VERSION "HNNBNNNYNNNNNNNNNNNNNNNNNNNNNNNNNNNNNNNNNN/4/%%%/4/'%**4NNN///"

NS_ :

BS_:

BU_: AEM BAP_Tester E_Sound FBK FLA Gateway Gateway_PAG ISE MRR_HL MRR_HR NightVision RDK SAK SAK2 SCR STH_MLBevo TopView

BO_ 1529 RDK_02: 8 RDK
 SG_ RDK_FMVSS138_Lampe : 12|1@1+ (1.0,0.0) [0.0|1] ""  Gateway,Gateway_PAG
 SG_ RDK_FMVSS138_MIL : 13|1@1+ (1.0,0.0) [0.0|1] ""  Gateway,Gateway_PAG
 SG_ RDK_Kalibrierung : 14|1@1+ (1.0,0.0) [0.0|1] ""  Gateway,Gateway_PAG
 SG_ RDK_Reifendruck_Lampe : 15|1@1+ (1.0,0.0) [0.0|1] ""  Gateway,Gateway_PAG
 SG_ RDK_Warnungen_02 : 16|5@1+ (1.0,0.0) [0.0|31] ""  Gateway,Gateway_PAG
 SG_ RDK_angelernt : 22|1@1+ (1.0,0.0) [0.0|1] ""  Gateway,Gateway_PAG
 SG_ RDK_Reifentemperatur_Lampe : 23|1@1+ (1.0,0.0) [0.0|1] ""  Gateway,Gateway_PAG
 SG_ RDK_RS_aktiv : 24|1@1+ (1.0,0.0) [0.0|1] ""  Gateway,Gateway_PAG
 SG_ RDK_Text_7 : 25|1@1+ (1.0,0.0) [0.0|1] ""  Gateway,Gateway_PAG
 SG_ RDK_W_1_Reifen_HL : 56|1@1+ (1.0,0.0) [0.0|1] ""  Gateway,Gateway_PAG
 SG_ RDK_W_1_Reifen_HR : 57|1@1+ (1.0,0.0) [0.0|1] ""  Gateway,Gateway_PAG
 SG_ RDK_W_1_Reifen_VL : 58|1@1+ (1.0,0.0) [0.0|1] ""  Gateway,Gateway_PAG
 SG_ RDK_W_1_Reifen_VR : 59|1@1+ (1.0,0.0) [0.0|1] ""  Gateway,Gateway_PAG
 SG_ RDK_W_2_Reifen_HL : 60|1@1+ (1.0,0.0) [0.0|1] ""  Gateway,Gateway_PAG
 SG_ RDK_W_2_Reifen_HR : 61|1@1+ (1.0,0.0) [0.0|1] ""  Gateway,Gateway_PAG
 SG_ RDK_W_2_Reifen_VL : 62|1@1+ (1.0,0.0) [0.0|1] ""  Gateway,Gateway_PAG
 SG_ RDK_W_2_Reifen_VR : 63|1@1+ (1.0,0.0) [0.0|1] ""  Gateway,Gateway_PAG

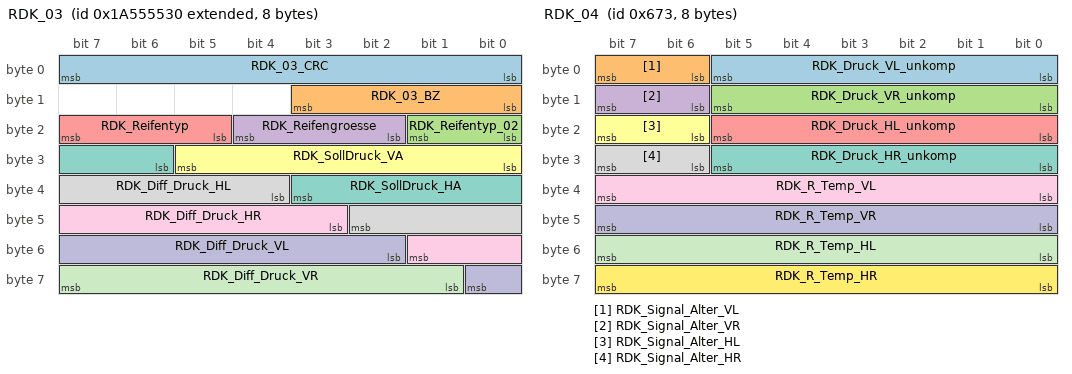
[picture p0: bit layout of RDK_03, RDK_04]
BO_ 2589283632 RDK_03: 8 RDK
 SG_ RDK_03_CRC : 0|8@1+ (1,0) [0|255] ""  Gateway,Gateway_PAG
 SG_ RDK_03_BZ : 8|4@1+ (1,0) [0|15] ""  Gateway,Gateway_PAG
 SG_ RDK_Reifentyp_02 : 16|2@1+ (1.0,0.0) [0.0|3] ""  Gateway,Gateway_PAG
 SG_ RDK_Reifengroesse : 18|3@1+ (1.0,0.0) [0.0|7] ""  Gateway,Gateway_PAG
 SG_ RDK_Reifentyp : 21|3@1+ (1.0,0.0) [0.0|7] ""  Gateway,Gateway_PAG
 SG_ RDK_SollDruck_VA : 24|6@1+ (0.1,0) [0.0|6.2] "Unit_Bar"  Gateway,Gateway_PAG
 SG_ RDK_SollDruck_HA : 30|6@1+ (0.1,0) [0.0|6.2] "Unit_Bar"  Gateway,Gateway_PAG
 SG_ RDK_Diff_Druck_HL : 36|7@1+ (0.1,-6.3) [-6.3|6.3] "Unit_Bar"  Gateway,Gateway_PAG
 SG_ RDK_Diff_Druck_HR : 43|7@1+ (0.1,-6.3) [-6.3|6.3] "Unit_Bar"  Gateway,Gateway_PAG
 SG_ RDK_Diff_Druck_VL : 50|7@1+ (0.1,-6.3) [-6.3|6.3] "Unit_Bar"  Gateway,Gateway_PAG
 SG_ RDK_Diff_Druck_VR : 57|7@1+ (0.1,-6.3) [-6.3|6.3] "Unit_Bar"  Gateway,Gateway_PAG

BO_ 1651 RDK_04: 8 RDK
 SG_ RDK_Druck_VL_unkomp : 0|6@1+ (0.1,0) [0.0|6.2] "Unit_Bar"  Gateway,Gateway_PAG
 SG_ RDK_Signal_Alter_VL : 6|2@1+ (1.0,0.0) [0.0|3] ""  Gateway,Gateway_PAG
 SG_ RDK_Druck_VR_unkomp : 8|6@1+ (0.1,0) [0.0|6.2] "Unit_Bar"  Gateway,Gateway_PAG
 SG_ RDK_Signal_Alter_VR : 14|2@1+ (1.0,0.0) [0.0|3] ""  Gateway,Gateway_PAG
 SG_ RDK_Druck_HL_unkomp : 16|6@1+ (0.1,0) [0.0|6.2] "Unit_Bar"  Gateway,Gateway_PAG
 SG_ RDK_Signal_Alter_HL : 22|2@1+ (1.0,0.0) [0.0|3] ""  Gateway,Gateway_PAG
 SG_ RDK_Druck_HR_unkomp : 24|6@1+ (0.1,0) [0.0|6.2] "Unit_Bar"  Gateway,Gateway_PAG
 SG_ RDK_Signal_Alter_HR : 30|2@1+ (1.0,0.0) [0.0|3] ""  Gateway,Gateway_PAG
 SG_ RDK_R_Temp_VL : 32|8@1+ (1,-60) [-60|193] "Unit_DegreCelsi"  Gateway,Gateway_PAG
 SG_ RDK_R_Temp_VR : 40|8@1+ (1,-60) [-60|193] "Unit_DegreCelsi"  Gateway,Gateway_PAG
 SG_ RDK_R_Temp_HL : 48|8@1+ (1,-60) [-60|193] "Unit_DegreCelsi"  Gateway,Gateway_PAG
 SG_ RDK_R_Temp_HR : 56|8@1+ (1,-60) [-60|193] "Unit_DegreCelsi"  Gateway,Gateway_PAG

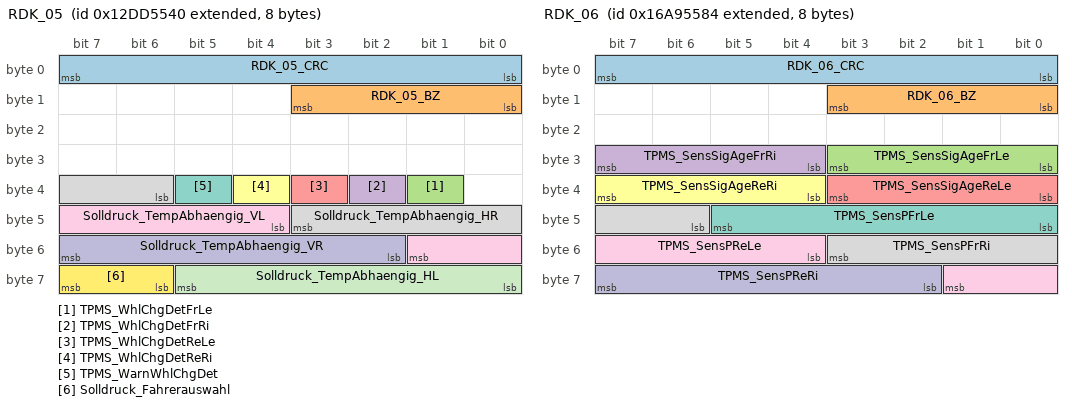
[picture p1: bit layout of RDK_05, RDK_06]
BO_ 2463978816 RDK_05: 8 RDK
 SG_ RDK_05_CRC : 0|8@1+ (1,0) [0|255] ""  Gateway,Gateway_PAG
 SG_ RDK_05_BZ : 8|4@1+ (1,0) [0|15] ""  Gateway,Gateway_PAG
 SG_ TPMS_WhlChgDetFrLe : 33|1@1+ (1.0,0.0) [0.0|1] ""  Gateway,Gateway_PAG
 SG_ TPMS_WhlChgDetFrRi : 34|1@1+ (1.0,0.0) [0.0|1] ""  Gateway,Gateway_PAG
 SG_ TPMS_WhlChgDetReLe : 35|1@1+ (1.0,0.0) [0.0|1] ""  Gateway,Gateway_PAG
 SG_ TPMS_WhlChgDetReRi : 36|1@1+ (1.0,0.0) [0.0|1] ""  Gateway,Gateway_PAG
 SG_ TPMS_WarnWhlChgDet : 37|1@1+ (1.0,0.0) [0.0|1] ""  Gateway,Gateway_PAG
 SG_ Solldruck_TempAbhaengig_HR : 38|6@1+ (0.1,0) [0.0|6.2] "Unit_Bar"  Gateway,Gateway_PAG
 SG_ Solldruck_TempAbhaengig_VL : 44|6@1+ (0.1,0) [0.0|6.2] "Unit_Bar"  Gateway,Gateway_PAG
 SG_ Solldruck_TempAbhaengig_VR : 50|6@1+ (0.1,0) [0.0|6.2] "Unit_Bar"  Gateway,Gateway_PAG
 SG_ Solldruck_TempAbhaengig_HL : 56|6@1+ (0.1,0) [0.0|6.2] "Unit_Bar"  Gateway,Gateway_PAG
 SG_ Solldruck_Fahrerauswahl : 62|2@1+ (1.0,0.0) [0.0|3] ""  Gateway,Gateway_PAG

BO_ 2527679876 RDK_06: 8 RDK
 SG_ RDK_06_CRC : 0|8@1+ (1,0) [0|255] ""  Gateway,Gateway_PAG
 SG_ RDK_06_BZ : 8|4@1+ (1,0) [0|15] ""  Gateway,Gateway_PAG
 SG_ TPMS_SensSigAgeFrLe : 24|4@1+ (1,0) [0|10] "Unit_Minut"  Gateway,Gateway_PAG
 SG_ TPMS_SensSigAgeFrRi : 28|4@1+ (1,0) [0|10] "Unit_Minut"  Gateway,Gateway_PAG
 SG_ TPMS_SensSigAgeReLe : 32|4@1+ (1,0) [0|10] "Unit_Minut"  Gateway,Gateway_PAG
 SG_ TPMS_SensSigAgeReRi : 36|4@1+ (1,0) [0|10] "Unit_Minut"  Gateway,Gateway_PAG
 SG_ TPMS_SensPFrLe : 40|6@1+ (0.1,0) [0.0|6.2] "Unit_Bar"  Gateway,Gateway_PAG
 SG_ TPMS_SensPFrRi : 46|6@1+ (0.1,0) [0.0|6.2] "Unit_Bar"  Gateway,Gateway_PAG
 SG_ TPMS_SensPReLe : 52|6@1+ (0.1,0) [0.0|6.2] "Unit_Bar"  Gateway,Gateway_PAG
 SG_ TPMS_SensPReRi : 58|6@1+ (0.1,0) [0.0|6.2] "Unit_Bar"  Gateway,Gateway_PAG

BO_ 1711 Rear_View_01: 8 TopView
 SG_ RV_Video_on : 0|1@1+ (1.0,0.0) [0.0|1] ""  Gateway,Gateway_PAG
 SG_ RV_Dark_Screen : 1|1@1+ (1.0,0.0) [0.0|1] ""  Gateway,Gateway_PAG
 SG_ RV_HMI_Mode : 2|2@1+ (1.0,0.0) [0.0|3] ""  Gateway,Gateway_PAG
 SG_ RV_GL_side : 4|2@1+ (1.0,0.0) [0.0|3] ""  Gateway,Gateway_PAG
 SG_ RV_System_aktiv : 6|1@1+ (1.0,0.0) [0.0|1] ""  Gateway,Gateway_PAG
 SG_ RV_Reinigung_Anf : 7|1@1+ (1.0,0.0) [0.0|1] ""  Gateway,Gateway_PAG
 SG_ RV_Settings_enabled : 8|1@1+ (1.0,0.0) [0.0|1] ""  Gateway,Gateway_PAG
 SG_ RV_Menu_Item : 9|2@1+ (1.0,0.0) [0.0|3] ""  Gateway,Gateway_PAG
 SG_ SV_Video_on : 11|1@1+ (1.0,0.0) [0.0|1] ""  Gateway,Gateway_PAG
 SG_ RV_Calib_Fehler : 12|1@1+ (1.0,0.0) [0.0|1] ""  Gateway,Gateway_PAG
 SG_ RV_GL_Trailer_connect : 13|1@1+ (1.0,0.0) [0.0|1] ""  Gateway,Gateway_PAG
 SG_ RV_GL_Trunk_open : 14|1@1+ (1.0,0.0) [0.0|1] ""  Gateway,Gateway_PAG
 SG_ RV_GL_LWS_Fehler : 15|1@1+ (1.0,0.0) [0.0|1] ""  Gateway,Gateway_PAG
 SG_ RV_Helligkeit : 16|7@1+ (1,0) [0|100] "Unit_PerCent"  Gateway,Gateway_PAG
 SG_ ZFAS_Umfeldbeleuchtung_Anf : 23|1@1+ (1.0,0.0) [0.0|1] ""  Gateway,Gateway_PAG
 SG_ RV_Kontrast : 24|7@1+ (1,0) [0|100] "Unit_PerCent"  Gateway,Gateway_PAG
 SG_ RV_Farbe : 32|7@1+ (1,0) [0|100] "Unit_PerCent"  Gateway,Gateway_PAG

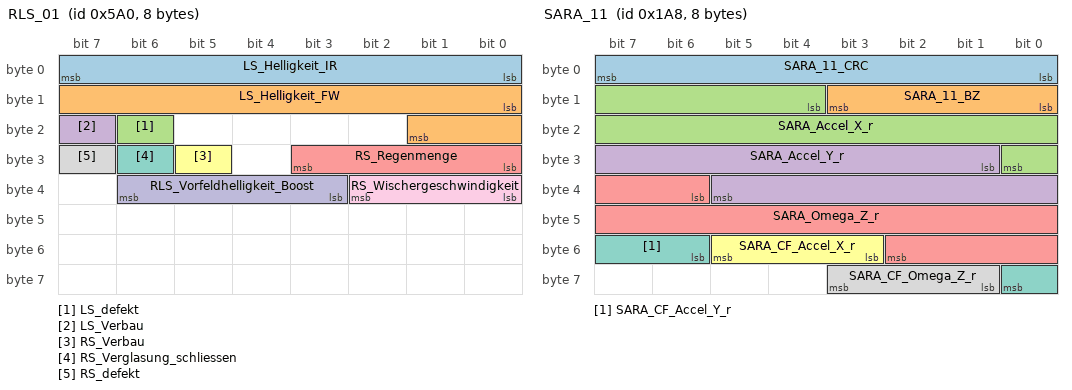
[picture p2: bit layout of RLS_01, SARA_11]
BO_ 1440 RLS_01: 8 Gateway
 SG_ LS_Helligkeit_IR : 0|8@1+ (400,0) [0|101200] "Unit_Lux"  MRR_HL,MRR_HR,NightVision
 SG_ LS_Helligkeit_FW : 8|10@1+ (6,0) [0|6126] "Unit_Lux"  MRR_HL,MRR_HR,NightVision
 SG_ LS_defekt : 22|1@1+ (1.0,0.0) [0.0|1] ""  MRR_HL,MRR_HR,NightVision
 SG_ LS_Verbau : 23|1@1+ (1.0,0.0) [0.0|1] ""  MRR_HL,MRR_HR,NightVision
 SG_ RS_Regenmenge : 24|4@1+ (1.0,0.0) [0.0|15] ""  Vector__XXX
 SG_ RS_Verbau : 29|1@1+ (1.0,0.0) [0.0|1] ""  NightVision
 SG_ RS_Verglasung_schliessen : 30|1@1+ (1.0,0.0) [0.0|1] ""  Vector__XXX
 SG_ RS_defekt : 31|1@1+ (1.0,0.0) [0.0|1] ""  NightVision
 SG_ RS_Wischergeschwindigkeit : 32|3@1+ (1.0,0.0) [0.0|7] ""  NightVision
 SG_ RLS_Vorfeldhelligkeit_Boost : 35|4@1+ (1.0,0.0) [0.0|15] ""  Vector__XXX

BO_ 1528 SAK_01: 8 ISE
 SG_ SAK_Charisma_FahrPr : 16|4@1+ (1.0,0.0) [0.0|15] ""  Gateway,Gateway_PAG
 SG_ SAK_Charisma_Status : 20|2@1+ (1.0,0.0) [0.0|3] ""  Gateway,Gateway_PAG

BO_ 424 SARA_11: 8 Gateway
 SG_ SARA_11_CRC : 0|8@1+ (1,0) [0|255] ""  Vector__XXX
 SG_ SARA_11_BZ : 8|4@1+ (1,0) [0|15] ""  Vector__XXX
 SG_ SARA_Accel_X_r : 12|13@1+ (0.16,-655.36) [-655.20|655.04] "Unit_MeterPerSeconSquar"  E_Sound,ISE,TopView
 SG_ SARA_Accel_Y_r : 25|13@1+ (0.16,-655.36) [-655.20|655.04] "Unit_MeterPerSeconSquar"  TopView
 SG_ SARA_Omega_Z_r : 38|13@1+ (0.08,-327.68) [-327.60|327.52] "Unit_DegreOfArcPerSecon"  FLA,NightVision,TopView
 SG_ SARA_CF_Accel_X_r : 51|3@1+ (1.0,0.0) [0.0|7] ""  TopView
 SG_ SARA_CF_Accel_Y_r : 54|3@1+ (1.0,0.0) [0.0|7] ""  TopView
 SG_ SARA_CF_Omega_Z_r : 57|3@1+ (1.0,0.0) [0.0|7] ""  FLA,NightVision,TopView

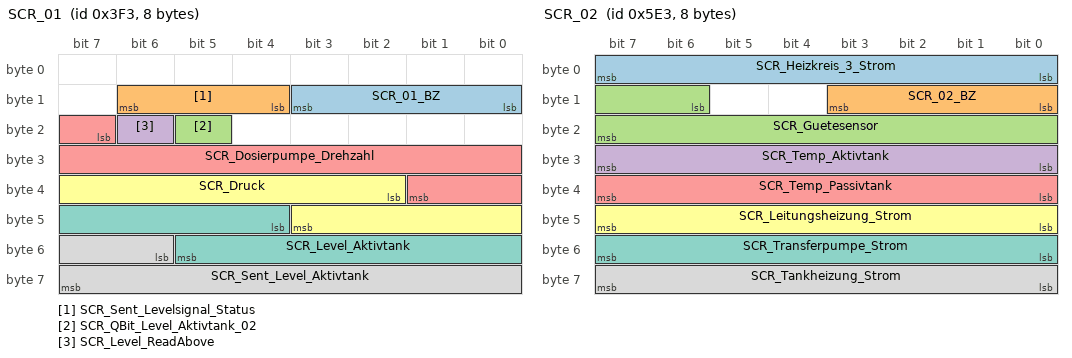
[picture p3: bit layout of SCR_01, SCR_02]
BO_ 1011 SCR_01: 8 SCR
 SG_ SCR_01_BZ : 8|4@1+ (1,0) [0|15] ""  Gateway,Gateway_PAG
 SG_ SCR_Sent_Levelsignal_Status : 12|3@1+ (1.0,0.0) [0.0|7] ""  Gateway,Gateway_PAG
 SG_ SCR_QBit_Level_Aktivtank_02 : 21|1@1+ (1.0,0.0) [0.0|1] ""  Gateway,Gateway_PAG
 SG_ SCR_Level_ReadAbove : 22|1@1+ (1.0,0.0) [0.0|1] ""  Gateway,Gateway_PAG
 SG_ SCR_Dosierpumpe_Drehzahl : 23|11@1+ (4,-4080) [-4080|4100] "Unit_MinutInver"  Gateway,Gateway_PAG
 SG_ SCR_Druck : 34|10@1+ (5,0) [0|5000] "Unit_MilliVolt"  Gateway,Gateway_PAG
 SG_ SCR_Level_Aktivtank : 44|10@1+ (5,0) [0|5000] "Unit_MilliVolt"  Gateway,Gateway_PAG
 SG_ SCR_Sent_Level_Aktivtank : 54|10@1+ (1,-20) [-20|1000] "Unit_MilliMeter"  Gateway,Gateway_PAG

BO_ 1507 SCR_02: 8 SCR
 SG_ SCR_Heizkreis_3_Strom : 0|8@1+ (0.1,0) [0.0|14.0] "Unit_Amper"  Gateway,Gateway_PAG
 SG_ SCR_02_BZ : 8|4@1+ (1,0) [0|15] ""  Gateway,Gateway_PAG
 SG_ SCR_Guetesensor : 14|10@1+ (5,0) [0|5000] "Unit_MilliVolt"  Gateway,Gateway_PAG
 SG_ SCR_Temp_Aktivtank : 24|8@1+ (20,0) [0|5000] "Unit_MilliVolt"  Gateway,Gateway_PAG
 SG_ SCR_Temp_Passivtank : 32|8@1+ (20,0) [0|5000] "Unit_MilliVolt"  Gateway,Gateway_PAG
 SG_ SCR_Leitungsheizung_Strom : 40|8@1+ (0.1,0) [0.0|14.0] "Unit_Amper"  Gateway,Gateway_PAG
 SG_ SCR_Transferpumpe_Strom : 48|8@1+ (0.1,0) [0.0|14.0] "Unit_Amper"  Gateway,Gateway_PAG
 SG_ SCR_Tankheizung_Strom : 56|8@1+ (0.1,0) [0.0|14.0] "Unit_Amper"  Gateway,Gateway_PAG

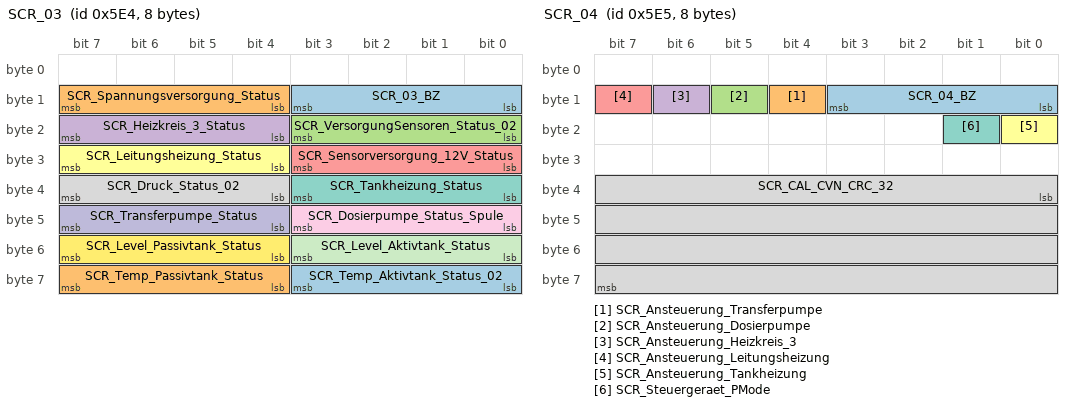
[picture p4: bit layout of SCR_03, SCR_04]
BO_ 1508 SCR_03: 8 SCR
 SG_ SCR_03_BZ : 8|4@1+ (1,0) [0|15] ""  Gateway,Gateway_PAG
 SG_ SCR_Spannungsversorgung_Status : 12|4@1+ (1.0,0.0) [0.0|15] ""  Gateway,Gateway_PAG
 SG_ SCR_VersorgungSensoren_Status_02 : 16|4@1+ (1.0,0.0) [0.0|15] ""  Gateway,Gateway_PAG
 SG_ SCR_Heizkreis_3_Status : 20|4@1+ (1.0,0.0) [0.0|15] ""  Gateway,Gateway_PAG
 SG_ SCR_Sensorversorgung_12V_Status : 24|4@1+ (1.0,0.0) [0.0|15] ""  Gateway,Gateway_PAG
 SG_ SCR_Leitungsheizung_Status : 28|4@1+ (1.0,0.0) [0.0|15] ""  Gateway,Gateway_PAG
 SG_ SCR_Tankheizung_Status : 32|4@1+ (1.0,0.0) [0.0|15] ""  Gateway,Gateway_PAG
 SG_ SCR_Druck_Status_02 : 36|4@1+ (1.0,0.0) [0.0|15] ""  Gateway,Gateway_PAG
 SG_ SCR_Dosierpumpe_Status_Spule : 40|4@1+ (1.0,0.0) [0.0|15] ""  Gateway,Gateway_PAG
 SG_ SCR_Transferpumpe_Status : 44|4@1+ (1.0,0.0) [0.0|15] ""  Gateway,Gateway_PAG
 SG_ SCR_Level_Aktivtank_Status : 48|4@1+ (1.0,0.0) [0.0|15] ""  Gateway,Gateway_PAG
 SG_ SCR_Level_Passivtank_Status : 52|4@1+ (1.0,0.0) [0.0|15] ""  Gateway,Gateway_PAG
 SG_ SCR_Temp_Aktivtank_Status_02 : 56|4@1+ (1.0,0.0) [0.0|15] ""  Gateway,Gateway_PAG
 SG_ SCR_Temp_Passivtank_Status : 60|4@1+ (1.0,0.0) [0.0|15] ""  Gateway,Gateway_PAG

BO_ 1509 SCR_04: 8 SCR
 SG_ SCR_04_BZ : 8|4@1+ (1,0) [0|15] ""  Gateway,Gateway_PAG
 SG_ SCR_Ansteuerung_Transferpumpe : 12|1@1+ (1.0,0.0) [0.0|1] ""  Gateway,Gateway_PAG
 SG_ SCR_Ansteuerung_Dosierpumpe : 13|1@1+ (1.0,0.0) [0.0|1] ""  Gateway,Gateway_PAG
 SG_ SCR_Ansteuerung_Heizkreis_3 : 14|1@1+ (1.0,0.0) [0.0|1] ""  Gateway,Gateway_PAG
 SG_ SCR_Ansteuerung_Leitungsheizung : 15|1@1+ (1.0,0.0) [0.0|1] ""  Gateway,Gateway_PAG
 SG_ SCR_Ansteuerung_Tankheizung : 16|1@1+ (1.0,0.0) [0.0|1] ""  Gateway,Gateway_PAG
 SG_ SCR_Steuergeraet_PMode : 17|1@1+ (1.0,0.0) [0.0|1] ""  Gateway,Gateway_PAG
 SG_ SCR_CAL_CVN_CRC_32 : 32|32@1+ (1.0,0.0) [0.0|4294967295] ""  Gateway,Gateway_PAG

BO_ 1526 SCR_05: 8 SCR
 SG_ SCR_05_BZ : 8|4@1+ (1,0) [0|15] ""  Gateway,Gateway_PAG
 SG_ SCR_Level_Aktivtank_OOR4Quality : 12|1@1+ (1.0,0.0) [0.0|1] ""  Gateway,Gateway_PAG
 SG_ SCR_Level_Aktivtank_OOR_minus : 13|1@1+ (1.0,0.0) [0.0|1] ""  Gateway,Gateway_PAG
 SG_ SCR_Sent_1_Signalstatus : 14|2@1+ (1.0,0.0) [0.0|3] ""  Gateway,Gateway_PAG
 SG_ SCR_Sent_1_elektrischer_Status : 16|4@1+ (1.0,0.0) [0.0|15] ""  Gateway,Gateway_PAG
 SG_ SCR_Sent_Levelsensor : 20|3@1+ (1.0,0.0) [0.0|7] ""  Gateway,Gateway_PAG
 SG_ SCR_Sent_Qualitaetssensor : 23|3@1+ (1.0,0.0) [0.0|7] ""  Gateway,Gateway_PAG
 SG_ SCR_Sent_Temperatursensor : 26|3@1+ (1.0,0.0) [0.0|7] ""  Gateway,Gateway_PAG
 SG_ SCR_DEF_Qualitaet_Medium : 29|1@1+ (1.0,0.0) [0.0|1] ""  Gateway,Gateway_PAG
 SG_ SCR_QBit_Qualitaet : 30|1@1+ (1.0,0.0) [0.0|1] ""  Gateway,Gateway_PAG
 SG_ SCR_Sent_2_Signalstatus : 31|2@1+ (1.0,0.0) [0.0|3] ""  Gateway,Gateway_PAG
 SG_ SCR_Temp_DEF2_Sensor_Status : 33|3@1+ (1.0,0.0) [0.0|7] ""  Gateway,Gateway_PAG
 SG_ SCR_Sent_2_elektrischer_Status : 36|4@1+ (1.0,0.0) [0.0|15] ""  Gateway,Gateway_PAG
 SG_ SCR_HAL_Sensorik_Status : 40|4@1+ (1.0,0.0) [0.0|15] ""  Gateway,Gateway_PAG
 SG_ SCR_Steuergeraet_Heizung_Status : 48|2@1+ (1.0,0.0) [0.0|3] ""  Gateway,Gateway_PAG
 SG_ SCR_Steuergeraet_Pumpe_Status : 50|2@1+ (1.0,0.0) [0.0|3] ""  Gateway,Gateway_PAG
 SG_ SCR_Steuergeraet_Relais_Status : 52|2@1+ (1.0,0.0) [0.0|3] ""  Gateway,Gateway_PAG
 SG_ SCR_Steuergeraet_Bus_Status : 56|2@1+ (1.0,0.0) [0.0|3] ""  Gateway,Gateway_PAG
 SG_ SCR_ECU_Datensatz_Status : 60|2@1+ (1.0,0.0) [0.0|3] ""  Gateway,Gateway_PAG
 SG_ SCR_Steuergeraet_Defekt_Status : 62|2@1+ (1.0,0.0) [0.0|3] ""  Gateway,Gateway_PAG

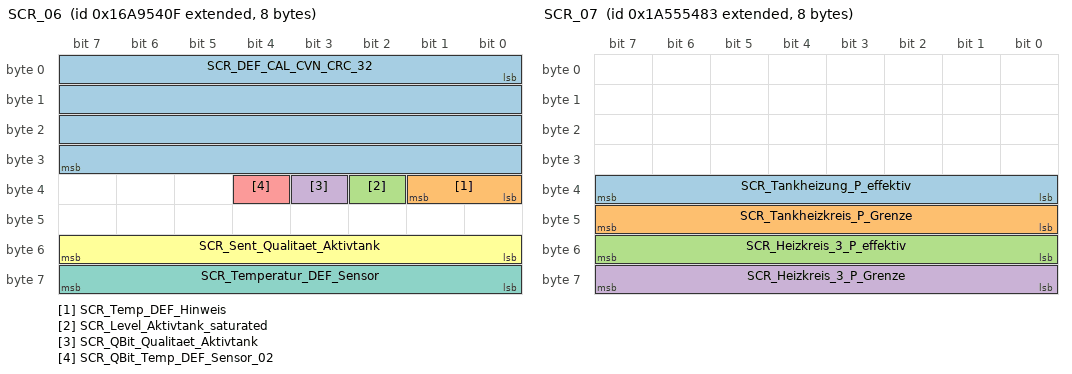
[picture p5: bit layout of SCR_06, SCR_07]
BO_ 2527679503 SCR_06: 8 SCR
 SG_ SCR_DEF_CAL_CVN_CRC_32 : 0|32@1+ (1.0,0.0) [0.0|4294967295] ""  Gateway,Gateway_PAG
 SG_ SCR_Temp_DEF_Hinweis : 32|2@1+ (1.0,0.0) [0.0|3] ""  Gateway,Gateway_PAG
 SG_ SCR_Level_Aktivtank_saturated : 34|1@1+ (1.0,0.0) [0.0|1] ""  Gateway,Gateway_PAG
 SG_ SCR_QBit_Qualitaet_Aktivtank : 35|1@1+ (1.0,0.0) [0.0|1] ""  Gateway,Gateway_PAG
 SG_ SCR_QBit_Temp_DEF_Sensor_02 : 36|1@1+ (1.0,0.0) [0.0|1] ""  Gateway,Gateway_PAG
 SG_ SCR_Sent_Qualitaet_Aktivtank : 48|8@1+ (0.5,-20) [-20.0|100.0] "Unit_PerCent"  Gateway,Gateway_PAG
 SG_ SCR_Temperatur_DEF_Sensor : 56|8@1+ (0.5,-45) [-45.0|80.0] "Unit_DegreCelsi"  Gateway,Gateway_PAG

BO_ 2589283459 SCR_07: 8 SCR
 SG_ SCR_Tankheizung_P_effektiv : 32|8@1+ (1,0) [0|250] "Unit_Watt"  Gateway,Gateway_PAG
 SG_ SCR_Tankheizkreis_P_Grenze : 40|8@1+ (1,0) [0|250] "Unit_Watt"  Gateway,Gateway_PAG
 SG_ SCR_Heizkreis_3_P_effektiv : 48|8@1+ (1,0) [0|250] "Unit_Watt"  Gateway,Gateway_PAG
 SG_ SCR_Heizkreis_3_P_Grenze : 56|8@1+ (1,0) [0|250] "Unit_Watt"  Gateway,Gateway_PAG

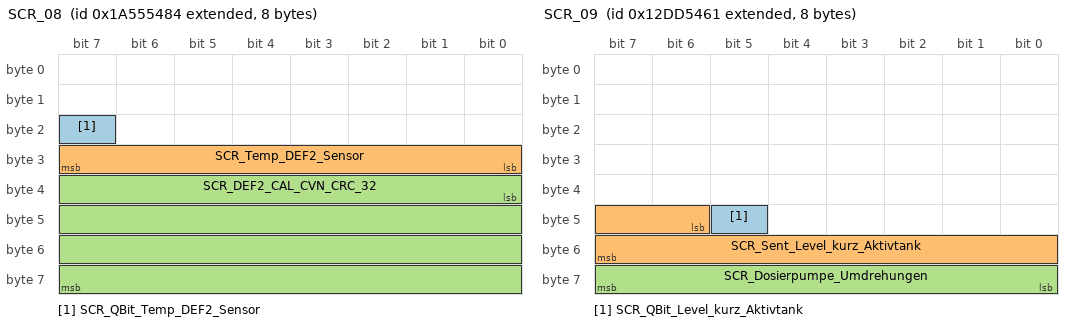
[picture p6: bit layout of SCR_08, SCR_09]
BO_ 2589283460 SCR_08: 8 SCR
 SG_ SCR_QBit_Temp_DEF2_Sensor : 23|1@1+ (1.0,0.0) [0.0|1] ""  Gateway,Gateway_PAG
 SG_ SCR_Temp_DEF2_Sensor : 24|8@1+ (0.5,-45) [-45.0|80.0] "Unit_DegreCelsi"  Gateway,Gateway_PAG
 SG_ SCR_DEF2_CAL_CVN_CRC_32 : 32|32@1+ (1.0,0.0) [0.0|4294967295] ""  Gateway,Gateway_PAG

BO_ 2463978593 SCR_09: 8 SCR
 SG_ SCR_QBit_Level_kurz_Aktivtank : 45|1@1+ (1.0,0.0) [0.0|1] ""  Gateway,Gateway_PAG
 SG_ SCR_Sent_Level_kurz_Aktivtank : 46|10@1+ (1,-20) [-20|1000] "Unit_MilliMeter"  Gateway,Gateway_PAG
 SG_ SCR_Dosierpumpe_Umdrehungen : 56|8@1+ (1,0) [0|253] "Unit_Rev"  Gateway,Gateway_PAG

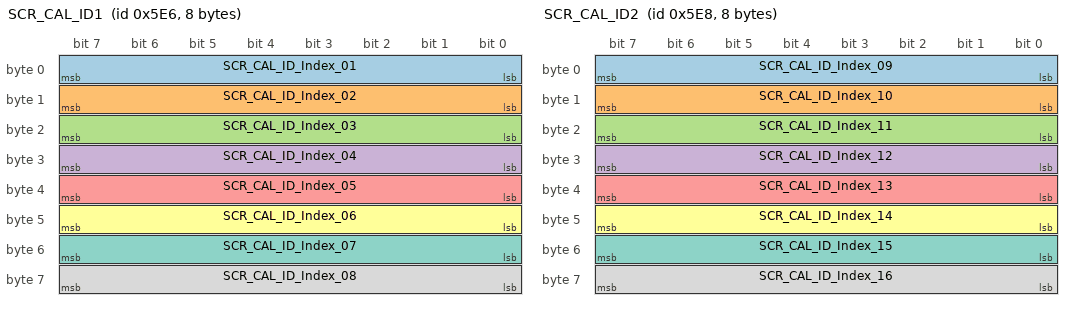
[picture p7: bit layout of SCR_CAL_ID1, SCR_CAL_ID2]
BO_ 1510 SCR_CAL_ID1: 8 SCR
 SG_ SCR_CAL_ID_Index_01 : 0|8@1+ (1.0,0.0) [0.0|255] ""  Gateway,Gateway_PAG
 SG_ SCR_CAL_ID_Index_02 : 8|8@1+ (1.0,0.0) [0.0|255] ""  Gateway,Gateway_PAG
 SG_ SCR_CAL_ID_Index_03 : 16|8@1+ (1.0,0.0) [0.0|255] ""  Gateway,Gateway_PAG
 SG_ SCR_CAL_ID_Index_04 : 24|8@1+ (1.0,0.0) [0.0|255] ""  Gateway,Gateway_PAG
 SG_ SCR_CAL_ID_Index_05 : 32|8@1+ (1.0,0.0) [0.0|255] ""  Gateway,Gateway_PAG
 SG_ SCR_CAL_ID_Index_06 : 40|8@1+ (1.0,0.0) [0.0|255] ""  Gateway,Gateway_PAG
 SG_ SCR_CAL_ID_Index_07 : 48|8@1+ (1.0,0.0) [0.0|255] ""  Gateway,Gateway_PAG
 SG_ SCR_CAL_ID_Index_08 : 56|8@1+ (1.0,0.0) [0.0|255] ""  Gateway,Gateway_PAG

BO_ 1512 SCR_CAL_ID2: 8 SCR
 SG_ SCR_CAL_ID_Index_09 : 0|8@1+ (1.0,0.0) [0.0|255] ""  Gateway,Gateway_PAG
 SG_ SCR_CAL_ID_Index_10 : 8|8@1+ (1.0,0.0) [0.0|255] ""  Gateway,Gateway_PAG
 SG_ SCR_CAL_ID_Index_11 : 16|8@1+ (1.0,0.0) [0.0|255] ""  Gateway,Gateway_PAG
 SG_ SCR_CAL_ID_Index_12 : 24|8@1+ (1.0,0.0) [0.0|255] ""  Gateway,Gateway_PAG
 SG_ SCR_CAL_ID_Index_13 : 32|8@1+ (1.0,0.0) [0.0|255] ""  Gateway,Gateway_PAG
 SG_ SCR_CAL_ID_Index_14 : 40|8@1+ (1.0,0.0) [0.0|255] ""  Gateway,Gateway_PAG
 SG_ SCR_CAL_ID_Index_15 : 48|8@1+ (1.0,0.0) [0.0|255] ""  Gateway,Gateway_PAG
 SG_ SCR_CAL_ID_Index_16 : 56|8@1+ (1.0,0.0) [0.0|255] ""  Gateway,Gateway_PAG

BO_ 2589283497 SCR_DEF2_CAL_ID1: 8 SCR
 SG_ SCR_DEF2_CAL_ID_Index01 : 0|32@1+ (1.0,0.0) [0.0|4294967295] ""  Gateway,Gateway_PAG
 SG_ SCR_DEF2_CAL_ID_Index02 : 32|32@1+ (1.0,0.0) [0.0|4294967295] ""  Gateway,Gateway_PAG

BO_ 2589283498 SCR_DEF2_CAL_ID2: 8 SCR
 SG_ SCR_DEF2_CAL_ID_Index03 : 0|32@1+ (1.0,0.0) [0.0|4294967295] ""  Gateway,Gateway_PAG
 SG_ SCR_DEF2_CAL_ID_Index04 : 32|32@1+ (1.0,0.0) [0.0|4294967295] ""  Gateway,Gateway_PAG

BO_ 2589283413 SCR_DEF_CAL_ID1: 8 SCR
 SG_ SCR_DEF_CAL_ID_Index01 : 0|32@1+ (1.0,0.0) [0.0|4294967295] ""  Gateway,Gateway_PAG
 SG_ SCR_DEF_CAL_ID_Index02 : 32|32@1+ (1.0,0.0) [0.0|4294967295] ""  Gateway,Gateway_PAG

BO_ 2589283414 SCR_DEF_CAL_ID2: 8 SCR
 SG_ SCR_DEF_CAL_ID_Index03 : 0|32@1+ (1.0,0.0) [0.0|4294967295] ""  Gateway,Gateway_PAG
 SG_ SCR_DEF_CAL_ID_Index04 : 32|32@1+ (1.0,0.0) [0.0|4294967295] ""  Gateway,Gateway_PAG

BO_ 980 SMLS_01: 8 Gateway
 SG_ SMLS_01_CRC : 0|8@1+ (1,0) [0|255] ""  Vector__XXX
 SG_ SMLS_01_BZ : 8|4@1+ (1,0) [0|15] ""  Vector__XXX
 SG_ BH_Blinker_li : 12|1@1+ (1.0,0.0) [0.0|1] ""  TopView
 SG_ BH_Blinker_re : 13|1@1+ (1.0,0.0) [0.0|1] ""  TopView
 SG_ BH_Lichthupe : 14|1@1+ (1.0,0.0) [0.0|1] ""  Vector__XXX
 SG_ BH_Fernlicht : 15|1@1+ (1.0,0.0) [0.0|1] ""  FLA
 SG_ WH_Tipwischen : 16|1@1+ (1.0,0.0) [0.0|1] ""  Vector__XXX
 SG_ WH_Intervall : 17|1@1+ (1.0,0.0) [0.0|1] ""  Vector__XXX
 SG_ WH_WischerStufe1 : 18|1@1+ (1.0,0.0) [0.0|1] ""  Vector__XXX
 SG_ WH_WischerStufe2 : 19|1@1+ (1.0,0.0) [0.0|1] ""  Vector__XXX
 SG_ WH_Frontwaschen : 20|1@1+ (1.0,0.0) [0.0|1] ""  Vector__XXX
 SG_ WH_Heckintervall : 21|1@1+ (1.0,0.0) [0.0|1] ""  Vector__XXX
 SG_ WH_Heckwaschen : 22|1@1+ (1.0,0.0) [0.0|1] ""  Vector__XXX
 SG_ WH_Intervallstufen : 23|4@1+ (1.0,0.0) [0.0|15] ""  Vector__XXX
 SG_ FAS_Taster : 27|1@1+ (1.0,0.0) [0.0|1] ""  Vector__XXX
 SG_ FAS_Taster_Fehler : 28|1@1+ (1.0,0.0) [0.0|1] ""  Vector__XXX
 SG_ SMLS_Hupe : 29|1@1+ (1.0,0.0) [0.0|1] ""  Vector__XXX
 SG_ LRH_On_Off : 30|2@1+ (1.0,0.0) [0.0|3] ""  Vector__XXX
 SG_ LRH_aktiv : 40|1@1+ (1.0,0.0) [0.0|1] ""  Vector__XXX
 SG_ SMLS_P_verriegelt_plausibel : 43|1@1+ (1.0,0.0) [0.0|1] ""  Vector__XXX
 SG_ WH_SRA : 44|1@1+ (1.0,0.0) [0.0|1] ""  Vector__XXX
 SG_ WH_Wischer_Fehler : 45|1@1+ (1.0,0.0) [0.0|1] ""  Vector__XXX
 SG_ BH_Blinker_Fehler : 46|1@1+ (1.0,0.0) [0.0|1] ""  Vector__XXX
 SG_ SMLS_PTT : 47|1@1+ (1.0,0.0) [0.0|1] ""  Vector__XXX
 SG_ WH_Tipwischen_lang : 48|1@1+ (1.0,0.0) [0.0|1] ""  Vector__XXX

BO_ 1710 Spiegel_01: 8 Gateway
 SG_ SP_FT_oben : 0|1@1+ (1.0,0.0) [0.0|1] ""  Vector__XXX
 SG_ SP_FT_unten : 1|1@1+ (1.0,0.0) [0.0|1] ""  Vector__XXX
 SG_ SP_FT_links : 2|1@1+ (1.0,0.0) [0.0|1] ""  Vector__XXX
 SG_ SP_FT_rechts : 3|1@1+ (1.0,0.0) [0.0|1] ""  Vector__XXX
 SG_ SP_BT_oben : 4|1@1+ (1.0,0.0) [0.0|1] ""  Vector__XXX
 SG_ SP_BT_unten : 5|1@1+ (1.0,0.0) [0.0|1] ""  Vector__XXX
 SG_ SP_BT_links : 6|1@1+ (1.0,0.0) [0.0|1] ""  Vector__XXX
 SG_ SP_BT_rechts : 7|1@1+ (1.0,0.0) [0.0|1] ""  Vector__XXX
 SG_ SP_abklappen : 8|1@1+ (1.0,0.0) [0.0|1] ""  Vector__XXX
 SG_ SP_anklappen : 9|1@1+ (1.0,0.0) [0.0|1] ""  Vector__XXX
 SG_ SP_normieren : 10|1@1+ (1.0,0.0) [0.0|1] ""  Vector__XXX
 SG_ SP_Hzg_Taster : 12|1@1+ (1.0,0.0) [0.0|1] ""  Vector__XXX
 SG_ SP_S_oben : 16|1@1+ (1.0,0.0) [0.0|1] ""  Vector__XXX
 SG_ SP_S_unten : 17|1@1+ (1.0,0.0) [0.0|1] ""  Vector__XXX
 SG_ SP_S_links : 18|1@1+ (1.0,0.0) [0.0|1] ""  Vector__XXX
 SG_ SP_S_rechts : 19|1@1+ (1.0,0.0) [0.0|1] ""  Vector__XXX
 SG_ SP_Auswahl_li : 20|1@1+ (1.0,0.0) [0.0|1] ""  Vector__XXX
 SG_ SP_Auswahl_re : 21|1@1+ (1.0,0.0) [0.0|1] ""  Vector__XXX
 SG_ SP_ARA_Status : 22|1@1+ (1.0,0.0) [0.0|1] ""  Vector__XXX
 SG_ SP_S_Klappen : 23|1@1+ (1.0,0.0) [0.0|1] ""  TopView
 SG_ SP_Verstellschalter_Fehler : 24|1@1+ (1.0,0.0) [0.0|1] ""  Vector__XXX

BO_ 1313 STH_01: 8 STH_MLBevo
 SG_ STH_Funk_ein : 0|1@1+ (1.0,0.0) [0.0|1] ""  Gateway,Gateway_PAG
 SG_ STH_Funk_aus : 1|1@1+ (1.0,0.0) [0.0|1] ""  Gateway,Gateway_PAG
 SG_ STH_Zusatzheizung : 2|1@1+ (1.0,0.0) [0.0|1] ""  Gateway,Gateway_PAG
 SG_ STH_LED : 3|1@1+ (1.0,0.0) [0.0|1] ""  Gateway,Gateway_PAG
 SG_ STH_Pumpe_ein : 4|1@1+ (1,0) [0|1] ""  Gateway,Gateway_PAG
 SG_ STH_Geblaese : 5|1@1+ (1.0,0.0) [0.0|1] ""  Gateway,Gateway_PAG
 SG_ STH_EKP_Anst : 6|1@1+ (1.0,0.0) [0.0|1] ""  Gateway,Gateway_PAG
 SG_ STH_Start_folgt : 7|1@1+ (1.0,0.0) [0.0|1] ""  Gateway,Gateway_PAG
 SG_ STH_Ventiloeffnungszeit : 8|6@1+ (1,0) [0|63] "Unit_Minut"  Gateway,Gateway_PAG
 SG_ STH_Ventil_Status : 14|1@1+ (1.0,0.0) [0.0|1] ""  Gateway,Gateway_PAG
 SG_ STH_Fehler_ElWaPu : 15|1@1+ (1.0,0.0) [0.0|1] ""  Gateway,Gateway_PAG
 SG_ STH_Waermeeintrag : 16|6@1+ (1,0) [0|63] "Unit_None"  Gateway,Gateway_PAG
 SG_ STH_Pumpen_Anf_extern : 22|1@1+ (1.0,0.0) [0.0|1] ""  Gateway,Gateway_PAG
 SG_ STH_KL_HUP : 23|1@1+ (1.0,0.0) [0.0|1] ""  Gateway,Gateway_PAG
 SG_ STH_KVS : 24|13@1+ (1,0) [0|8191] "Unit_MilliLiter"  Gateway,Gateway_PAG
 SG_ STH_Fehlerstatus : 37|3@1+ (1.0,0.0) [0.0|7] ""  Gateway,Gateway_PAG
 SG_ STH_Heizleistung : 40|8@1+ (1,0) [0|255] ""  Gateway,Gateway_PAG
 SG_ STH_Wassertemp : 48|8@1+ (0.75,-40) [-40.00|142.25] "Unit_DegreCelsi"  Gateway,Gateway_PAG
 SG_ STH_Texte : 56|3@1+ (1.0,0.0) [0.0|7] ""  Gateway,Gateway_PAG
 SG_ STH_Motorvorwaermung : 59|1@1+ (1.0,0.0) [0.0|1] ""  Gateway,Gateway_PAG
 SG_ STH_Servicemode : 60|1@1+ (1.0,0.0) [0.0|1] ""  Gateway,Gateway_PAG
 SG_ STH_war_aktiv : 61|1@1+ (1.0,0.0) [0.0|1] ""  Gateway,Gateway_PAG
 SG_ STH_KVS_Ueberlauf : 62|1@1+ (1.0,0.0) [0.0|1] ""  Gateway,Gateway_PAG
 SG_ STH_SH_ZH : 63|1@1+ (1.0,0.0) [0.0|1] ""  Gateway,Gateway_PAG

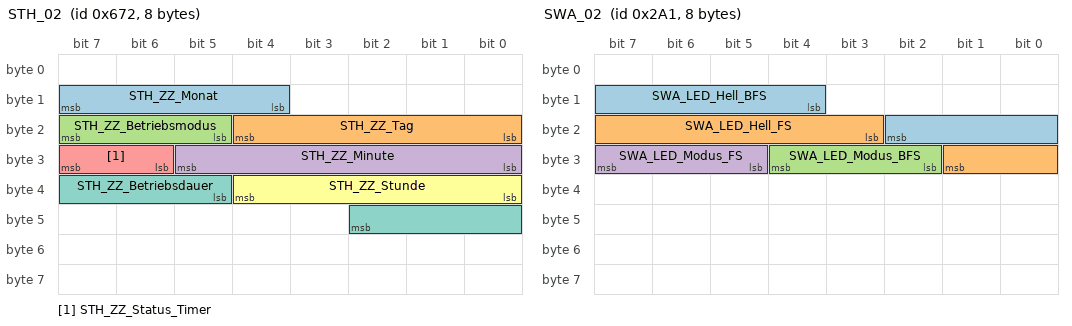
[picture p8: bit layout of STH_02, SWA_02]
BO_ 1650 STH_02: 8 STH_MLBevo
 SG_ STH_ZZ_Monat : 12|4@1+ (1,0) [1|12] ""  Gateway,Gateway_PAG
 SG_ STH_ZZ_Tag : 16|5@1+ (1,0) [1|31] "Unit_Day"  Gateway,Gateway_PAG
 SG_ STH_ZZ_Betriebsmodus : 21|3@1+ (1.0,0.0) [0.0|7] ""  Gateway,Gateway_PAG
 SG_ STH_ZZ_Minute : 24|6@1+ (1,0) [0|59] ""  Gateway,Gateway_PAG
 SG_ STH_ZZ_Status_Timer : 30|2@1+ (1.0,0.0) [0.0|3] ""  Gateway,Gateway_PAG
 SG_ STH_ZZ_Stunde : 32|5@1+ (1,0) [0|23] ""  Gateway,Gateway_PAG
 SG_ STH_ZZ_Betriebsdauer : 37|6@1+ (1,0) [0|63] "Unit_Minut"  Gateway,Gateway_PAG

BO_ 505 STP_03: 8 Gateway
 SG_ STP_03_CRC : 0|8@1+ (1,0) [0|255] ""  Vector__XXX
 SG_ STP_03_BZ : 8|4@1+ (1,0) [0|15] ""  Vector__XXX
 SG_ STP_Slave_Status : 12|4@1+ (1.0,0.0) [0.0|15] ""  Vector__XXX
 SG_ FZE_STP_Abschaltbedingung : 16|3@1+ (1.0,0.0) [0.0|7] ""  Vector__XXX
 SG_ ACA_HF_Grund_AV_AB : 19|3@1+ (1.0,0.0) [0.0|7] ""  Vector__XXX
 SG_ FZE_STP_Status : 22|2@1+ (1.0,0.0) [0.0|3] ""  Vector__XXX
 SG_ STP_Notlaufaktivierung : 25|1@1+ (1.0,0.0) [0.0|1] ""  Vector__XXX
 SG_ STP_Funktion_freigegeben : 26|1@1+ (1.0,0.0) [0.0|1] ""  NightVision
 SG_ ACA_QF_Status_Anzeige : 27|4@1+ (1.0,0.0) [0.0|15] ""  Vector__XXX
 SG_ ACF_SwuFahrerUnaufmerksam : 31|1@1+ (1.0,0.0) [0.0|1] ""  Vector__XXX
 SG_ ACA_QF_Fahreruebernahme : 32|2@1+ (1.0,0.0) [0.0|3] ""  Vector__XXX
 SG_ ACA_HF_Status : 34|4@1+ (1.0,0.0) [0.0|15] ""  Vector__XXX
 SG_ FZE_Spurwechsel_erkannt_li : 40|1@1+ (1.0,0.0) [0.0|1] ""  Vector__XXX
 SG_ FZE_Spurwechsel_erkannt_re : 41|1@1+ (1.0,0.0) [0.0|1] ""  Vector__XXX
 SG_ ACF_Spurwechsel_moeglich : 42|1@1+ (1.0,0.0) [0.0|1] ""  Vector__XXX
 SG_ ACF_Spurwechsel_wahrscheinlich : 43|1@1+ (1.0,0.0) [0.0|1] ""  Vector__XXX
 SG_ FZE_STP_Aktivierverhinderung : 44|2@1+ (1.0,0.0) [0.0|3] ""  Vector__XXX

BO_ 783 SWA_01: 8 MRR_HR
 SG_ SWA_01_CRC : 0|8@1+ (1,0) [0|255] ""  Gateway,Gateway_PAG
 SG_ SWA_01_BZ : 8|4@1+ (1,0) [0|15] ""  Gateway,Gateway_PAG
 SG_ SWA_Anzeigen : 12|4@1+ (1.0,0.0) [0.0|15] ""  Gateway,Gateway_PAG
 SG_ SWA_Blindheit_erkannt : 16|1@1+ (1.0,0.0) [0.0|1] ""  Gateway,Gateway_PAG
 SG_ SWA_rel_Nichtverf : 17|1@1+ (1.0,0.0) [0.0|1] ""  Gateway,Gateway_PAG
 SG_ SWA_rel_Fehler : 18|1@1+ (1.0,0.0) [0.0|1] ""  Gateway,Gateway_PAG
 SG_ SWA_Sta_aktiv : 19|1@1+ (1.0,0.0) [0.0|1] ""  Gateway,Gateway_PAG
 SG_ SWA_Sta_passiv : 20|1@1+ (1.0,0.0) [0.0|1] ""  Gateway,Gateway_PAG
 SG_ SWA_FT_RueckLED : 21|1@1+ (1.0,0.0) [0.0|1] ""  Gateway,Gateway_PAG
 SG_ ASW_Status : 22|2@1+ (1.0,0.0) [0.0|3] ""  Gateway,Gateway_PAG
 SG_ SWA_Standziele_li : 24|1@1+ (1.0,0.0) [0.0|1] ""  Gateway,Gateway_PAG
 SG_ SWA_Kolonne_li : 25|1@1+ (1.0,0.0) [0.0|1] ""  Gateway,Gateway_PAG
 SG_ SWA_Infostufe_SWA_li : 26|1@1+ (1.0,0.0) [0.0|1] ""  Gateway,Gateway_PAG
 SG_ SWA_Warnung_SWA_li : 27|1@1+ (1.0,0.0) [0.0|1] ""  Gateway,Gateway_PAG
 SG_ ASW_Warnung_FS : 28|1@1+ (1.0,0.0) [0.0|1] ""  Gateway,Gateway_PAG
 SG_ ASW_Warnung_BFS : 29|1@1+ (1.0,0.0) [0.0|1] ""  Gateway,Gateway_PAG
 SG_ ASW_Kombitexte : 30|3@1+ (1.0,0.0) [0.0|7] ""  Gateway,Gateway_PAG
 SG_ SWA_Kolonne_mi : 33|1@1+ (1.0,0.0) [0.0|1] ""  Gateway,Gateway_PAG
 SG_ ASW_Modus : 34|3@1+ (1.0,0.0) [0.0|7] ""  Gateway,Gateway_PAG
 SG_ SWA_Modus : 37|3@1+ (1.0,0.0) [0.0|7] ""  Gateway,Gateway_PAG
 SG_ SWA_Standziele_re : 40|1@1+ (1.0,0.0) [0.0|1] ""  Gateway,Gateway_PAG
 SG_ SWA_Kolonne_re : 41|1@1+ (1.0,0.0) [0.0|1] ""  Gateway,Gateway_PAG
 SG_ SWA_Infostufe_SWA_re : 42|1@1+ (1.0,0.0) [0.0|1] ""  Gateway,Gateway_PAG
 SG_ SWA_Warnung_SWA_re : 43|1@1+ (1.0,0.0) [0.0|1] ""  Gateway,Gateway_PAG
 SG_ HRE_Anzeigetexte : 44|4@1+ (1.0,0.0) [0.0|15] ""  Gateway,Gateway_PAG
 SG_ SWA_Status_02 : 48|2@1+ (1.0,0.0) [0.0|3] ""  Gateway,Gateway_PAG
 SG_ Heckradar_Kombitexte : 56|5@1+ (1.0,0.0) [0.0|31] ""  Gateway,Gateway_PAG
 SG_ RCTA_Kombitexte : 61|3@1+ (1.0,0.0) [0.0|7] ""  Gateway,Gateway_PAG

BO_ 673 SWA_02: 8 MRR_HR
 SG_ SWA_LED_Hell_BFS : 12|7@1+ (1,0) [0|100] "Unit_PerCent"  Gateway,Gateway_PAG
 SG_ SWA_LED_Hell_FS : 19|7@1+ (1,0) [0|100] "Unit_PerCent"  Gateway,Gateway_PAG
 SG_ SWA_LED_Modus_BFS : 26|3@1+ (1.0,0.0) [0.0|7] ""  Gateway,Gateway_PAG
 SG_ SWA_LED_Modus_FS : 29|3@1+ (1.0,0.0) [0.0|7] ""  Gateway,Gateway_PAG

BO_ 1413 Systeminfo_01: 8 Gateway
 SG_ SI_Sammel_SG_Fehler : 0|6@1+ (1,0) [0|60] ""  Vector__XXX
 SG_ SI_Diagnose_Aktiv : 7|1@1+ (1.0,0.0) [0.0|1] ""  Vector__XXX
 SG_ SI_QRS_Mode : 8|1@1+ (1.0,0.0) [0.0|1] ""  MRR_HL,MRR_HR,RDK,STH_MLBevo
 SG_ SI_T_Mode : 9|1@1+ (1.0,0.0) [0.0|1] ""  MRR_HL,MRR_HR,RDK,STH_MLBevo
 SG_ SI_NWDF : 10|1@1+ (1.0,0.0) [0.0|1] ""  AEM,E_Sound,FLA,ISE,MRR_HL,MRR_HR,NightVision,RDK,SAK,SAK2,STH_MLBevo,TopView
 SG_ SI_NWDF_gueltig : 11|1@1+ (1.0,0.0) [0.0|1] ""  AEM,E_Sound,FLA,ISE,MRR_HL,MRR_HR,NightVision,RDK,SAK,SAK2,STH_MLBevo,TopView
 SG_ SI_Sammelfehler : 12|1@1+ (1.0,0.0) [0.0|1] ""  Vector__XXX
 SG_ GW_KD_Fehler : 13|1@1+ (1.0,0.0) [0.0|1] ""  Vector__XXX
 SG_ SI_T_Schutz : 14|1@1+ (1.0,0.0) [0.0|1] ""  MRR_HL,MRR_HR
 SG_ SI_BUS_01 : 16|1@1+ (1.0,0.0) [0.0|1] ""  STH_MLBevo
 SG_ SI_BUS_02 : 17|1@1+ (1.0,0.0) [0.0|1] ""  Vector__XXX
 SG_ SI_BUS_03 : 18|1@1+ (1.0,0.0) [0.0|1] ""  MRR_HL,MRR_HR,STH_MLBevo
 SG_ SI_BUS_04 : 19|1@1+ (1.0,0.0) [0.0|1] ""  Vector__XXX
 SG_ SI_BUS_05 : 20|1@1+ (1.0,0.0) [0.0|1] ""  Vector__XXX
 SG_ SI_BUS_06 : 21|1@1+ (1.0,0.0) [0.0|1] ""  Vector__XXX
 SG_ SI_BUS_07 : 22|1@1+ (1.0,0.0) [0.0|1] ""  Vector__XXX
 SG_ SI_BUS_08 : 23|1@1+ (1.0,0.0) [0.0|1] ""  Vector__XXX
 SG_ SI_BUS_09 : 24|1@1+ (1.0,0.0) [0.0|1] ""  Vector__XXX
 SG_ SI_BUS_10 : 25|1@1+ (1.0,0.0) [0.0|1] ""  SCR
 SG_ SI_BUS_11 : 26|1@1+ (1.0,0.0) [0.0|1] ""  Vector__XXX
 SG_ SI_BUS_12 : 27|1@1+ (1.0,0.0) [0.0|1] ""  Vector__XXX
 SG_ SI_BUS_13 : 28|1@1+ (1.0,0.0) [0.0|1] ""  Vector__XXX
 SG_ SI_BUS_14 : 29|1@1+ (1.0,0.0) [0.0|1] ""  Vector__XXX
 SG_ SI_BUS_15 : 30|1@1+ (1.0,0.0) [0.0|1] ""  Vector__XXX
 SG_ SI_Bus_Identifikation : 32|8@1+ (1.0,0.0) [0.0|255] ""  Vector__XXX
 SG_ SI_CAB : 40|24@1+ (1.0,0.0) [0.0|16777215] ""  TopView

BO_ 1375 TME_10: 8 Gateway
 SG_ TME_VoKo_Strategie_Anzeige : 2|4@1+ (1.0,0.0) [0.0|15] ""  Vector__XXX
 SG_ TME_Zuheizer_Freigabe : 6|1@1+ (1.0,0.0) [0.0|1] ""  STH_MLBevo
 SG_ TME_AC_LED : 7|1@1+ (1.0,0.0) [0.0|1] ""  Vector__XXX
 SG_ TME_Heizstrategie : 8|4@1+ (1.0,0.0) [0.0|15] ""  Vector__XXX
 SG_ TME_Systemstatus : 12|2@1+ (1.0,0.0) [0.0|3] ""  Vector__XXX
 SG_ TME_Kbr_Innenraum : 14|1@1+ (1.0,0.0) [0.0|1] ""  Vector__XXX
 SG_ TME_Freigabe_Vorkond : 15|1@1+ (1.0,0.0) [0.0|1] ""  Vector__XXX
 SG_ TME_Verdampfer_Status : 16|1@1+ (1.0,0.0) [0.0|1] ""  Vector__XXX
 SG_ TME_Kuehlmittel_Sensor : 17|1@1+ (1.0,0.0) [0.0|1] ""  Vector__XXX
 SG_ TME_AC_Rueckmeldung : 18|2@1+ (1.0,0.0) [0.0|3] ""  Vector__XXX
 SG_ TME_Heizungspumpen_Anst : 20|4@1+ (10,0) [0|100] "Unit_PerCent"  STH_MLBevo
 SG_ TME_Frischluftklappe_Soll : 24|7@1+ (1,0) [0|100] "Unit_PerCent"  Vector__XXX
 SG_ TME_Freigabe_Luft_PTC : 31|1@1+ (1.0,0.0) [0.0|1] ""  Vector__XXX
 SG_ TME_Umluftklappe_Soll : 32|7@1+ (1,0) [0|100] "Unit_PerCent"  Vector__XXX
 SG_ TME_Waermepumpe_aktiv : 39|1@1+ (1.0,0.0) [0.0|1] ""  Vector__XXX
 SG_ TME_Nachlaufzeit_Heizp : 40|6@1+ (15,0) [0|945] "Unit_Secon"  STH_MLBevo
 SG_ TME_Absperrventil1_oeffnen : 46|2@1+ (1.0,0.0) [0.0|3] ""  STH_MLBevo
 SG_ TME_Klima_Defizit : 48|8@1+ (40,0) [0|10000] "Unit_Watt"  Vector__XXX
 SG_ TME_Temp_KM_vor_HWT : 56|8@1+ (0.75,-40) [-40.00|149.75] "Unit_DegreCelsi"  Vector__XXX

BO_ 2527679762 TPUI_03: 8 RDK
 SG_ TPUI_WarnLvlCmft : 12|4@1+ (1.0,0.0) [0.0|15] ""  Gateway,Gateway_PAG
 SG_ TPUI_WarnLvlMaxV : 16|4@1+ (1.0,0.0) [0.0|15] ""  Gateway,Gateway_PAG

BO_TX_BU_ 1440 :Gateway,Gateway_PAG;
BO_TX_BU_ 1528 :ISE,SAK;
BO_TX_BU_ 424 :Gateway,Gateway_PAG;
BO_TX_BU_ 980 :Gateway,Gateway_PAG;
BO_TX_BU_ 1710 :Gateway,Gateway_PAG;
BO_TX_BU_ 505 :Gateway,Gateway_PAG;
BO_TX_BU_ 1413 :Gateway,Gateway_PAG;
BO_TX_BU_ 1375 :Gateway,Gateway_PAG;
CM_ BO_ 1529 "MQB";
CM_ BO_ 1440 "8Byte ab MLBevo
LIN-CAN (1:1) Botschaften werden geroutet
-  wenn entsprechender Slave codiert ist
-  wenn fehlerfreie Kommunikation zum Slave besteht
-  bei fehlerhafter Kommunikation zum Slave wird die Botschaft für 4s mit den letzten gültigen Werte";
CM_ BO_ 1528 "ab MQB mit geändertem Charisma, ohne KD-Fehler";
CM_ BO_ 424 "CAN-Botschaft";
CM_ BO_ 1510 "Teilenummer & Checksumme für OBD-Lampe";
CM_ BO_ 980 "Ab MQB 7.2";
CM_ BO_ 1710 "MLBevo 8Byte";
CM_ BO_ 1650 "Zielzeittimeranzeige im Display des MMI";
CM_ BO_ 783 "ab MQB mit CRC-8";
CM_ BO_ 1413 "MQB, MLBevo";

CM_ SG_ 1529 RDK_angelernt "RDK signalisiert, dass die Radelektroniken angelernt sind und das Kombi den Rundstreckenmodus anbieten kann.";
CM_ SG_ 1529 RDK_FMVSS138_Lampe "Ansteuerung der RDK-Lampe im Kombi bei Druckwarnung";
CM_ SG_ 1529 RDK_FMVSS138_MIL "Ansteuerung der RDK-Lampe im Kombi bei Systemstörung.
RDK-Lampe muss für 65 Sekunden blinken und anschliessend dauerhaft leuchten bis RDK dieses Bit wieder auf '0' setzt (Wiedergutprüfung).
Hinweis:  Im AU48x blinken für 60 Sekunden";
CM_ SG_ 1529 RDK_Kalibrierung "Art der Vorgabe der Solldrücke
0x0 Vorgabe der Solldrücke erfolgt durch eine Reifenauswahl in der Headunit
0x1 Vorgabe der Solldrücke erfolgt durch Betätigung des SET-Tasters des Kombiinstruments";
CM_ SG_ 1529 RDK_Reifendruck_Lampe "Ansteuerung einer RDK-Lampe im Kombi bei einem problematischen Druck";
CM_ SG_ 1529 RDK_Reifentemperatur_Lampe "Ansteuerung einer RDK-Lampe im Kombi bei einer problematischen Reifentemperatur";
CM_ SG_ 1529 RDK_RS_aktiv "Rundstreckenmodus inaktiv/ aktiv";
CM_ SG_ 1529 RDK_Text_7 "Textausgabe 7: Mindestdruck für Rundstreckenmode unterschritten";
CM_ SG_ 1529 RDK_W_1_Reifen_HL "Harte Warnung fuer Reifen hinten links";
CM_ SG_ 1529 RDK_W_1_Reifen_HR "Harte Warnung fuer Reifen hinten rechts";
CM_ SG_ 1529 RDK_W_1_Reifen_VL "Harte Warnung fuer Reifen vorne links";
CM_ SG_ 1529 RDK_W_1_Reifen_VR "Harte Warnung fuer Reifen vorne rechts";
CM_ SG_ 1529 RDK_W_2_Reifen_HL "Weiche Warnung fuer Reifen hinten links";
CM_ SG_ 1529 RDK_W_2_Reifen_HR "Weiche Warnung fuer Reifen hinten rechts";
CM_ SG_ 1529 RDK_W_2_Reifen_VL "Weiche Warnung fuer Reifen vorne links";
CM_ SG_ 1529 RDK_W_2_Reifen_VR "Weiche Warnung fuer Reifen vorne rechts";
CM_ SG_ 1529 RDK_Warnungen_02 "Ausgabe von Texten/Akustik im Kombiinstrument";

CM_ SG_ 2589283632 RDK_Diff_Druck_HL "Differenzdruck zwischen Ist- und Solldruck HL, normiert auf 20°C";
CM_ SG_ 2589283632 RDK_Diff_Druck_HR "Differenzdruck zwischen Ist- und Solldruck HR, normiert auf 20°C";
CM_ SG_ 2589283632 RDK_Diff_Druck_VL "Differenzdruck zwischen Ist- und Solldruck VL, normiert auf 20°C";
CM_ SG_ 2589283632 RDK_Diff_Druck_VR "Differenzdruck zwischen Ist- und Solldruck VL, normiert auf 20°C";
CM_ SG_ 2589283632 RDK_Reifengroesse "Ausgabe der Reifengröße (Vorderachse)";
CM_ SG_ 2589283632 RDK_Reifentyp "Ausgabe von Reifentyp";
CM_ SG_ 2589283632 RDK_Reifentyp_02 "Ausgabe von weiteren Reifentypen";
CM_ SG_ 2589283632 RDK_SollDruck_HA "Solldruck hinten";
CM_ SG_ 2589283632 RDK_SollDruck_VA "Solldruck vorne";

CM_ SG_ 1651 RDK_Druck_HL_unkomp "Reifendruck hinten links unkompensiert für BC";
CM_ SG_ 1651 RDK_Druck_HR_unkomp "Reifendruck hinten rechts unkompensiert für BC";
CM_ SG_ 1651 RDK_Druck_VL_unkomp "Reifendruck vorne links unkompensiert für BC";
CM_ SG_ 1651 RDK_Druck_VR_unkomp "Reifendruck vorne rechts unkompensiert für BC";
CM_ SG_ 1651 RDK_R_Temp_HL "Reifentemperatur hinten links";
CM_ SG_ 1651 RDK_R_Temp_HR "Reifentemperatur hinten rechts";
CM_ SG_ 1651 RDK_R_Temp_VL "Reifentemperatur vorne links";
CM_ SG_ 1651 RDK_R_Temp_VR "Reifentemperatur vorne rechts";
CM_ SG_ 1651 RDK_Signal_Alter_HL "Gibt die Aktualitaet/ Alter des Sensorsignals an.";
CM_ SG_ 1651 RDK_Signal_Alter_HR "Gibt die Aktualitaet/ Alter des Sensorsignals an.";
CM_ SG_ 1651 RDK_Signal_Alter_VL "Gibt die Aktualitaet/ Alter des Sensorsignals an.";
CM_ SG_ 1651 RDK_Signal_Alter_VR "Gibt die Aktualitaet/ Alter des Sensorsignals an.";

CM_ SG_ 2463978816 Solldruck_Fahrerauswahl "Übertraegt die durch den Fahrer ausgewählte Konfiguration bezueglich vollbeladen/teilbeladen und Normal-/Komfortdruck";
CM_ SG_ 2463978816 Solldruck_TempAbhaengig_HL "temperaturabhaengiger Solldruck Rad hinten links";
CM_ SG_ 2463978816 Solldruck_TempAbhaengig_HR "temperaturabhaengiger Solldruck Rad hinten rechts";
CM_ SG_ 2463978816 Solldruck_TempAbhaengig_VL "temperaturabhaengiger Solldruck Rad vorne links";
CM_ SG_ 2463978816 Solldruck_TempAbhaengig_VR "temperaturabhaengiger Solldruck Rad vorne rechts";
CM_ SG_ 2463978816 TPMS_WarnWhlChgDet "Warning on wheel change detected";
CM_ SG_ 2463978816 TPMS_WhlChgDetFrLe "Wheel change front left detected";
CM_ SG_ 2463978816 TPMS_WhlChgDetFrRi "Wheel change front right detected";
CM_ SG_ 2463978816 TPMS_WhlChgDetReLe "Wheel change rear left detected";
CM_ SG_ 2463978816 TPMS_WhlChgDetReRi "Wheel change rear right detected";

CM_ SG_ 2527679876 TPMS_SensPFrLe "Sensor measured pressure (tire pressure uncompensated) front left";
CM_ SG_ 2527679876 TPMS_SensPFrRi "Sensor measured pressure (tire pressure uncompensated) front right";
CM_ SG_ 2527679876 TPMS_SensPReLe "Sensor measured pressure (tire pressure uncompensated) rear left";
CM_ SG_ 2527679876 TPMS_SensPReRi "Sensor measured pressure (tire pressure uncompensated) rear right";
CM_ SG_ 2527679876 TPMS_SensSigAgeFrLe "Indicates the age of the sensor signal front left";
CM_ SG_ 2527679876 TPMS_SensSigAgeFrRi "Indicates the age of the sensor signal front right";
CM_ SG_ 2527679876 TPMS_SensSigAgeReLe "Indicates the age of the sensor signal rear left";
CM_ SG_ 2527679876 TPMS_SensSigAgeReRi "Indicates the age of the sensor signal rear right";

CM_ SG_ 1711 RV_Dark_Screen "Verdunkelungsanforderung Kamerabild";
CM_ SG_ 1711 RV_Farbe "Istwert fuer Farbe (in Prozent)";
CM_ SG_ 1711 RV_Helligkeit "Istwert fuer Helligkeit (in Prozent)";
CM_ SG_ 1711 RV_HMI_Mode "Aktueller Wert für den HMI-Modus

";
CM_ SG_ 1711 RV_Kontrast "Istwert fuer Kontrast (in Prozent)";
CM_ SG_ 1711 RV_Menu_Item "Ausgewähltes Menü-Item
";
CM_ SG_ 1711 RV_Reinigung_Anf "Anforderung Reinigung der Rückfahrkamera";
CM_ SG_ 1711 RV_Settings_enabled "Menü 'Einstellungen'
";
CM_ SG_ 1711 RV_System_aktiv "Systemstatus (Initialisierungsphase)
";
CM_ SG_ 1711 RV_Video_on "Anzeige Kamerabild
";
CM_ SG_ 1711 SV_Video_on "Aufschaltaufforderung SideView";
CM_ SG_ 1711 ZFAS_Umfeldbeleuchtung_Anf "Anforderung für die Aktivierung einer Umfeldbeleuchtung zur Unterstützung des Umfeldkamerasystems bei Dunkelheit";

CM_ SG_ 1440 LS_defekt "Fehlererkennung Lichtsensor
";
CM_ SG_ 1440 LS_Helligkeit_FW "Vorfeldhelligkeit";
CM_ SG_ 1440 LS_Helligkeit_IR "Globalfeldhelligkeit";
CM_ SG_ 1440 LS_Verbau "Verbauinfo Lichtsensor";
CM_ SG_ 1440 RLS_Vorfeldhelligkeit_Boost "erweiterte Helligkeitssensierung für HUD";
CM_ SG_ 1440 RS_defekt "Fehlererkennung Regensensor";
CM_ SG_ 1440 RS_Regenmenge "Regenmenge";
CM_ SG_ 1440 RS_Verbau "Verbauinfo Regensensor";
CM_ SG_ 1440 RS_Verglasung_schliessen "Anforderung: Verglasung schliessen
";
CM_ SG_ 1440 RS_Wischergeschwindigkeit "Wischergeschwindigkeit (Hübe/min)";

CM_ SG_ 1528 SAK_Charisma_FahrPr "MLBevo: Aktuelles Fahrprogramm des Charisma-Teilnehmers (siehe Systemlastenheft Drive Select)
MQB: Istwert der Kennlinie (siehe Systemlastenheft MQB FPA)";
CM_ SG_ 1528 SAK_Charisma_Status "Rückmeldung an den Charisma-Master

Wert 0x3 ist nur für Fahrzeuge ab MQB relevant";

CM_ SG_ 424 SARA_11_CRC "Für MLB:
'Berechnung siehe Lastenheft 'Kommunikationsabsicherung für Flexray und CAN''

Ab MQB und MLBevo:
'Berechnung siehe Lastenheft 'End-to-End Kommunikationsabsicherung'

Endwerte siehe Begleitdokument 'S-PDU Kennungsfolge'";
CM_ SG_ 424 SARA_Accel_X_r "Beschleunigung Acceleration-X routable:
- 0x0000= Sensor nicht verbaut, Signal wird nicht berechnet
- genutzter Wertebereich ± 640 m/s²

Filterung: 60 Hz Sensorfilter + 15 Hz uC-Filter (Cheby-II 3.Ordnung)";
CM_ SG_ 424 SARA_Accel_Y_r "Beschleunigung Acceleration-Y routable:
- 0x0000= Sensor nicht verbaut, Signal wird nicht berechnet
- genutzter Wertebereich ± 640 m/s²

Filterung: 60 Hz Sensorfilter + 15 Hz uC-Filter (Cheby-II 3.Ordnung)";
CM_ SG_ 424 SARA_CF_Accel_X_r "Confidence Faktor Beschleunigung Acceleration-X routable:

0=gültiger Wert
1=nicht belegt
2=nicht belegt
3=Temporärer Fehler {solange möglich werden aktuelle Sensorwerte gesendet, ansonsten 0xFFFF}
4=Init {0x8000 wird gesendet}
5=Sensor nicht verba";
CM_ SG_ 424 SARA_CF_Accel_Y_r "Confidence Faktor Beschleunigung Acceleration-Y routable:

0=gültiger Wert
1=nicht belegt
2=nicht belegt
3=Temporärer Fehler {solange möglich werden aktuelle Sensorwerte gesendet, ansonsten 0xFFFF}
4=Init {0x8000 wird gesendet}
5=Sensor nicht verba";
CM_ SG_ 424 SARA_CF_Omega_Z_r "Confidence Faktor Winkelgeschwindigkeit Omega-Z routable:

0=gültiger Wert
1=nicht belegt
2=nicht belegt
3=Temporärer Fehler {solange möglich werden aktuelle Sensorwerte gesendet, ansonsten 0xFFFF}
4=Init {0x8000 wird gesendet}
5=Sensor nicht verba";
CM_ SG_ 424 SARA_Omega_Z_r "Winkelgeschwindigkeit Omega-Z routable:
- 0x0000 = Sensor nicht verbaut, Signal wird nicht berechnet
- genutzter Wertebereich ± 320 Deg/s

Filterung: 60 Hz Sensorfilter + 15 Hz uC-Filter (Cheby-II 3.Ordnung)";

CM_ SG_ 1011 SCR_01_BZ "Zähler der von der Applikation inkrementiert wird";
CM_ SG_ 1011 SCR_Dosierpumpe_Drehzahl "Drehzahl der Dosierpumpe

negative 1/min für Rückwärtsbetrieb
0 für Stop
positive 1/min für Vorwärtsbetrieb";
CM_ SG_ 1011 SCR_Druck "Druck der wässrigen Harnstofflösung";
CM_ SG_ 1011 SCR_Level_Aktivtank "Füllstand des Aktivtanks";
CM_ SG_ 1011 SCR_Level_ReadAbove "Zeigt an in welchem Messmodus der Levelsensor ist.
Dieses Signal ist für die Füllstandberechnung notwendig und für die OBD-Diagnose mit notwendig.
Ist der Sensor im Readabove Ein Modus, ist die Toleranz des gemessenen Signals größer.";
CM_ SG_ 1011 SCR_QBit_Level_Aktivtank_02 "gibt an ob das Signal gültig ist.";
CM_ SG_ 1011 SCR_Sent_Level_Aktivtank "Füllstand des Aktivtanks";
CM_ SG_ 1011 SCR_Sent_Levelsignal_Status "Gibt an, in welchem Aggregatzustand sich die Flüssigkeit im Aktivtank befindet";

CM_ SG_ 1507 SCR_02_BZ "Zähler der von der Applikation inkrementiert wird";
CM_ SG_ 1507 SCR_Guetesensor "Güte der Flüssigkeit";
CM_ SG_ 1507 SCR_Heizkreis_3_Strom "gemessener Strom vom Heizkreis 3 (ist optional verbaut)";
CM_ SG_ 1507 SCR_Leitungsheizung_Strom "gemessener Strom für die Leitungsheizung";
CM_ SG_ 1507 SCR_Tankheizung_Strom "gemessener Strom für die Tankheizung Aktivtank";
CM_ SG_ 1507 SCR_Temp_Aktivtank "Temperatur des Medium im Aktivtank";
CM_ SG_ 1507 SCR_Temp_Passivtank "Temperatur des Medium im Aktivtank";
CM_ SG_ 1507 SCR_Transferpumpe_Strom "gemessener Strom für dieTransferpumpe";

CM_ SG_ 1508 SCR_03_BZ "Zähler der von der Applikation inkrementiert wird";
CM_ SG_ 1508 SCR_Dosierpumpe_Status_Spule "Statusinformation für OBD-Auswertung";
CM_ SG_ 1508 SCR_Druck_Status_02 "Statusinformation für OBD-Auswertung
KS+ / OC entspricht KS+ nach 5V";
CM_ SG_ 1508 SCR_Heizkreis_3_Status "Statusinformation für OBD-Auswertung";
CM_ SG_ 1508 SCR_Leitungsheizung_Status "Statusinformation für OBD-Auswertung";
CM_ SG_ 1508 SCR_Level_Aktivtank_Status "Statusinformation für OBD-Auswertung
KS+ / OC entspricht KS+ nach 5V
RC+ (alle Schalter offen) UND RC- (Wert unplausibel)";
CM_ SG_ 1508 SCR_Level_Passivtank_Status "Statusinformation für OBD-Auswertung
KS+ / OC entspricht KS+ nach 5V
RC+ (alle Schalter offen) UND RC- (Wert unplausibel)";
CM_ SG_ 1508 SCR_Sensorversorgung_12V_Status "Statusinformation für OBD-Auswertung der 12V-Sensorversorgung";
CM_ SG_ 1508 SCR_Spannungsversorgung_Status "Statusinformation für OBD-Auswertung";
CM_ SG_ 1508 SCR_Tankheizung_Status "Statusinformation für OBD-Auswertung";
CM_ SG_ 1508 SCR_Temp_Aktivtank_Status_02 "Statusinformation für OBD-Auswertung
KS+ / OC entspricht KS+ nach 5V";
CM_ SG_ 1508 SCR_Temp_Passivtank_Status "Statusinformation für OBD-Auswertung
KS+ / OC entspricht KS+ nach 5V";
CM_ SG_ 1508 SCR_Transferpumpe_Status "Statusinformation für OBD-Auswertung";
CM_ SG_ 1508 SCR_VersorgungSensoren_Status_02 "Statusinformation für OBD-Auswertung";

CM_ SG_ 1509 SCR_04_BZ "Zähler der von der Applikation inkrementiert wird";
CM_ SG_ 1509 SCR_Ansteuerung_Dosierpumpe "Messwert im Motor-SG zur Treiber-Ansteuerung der Dosierpumpen Endstufe.";
CM_ SG_ 1509 SCR_Ansteuerung_Heizkreis_3 "Messwert im Motor-SG zur Treiber-Ansteuerung der Heizkreis 3 Endstufe. ";
CM_ SG_ 1509 SCR_Ansteuerung_Leitungsheizung "Messwert im Motor-SG zur Treiber-Ansteuerung der Leitungsheizungs Endstufe. ";
CM_ SG_ 1509 SCR_Ansteuerung_Tankheizung "Messwert im Motor-SG zur Treiber-Ansteuerung der Tankheizungs Endstufe. ";
CM_ SG_ 1509 SCR_Ansteuerung_Transferpumpe "Messwert im Motor-SG zur Treiber-Ansteuerung der Transferpumpe Endstufe. ";
CM_ SG_ 1509 SCR_CAL_CVN_CRC_32 "Gesetzliche Anforderung nach OBD-Gesetz CCR1968.2 (g) (4.7) für 'diagnostic or emission critical powertrain control module'";
CM_ SG_ 1509 SCR_Steuergeraet_PMode "Gibt an ob der Vehicle P-Mode im SCR-Steuergeraet aktiv ist.";

CM_ SG_ 1526 SCR_05_BZ "Zähler der von der Applikation inkrementiert wird";
CM_ SG_ 1526 SCR_DEF_Qualitaet_Medium "Gibt an, dass die Konzentration des Medium nicht ermittelt werden kann.";
CM_ SG_ 1526 SCR_ECU_Datensatz_Status "StatusInformation für OBD-Auswertung";
CM_ SG_ 1526 SCR_HAL_Sensorik_Status "Statusinformation für OBD-Auswertung der HAL-Sensorik";
CM_ SG_ 1526 SCR_Level_Aktivtank_OOR4Quality "Der Füllstand im SCR-Tank ist zu niedrig um eine Qualtiätsmessung durchzuführen.";
CM_ SG_ 1526 SCR_Level_Aktivtank_OOR_minus "Minimaler Level vom SCR-Tank erreicht.
Tankstand so niedrig, dass das Signal nicht mehr verlässlich erfasst werden kann.";
CM_ SG_ 1526 SCR_QBit_Qualitaet "gibt an ob das Signal gültig ist";
CM_ SG_ 1526 SCR_Sent_1_elektrischer_Status "Fehlerstatus der elektrischen Diagnosen";
CM_ SG_ 1526 SCR_Sent_1_Signalstatus "Signalfehler vom Sent_1 Signal";
CM_ SG_ 1526 SCR_Sent_2_elektrischer_Status "Fehlerstatus der elektrischen Diagnosen auf dem zweiten Sentkanal";
CM_ SG_ 1526 SCR_Sent_2_Signalstatus "Signalfehler vom Sent_2  Signal";
CM_ SG_ 1526 SCR_Sent_Levelsensor "Funktionaler Fehlerstatus des Levelsensors";
CM_ SG_ 1526 SCR_Sent_Qualitaetssensor "Funktionalen Fehler des Qualitätssensors";
CM_ SG_ 1526 SCR_Sent_Temperatursensor "Funktionaler Fehlerstatus vom internen Temperatursensor in dem Sentsensor";
CM_ SG_ 1526 SCR_Steuergeraet_Bus_Status "StatusInformation für OBD-Auswertung";
CM_ SG_ 1526 SCR_Steuergeraet_Defekt_Status "StatusInformation für OBD-Auswertung";
CM_ SG_ 1526 SCR_Steuergeraet_Heizung_Status "StatusInformation für OBD-Auswertung";
CM_ SG_ 1526 SCR_Steuergeraet_Pumpe_Status "StatusInformation der Dosierpumpe für OBD-Auswertung";
CM_ SG_ 1526 SCR_Steuergeraet_Relais_Status "StatusInformation für OBD-Auswertung";
CM_ SG_ 1526 SCR_Temp_DEF2_Sensor_Status "Funktionaler Fehlerstatus vom internen Temperatursensor des zweiten Sentsensors";

CM_ SG_ 2527679503 SCR_DEF_CAL_CVN_CRC_32 "Major Monitor Sensor hat eine CVN zu senden";
CM_ SG_ 2527679503 SCR_Level_Aktivtank_saturated "Max. Füllstanderfassung erreicht";
CM_ SG_ 2527679503 SCR_QBit_Qualitaet_Aktivtank "Gibt an ob, dass aktuell gesendetet Qualitysignal gültig ist.";
CM_ SG_ 2527679503 SCR_QBit_Temp_DEF_Sensor_02 "Gibt an ob das Signal SCR_SENT_Temperatur gültig ist.";
CM_ SG_ 2527679503 SCR_Sent_Qualitaet_Aktivtank "Qualitätssignal des Aktivtank";
CM_ SG_ 2527679503 SCR_Temp_DEF_Hinweis "Gibt an ob die Temperatur am Sensor zu hoch oder zu niedrig ist, um eine verlässliches Signal vom Qualitätssensor oder Levelsensor zu bilden.";
CM_ SG_ 2527679503 SCR_Temperatur_DEF_Sensor "internes Temperatursignal vom Qualitätssensor.
Dieses Signal wird für den Crosscheck benötigt um das Qualitätssignal zu qulifizieren. Anforderung OBD-II";

CM_ SG_ 2589283459 SCR_Heizkreis_3_P_effektiv "Rückmeldung der effektiven Leistung vom Heizkreis_3";
CM_ SG_ 2589283459 SCR_Heizkreis_3_P_Grenze "Gibt die aktuell verfügbare Leistung für den Heizkreis 3 an.";
CM_ SG_ 2589283459 SCR_Tankheizkreis_P_Grenze "Gibt die aktuell verfügbare Leistung für den Tankheizkreis an.";
CM_ SG_ 2589283459 SCR_Tankheizung_P_effektiv "Rückmeldung der effektiven Leistung vom Tankheizkreis";

CM_ SG_ 2589283460 SCR_DEF2_CAL_CVN_CRC_32 "CVN des zweiten Sensors. Wird für die Ausgabe an das SCAN-Tool benötigt.";
CM_ SG_ 2589283460 SCR_QBit_Temp_DEF2_Sensor "Gibt an ob das Signal SCR_Temp_DEF2_Sensor gültig ist.";
CM_ SG_ 2589283460 SCR_Temp_DEF2_Sensor "Temperatur des zweiten DEF-Sensors im SCR-Tank";

CM_ SG_ 2463978593 SCR_Dosierpumpe_Umdrehungen "Anzahl der Umdrehungen der Dosierpumpe seit letztem Startup.

Zähler fängt bei Übverlauf wieder bei Null an. Der Zähler wird sowohl bei Vorwärts als auch bei Rückwärtsbetrieb der Pumpe hochgezählt. Somit muss der Ansteuerungsmodus bei der Auswertung des";
CM_ SG_ 2463978593 SCR_QBit_Level_kurz_Aktivtank "gibt an ob das Signal 'SCR_Sent_Level_kurz_Aktivtank' gültig ist.";
CM_ SG_ 2463978593 SCR_Sent_Level_kurz_Aktivtank "Füllstand des Aktivtanks, gemessen mit dem kurzen Levelsensor für höhere Genauigkeit bei niedrigen Füllständen";

CM_ SG_ 1510 SCR_CAL_ID_Index_01 "ASCII-Zeichen erster Buchstabe des SG-Namens";
CM_ SG_ 1510 SCR_CAL_ID_Index_02 "ASCII-Zeichen zweiter Buchstabe des SG-Namens";
CM_ SG_ 1510 SCR_CAL_ID_Index_03 "ASCII-Zeichen dritter Buchstabe des SG-Namens";
CM_ SG_ 1510 SCR_CAL_ID_Index_04 "ASCII-Zeichen erster Buchstabe der letzten 3 Stellen der Software-Teilenummer";
CM_ SG_ 1510 SCR_CAL_ID_Index_05 "ASCII-Zeichen zweiter Buchstabe der letzten 3 Stellen der Software-Teilenummer";
CM_ SG_ 1510 SCR_CAL_ID_Index_06 "ASCII-Zeichen dritter Buchstabe der letzten 3 Stellen der Software-Teilenummer";
CM_ SG_ 1510 SCR_CAL_ID_Index_07 "ASCII-Zeichen Buchstabe für Hardware-Index";
CM_ SG_ 1510 SCR_CAL_ID_Index_08 "ASCII-Zeichen erster Buchstabe der vierstelligen Softwareversion";

CM_ SG_ 1512 SCR_CAL_ID_Index_09 "ASCII-Zeichen zweiter Buchstabe der vierstelligen Softwareversion";
CM_ SG_ 1512 SCR_CAL_ID_Index_10 "ASCII-Zeichen dritter Buchstabe der vierstelligen Softwareversion";
CM_ SG_ 1512 SCR_CAL_ID_Index_11 "ASCII-Zeichen vierter Buchstabe der vierstelligen Softwareversion";
CM_ SG_ 1512 SCR_CAL_ID_Index_12 "ASCII-Zeichen erster Buchstabe der zweistelligen Abgelegten Fahrzeugklasse aus dem Datensatz";
CM_ SG_ 1512 SCR_CAL_ID_Index_13 "ASCII-Zeichen zweiter Buchstabe der zweistelligen Abgelegten Fahrzeugklasse aus dem Datensatz";
CM_ SG_ 1512 SCR_CAL_ID_Index_14 "ASCII-Zeichen Reserve zur Erweiterung der OBD-relevanten Variante";
CM_ SG_ 1512 SCR_CAL_ID_Index_15 "ASCII-Zeichen erster Buchstabe der zweistelligen Datensatzversion";
CM_ SG_ 1512 SCR_CAL_ID_Index_16 "ASCII-Zeichen zweiter Buchstabe der zweistelligen Datensatzversion";

CM_ SG_ 2589283497 SCR_DEF2_CAL_ID_Index01 "Die Bytes 1 bis 4 von der 16 stelligen CALID des zweiten Sentsensors.";
CM_ SG_ 2589283497 SCR_DEF2_CAL_ID_Index02 "5 bis 8 Byte der CALID vom zweiten Sentsensor";

CM_ SG_ 2589283498 SCR_DEF2_CAL_ID_Index03 "9. bis 12. Byte der CALID vom zweiten Sentsensor";
CM_ SG_ 2589283498 SCR_DEF2_CAL_ID_Index04 "13. bis 16. Byte der CALID für den zweiten Sentsensor";

CM_ SG_ 2589283413 SCR_DEF_CAL_ID_Index01 "Major Monitor Sensoren haben eine CALID zu senden";
CM_ SG_ 2589283413 SCR_DEF_CAL_ID_Index02 "Major Monitor Sensoren haben ein CALID zu senden.";

CM_ SG_ 2589283414 SCR_DEF_CAL_ID_Index03 "Major Monitor Sensoren haben einen CALID zu senden";
CM_ SG_ 2589283414 SCR_DEF_CAL_ID_Index04 "Major Monitor Sensoren haben einen CALID zu senden";

CM_ SG_ 980 BH_Blinker_Fehler "Anzeige, ob am Lenkstockschalter ein Fehler anliegt.
Notwendig aufgrund ASIL-Einstufung";
CM_ SG_ 980 BH_Blinker_li "Blinkerhebel Richtung links";
CM_ SG_ 980 BH_Blinker_re "Blinkerhebel Richtung rechts";
CM_ SG_ 980 BH_Fernlicht "Betaetigung Fernlicht
";
CM_ SG_ 980 BH_Lichthupe "Betaetigung Lichthupe
";
CM_ SG_ 980 FAS_Taster "Betaetigung FAS Taster
";
CM_ SG_ 980 FAS_Taster_Fehler "Fehlerstatus FAS Taster
";
CM_ SG_ 980 LRH_aktiv "Signal gibt an, ob ein Heizstrom durch die Lenkradheizung fließt. Es dient der Auswertung durch das Energiemanagement.";
CM_ SG_ 980 LRH_On_Off "Status Lenkradheizung";
CM_ SG_ 980 SMLS_01_BZ "4bit Botschaftszaehler, wird mit jeder Sendebotschaft inkrementiert";
CM_ SG_ 980 SMLS_01_CRC "Für MLB:
'Berechnung siehe Lastenheft 'Kommunikationsabsicherung für FlexRay und CAN''

Ab MQB und MLBevo:
'Berechnung siehe Lastenheft 'End-to-End Kommunikationsabsicherung''

Endwerte siehe Begleitdokument 'S-PDU Kennungsfolgen'";
CM_ SG_ 980 SMLS_Hupe "Betaetigung Hupe
";
CM_ SG_ 980 SMLS_P_verriegelt_plausibel "Signal stellt den Plausibilisierungstatus des Signals p_verriegelt auf den Fahrzeugbus zur Verfügung. Eine Plausibilität muss explizit erkannt werden. Initial wird 'unplausibel' gesendet. Ein plausibles Signal wird erkannt, wenn p_verriegelt plausibel geg";
CM_ SG_ 980 SMLS_PTT "Betaetigung PTT";
CM_ SG_ 980 WH_Frontwaschen "Wischerhebel: Stellung Wisch Wasch vorne
";
CM_ SG_ 980 WH_Heckintervall "Wischerhebel: Stellung Heckintervall
";
CM_ SG_ 980 WH_Heckwaschen "Wischerhebel: Stellung Wisch Wasch hinten
";
CM_ SG_ 980 WH_Intervall "Wischerhebel: Stellung Intervall
";
CM_ SG_ 980 WH_Intervallstufen "Wischerhebel: Stellung Intervallstufen";
CM_ SG_ 980 WH_SRA "Scheinwerferreinigungsanlage

derzeit nur bei PAG umgesetzt";
CM_ SG_ 980 WH_Tipwischen "Wischerhebel: Tippwischen

MQB A0/ PQ26: Bei Verbau LSS (kein SMLS): gespiegelter Wert zu Signal WH_WischerStufe1";
CM_ SG_ 980 WH_Tipwischen_lang "Wischerhebel: Tippwischen lang
(dient zur Auswertung für die Unterscheidung Tippwischen oder Serviceposition Wischer)";
CM_ SG_ 980 WH_Wischer_Fehler "Anzeige, ob am Lenkstockschalter ein Fehler anliegt.
Notwendig aufgrund ASIL-Einstufung";
CM_ SG_ 980 WH_WischerStufe1 "Wischerhebel: Stufe Wischen 1
";
CM_ SG_ 980 WH_WischerStufe2 "Wischerhebel: Stufe Wischen 2
";

CM_ SG_ 1710 SP_abklappen "Spiegel abklappen";
CM_ SG_ 1710 SP_anklappen "Spiegel anklappen";
CM_ SG_ 1710 SP_ARA_Status "Rückkanal TSG im ARA-Modus";
CM_ SG_ 1710 SP_Auswahl_li "Spiegelschalter in Stellung Auswahl links";
CM_ SG_ 1710 SP_Auswahl_re "Spiegelschalter in Stellung Auswahl rechts";
CM_ SG_ 1710 SP_BT_links "Spiegel Beifahrertür nach links";
CM_ SG_ 1710 SP_BT_oben "Spiegel Beifahrertür nach oben";
CM_ SG_ 1710 SP_BT_rechts "Spiegel Beifahrertür nach rechts";
CM_ SG_ 1710 SP_BT_unten "Spiegel Beifahrertür nach unten";
CM_ SG_ 1710 SP_FT_links "Spiegel Fahrertür nach links";
CM_ SG_ 1710 SP_FT_oben "Spiegel Fahrertür nach oben";
CM_ SG_ 1710 SP_FT_rechts "Spiegel Fahrertür nach rechts";
CM_ SG_ 1710 SP_FT_unten "Spiegel Fahrertür nach unten";
CM_ SG_ 1710 SP_Hzg_Taster "Heizungstaster/schalter aktiv";
CM_ SG_ 1710 SP_normieren "Spiegel normieren";
CM_ SG_ 1710 SP_S_Klappen "Spiegelschalter in Stellung Klappen";
CM_ SG_ 1710 SP_S_links "Spiegelschalter in Stellung links";
CM_ SG_ 1710 SP_S_oben "Spiegelschalter in Stellung oben";
CM_ SG_ 1710 SP_S_rechts "Spiegelschalter in Stellung rechts";
CM_ SG_ 1710 SP_S_unten "Spiegelschalter in Stellung unten";
CM_ SG_ 1710 SP_Verstellschalter_Fehler "Erkennung eines hängenden Spiegelverstellschalters";

CM_ SG_ 1313 STH_EKP_Anst "STH sendet die Anforderung zur Ansteuerung der EKP an den Motor, um Kraftstoffbehälter der STH zu befüllen.";
CM_ SG_ 1313 STH_Fehler_ElWaPu "Fehler der el. Zusatzwasserpumpe der zur Deaktivierung der Wasserpumpe führt ";
CM_ SG_ 1313 STH_Fehlerstatus "Übermittlung der unterschiedlichen Fehlerzustände der Standheizung";
CM_ SG_ 1313 STH_Funk_aus "Funkbefehl über Funkfernbedienung zum Ausschalten Standheizung";
CM_ SG_ 1313 STH_Funk_ein "Funkbefehl über Funkfernbedienung zum Einschalten Standheizung";
CM_ SG_ 1313 STH_Geblaese "Ein-/ Ausschaltbefehl an die Klimaanlage, Gebläse";
CM_ SG_ 1313 STH_Heizleistung "Heizleistung in %";
CM_ SG_ 1313 STH_KL_HUP "Signal HUP Aktivierung an Klima

0 = HUP aus
1 = HUP ein";
CM_ SG_ 1313 STH_KVS "Kraftstoffverbrauch";
CM_ SG_ 1313 STH_KVS_Ueberlauf "Kraftstoffverbrauch, Überlauf hat stattgefunden";
CM_ SG_ 1313 STH_LED "Funktionslampe";
CM_ SG_ 1313 STH_Motorvorwaermung "Info an der Motor, dass der Aufheizvorgang mit Motorvorwärmung erfolgt ist";
CM_ SG_ 1313 STH_Pumpen_Anf_extern "Anforderung der motorseitigen elektr. (externen) Wasserpumpe zur Kreislaufunterstützung im Standheizbetrieb";
CM_ SG_ 1313 STH_Servicemode "Rückmeldung, dass die Standheizung sich gerade im Diagnosemodus befindet, gestartet über Diagnosetester";
CM_ SG_ 1313 STH_SH_ZH "0 = Heizgerät ist Standheizung
1 = Heizgerät ist Zuheizer
Gerätekennung WZH oder ZH
";
CM_ SG_ 1313 STH_Start_folgt "Thema Start/Stop: Im Stop-Modus muß das KBT einen Wiederstart anfordern, da ein STH-Start notwendig ist.";
CM_ SG_ 1313 STH_Texte "Anforderung der unterschiedlichen Anzeigetexte im Mitteldisplay des Kombi.

0: Keine Anzeige
1: Kein Standheizungs- bzw Lueftungsbetrieb wegen Batteriemanagementeinschraenkung
2: Kein Standheizungs- bzw Lueftungsbetrieb wegen Kraftstoffmangels
3: Kei";
CM_ SG_ 1313 STH_Ventil_Status "Statusrückmeldung Ansteuerung 3/2 Wege-Ventil";
CM_ SG_ 1313 STH_Ventiloeffnungszeit "Die Standheizung sendet an den Motor die Information darüber wie lange das Magnetventil die Wasserkreisläufe von 'klein' aus 'gross' geschaltet hat. ";
CM_ SG_ 1313 STH_Waermeeintrag "Signal enthält die Brenndauer in 1min-Schritten, über welche die Standheizung gelaufen ist";
CM_ SG_ 1313 STH_war_aktiv "Bit beeinhaltet die Info, dass die Standheizung während der letzten halbe Stunde aktiv war.";
CM_ SG_ 1313 STH_Wassertemp "Kühlmitteltemperatur der Standheizung";
CM_ SG_ 1313 STH_Zusatzheizung "Kraftstoffzuheizer aktiv";

CM_ SG_ 1650 STH_ZZ_Betriebsdauer "Betriebsdauer der Standheizung, die über die Funkfernbedienung verändert wurde";
CM_ SG_ 1650 STH_ZZ_Betriebsmodus "Betriebsdauerberechnung anhand Aussentemperaturauswertung mit Faktor 'ZZ_Betriebsmodus'";
CM_ SG_ 1650 STH_ZZ_Minute "Zielzeittimeranzeige im Display des MMI (Minute); Initwert ist der zuletzt gültige Wert";
CM_ SG_ 1650 STH_ZZ_Monat "Zielzeittimeranzeige im Display des MMI (Datum, Monat); Initwert ist der zuletzt gültige Wert";
CM_ SG_ 1650 STH_ZZ_Status_Timer "Zielzeittimeranzeige im Display des MMI (Timer aktiv/n.aktiv)";
CM_ SG_ 1650 STH_ZZ_Stunde "Zielzeittimeranzeige im Display des MMI (Stunde); Initwert ist der zuletzt gültige Wert";
CM_ SG_ 1650 STH_ZZ_Tag "Zielzeittimeranzeige im Display des MMI (Datum, Tag); Initwert ist der zuletzt gültige Wert";

CM_ SG_ 505 ACA_HF_Grund_AV_AB "Abschaltbedingung und Aktivierverhinderung";
CM_ SG_ 505 ACA_HF_Status "Status der Hands-Off-Querfuehrung";
CM_ SG_ 505 ACA_QF_Fahreruebernahme "Anforderung einer Fahrerübernhame durch die ACA Querführung für die HMI Ansteuerung im ACC-SG";
CM_ SG_ 505 ACA_QF_Status_Anzeige "Status der ACA Querführung, angepasst für die HMI Ansteuerung im ACC-SG";
CM_ SG_ 505 ACF_Spurwechsel_moeglich "Spurwechselmöglichkeit in Überholrichtung (verkehrssinnabh.) gegeben";
CM_ SG_ 505 ACF_Spurwechsel_wahrscheinlich "Spurwechsel in Überholrichtung (verkehrssinnabh.) wahrscheinlich";
CM_ SG_ 505 ACF_SwuFahrerUnaufmerksam "Erkannte Fahrerunaufmerksamkeit von der FZE (ACF)";
CM_ SG_ 505 FZE_Spurwechsel_erkannt_li "Spurwechsel nach links erkannt.";
CM_ SG_ 505 FZE_Spurwechsel_erkannt_re "Spurwechsel nach rechts erkannt.";
CM_ SG_ 505 FZE_STP_Abschaltbedingung "Es liegt eine FZE Bedienhandlung für eine Abschaltung vor";
CM_ SG_ 505 FZE_STP_Aktivierverhinderung "Aktivierverhinderungen STP aus Sicht der FZE";
CM_ SG_ 505 FZE_STP_Status "'Initialisierung / Auskodiert
FZE_STP Signale können verwendet werden
Es liegt ein reversibler Fehler für STP Signale vor
Es liegt ein irreversibler Fehler für STP Signale vor'
";
CM_ SG_ 505 STP_03_BZ "Botschaftszähler
Botschaft asynchron geroutet. Zählerwert kann springen.";
CM_ SG_ 505 STP_03_CRC "End-to-End Absicherung";
CM_ SG_ 505 STP_Funktion_freigegeben "Gibt in ASIL D an, ob die Funktion Staupilot zum Betrieb freigegeben ist.";
CM_ SG_ 505 STP_Notlaufaktivierung "Aktivierung des Notlaufs im ESC/EBKV durch den STP";
CM_ SG_ 505 STP_Slave_Status "Zustandsbeschreibung für STP-Slave-State-Machine";

CM_ SG_ 783 ASW_Kombitexte "ASW_Kombitexte bestimmt welcher Text im Kombi angezeigt wird. Darüber hinaus werden auch Kombi-Akkustik durch dieses Signal ausgelöst.

Dieses Signal ersetzt SWA_Anzeigen für den ASW-Anteil. Der SWA-Anteil des alten Signals findet sich in SWA-Kombitexte";
CM_ SG_ 783 ASW_Modus "gibt die Verfügbarkeit der ASW Modus an";
CM_ SG_ 783 ASW_Status "Funktionsstatus Ausstiegswarnung (ASW)";
CM_ SG_ 783 ASW_Warnung_BFS "Modus Beifahrerseite der Funktion Ausstiegswarnung (ASW)";
CM_ SG_ 783 ASW_Warnung_FS "Modus Beifahrerseite der Funktion Ausstiegswarnung (ASW)";
CM_ SG_ 783 Heckradar_Kombitexte "Heckradar_Kombitexte bestimmt welcher Text im Kombi angezeigt wird. Darüber hinaus werden auch Kombi-Akkustik durch dieses Signal ausgelöst.

Dieses Signal ersetzt SWA_Anzeigen und deckt alle Kombinationsmöglichkeiten der Heckradarfunktionen ab. Die Fun";
CM_ SG_ 783 HRE_Anzeigetexte "HRE-Texte und -Akustik zur Anzeige im Kombiinstrument";
CM_ SG_ 783 RCTA_Kombitexte "RCTA_Kombitexte bestimmt welcher Text im Kombi angezeigt wird. Darüber hinaus werden auch Kombi-Akkustik durch dieses Signal ausgelöst.";
CM_ SG_ 783 SWA_01_BZ "Fehlende Beschreibung (Import)";
CM_ SG_ 783 SWA_01_CRC "Für MLB:
'Berechnung siehe Lastenheft 'Kommunikationsabsicherung für FlexRay und CAN''

Ab MQB und MLBevo:
'Berechnung siehe Lastenheft 'End-to-End Kommunikationsabsicherung''

Endwerte siehe Begleitdokument 'S-PDU Kennungsfolgen'";
CM_ SG_ 783 SWA_Anzeigen "SWA- Texte und -Akustik zur Anzeige im Kombiinstrument
0x7-0xF = reserviert";
CM_ SG_ 783 SWA_Blindheit_erkannt "SWA erkennt selbständig eigene Blindheit durch äußere Einflüsse.";
CM_ SG_ 783 SWA_FT_RueckLED "SWA/ASW Rückmelde-LED. Zeigt den Aktivierungszustand der Funktionen SWA/ASW";
CM_ SG_ 783 SWA_Infostufe_SWA_li "Aktion der SWA-Funktion auf der entsprechenden Fahrzeugseite";
CM_ SG_ 783 SWA_Infostufe_SWA_re "Aktion der SWA-Funktion auf der entsprechenden Fahrzeugseite";
CM_ SG_ 783 SWA_Kolonne_li "Info, dass auf der entspr. Spur mehr als zwei Fahrzeuge zu finden sind. ";
CM_ SG_ 783 SWA_Kolonne_mi "Info, dass auf der entspr. Spur mehr als zwei Fahrzeuge zu finden sind. ";
CM_ SG_ 783 SWA_Kolonne_re "Info, dass auf der entspr. Spur mehr als zwei Fahrzeuge zu finden sind. ";
CM_ SG_ 783 SWA_Modus "gibt die Verfügbarkeit der SWA Modus an";
CM_ SG_ 783 SWA_rel_Fehler "Hinweis: In Zukunft das Signal SWA_Modus anstatt SWA_rel_Fehler verwenden!

SWA erkennt einen Fehler, die Objektdetektion betreffend, mit FSP-Eintrag.";
CM_ SG_ 783 SWA_rel_Nichtverf "Hinweis: In Zukunft das Signal SWA_Modus anstatt SWA_rel_Nichtverf verwenden!

SWA erkennt eine Nichtverfuegbarkeit, die Objektdetektion betreffend, ohne FSP-Eintrag";
CM_ SG_ 783 SWA_Sta_aktiv "SWA Status aktiv; Lampenansteuerung im Kombi";
CM_ SG_ 783 SWA_Sta_passiv "Hinweis: In Zukunft das Signal SWA_Status anstatt SWA_Sta_passiv verwenden!

SWA Status passiv; Lampenansteuerung im Kombi";
CM_ SG_ 783 SWA_Standziele_li "Hinweis: In Zukunft das Signal SWA_StrukturLinks_querAbstand anstatt SWA_Standziele_li verwenden!

Abstand zwischen Fahrzeug und Standziele links geringer als ein applizierbarer Wert.";
CM_ SG_ 783 SWA_Standziele_re "Hinweis: In Zukunft das Signal SWA_StrukturRechts_querAbstand anstatt SWA_Standziele_re verwenden!

Abstand zwischen Fahrzeug und Standziele links geringer als ein applizierbarer Wert.";
CM_ SG_ 783 SWA_Status_02 "gibt die Verfügbarkeit der SWA_Status an";
CM_ SG_ 783 SWA_Warnung_SWA_li "Aktion der SWA-Funktion auf der entsprechenden Fahrzeugseite";
CM_ SG_ 783 SWA_Warnung_SWA_re "Aktion der SWA-Funktion auf der entsprechenden Fahrzeugseite";

CM_ SG_ 673 SWA_LED_Hell_BFS "Helligkeitswert SWA LED Beifahrerseite";
CM_ SG_ 673 SWA_LED_Hell_FS "Helligkeitswert SWA LED Fahrerseite";
CM_ SG_ 673 SWA_LED_Modus_BFS "Ansteuerung SWA LED Beifahrerseite";
CM_ SG_ 673 SWA_LED_Modus_FS "Ansteuerung SWA LED Fahrerseite";

CM_ SG_ 1413 GW_KD_Fehler "Kundendienstfehlerbit Gateway zur Anzeige eines im Gateway abgelegten Fehlerspeichereintrages.";
CM_ SG_ 1413 SI_BUS_01 "MQB/MQB_A0/PQ26: ACAN
MQB2020: ACAN(FD)
MLBevo: HCAN
E3_Volumen: ACAN(FD)
MQBw_Baseline: ACAN(FD)";
CM_ SG_ 1413 SI_BUS_02 "MQB/MQB A0 Standard+, High: FCAN
MQB2020: FCAN(FD)
MLBevo: Frei
E3_Volumen: FCAN(FD)
MQBw_Baseline: FCAN(FD)";
CM_ SG_ 1413 SI_BUS_03 "MQB/MQB A0/PQ26: KCAN
MQB2020: KCAN
MLBevo: KCAN
E3_Volumen: KCAN(HS) / K2CAN(FD) (Buskopplung)
MQBw_Baseline: KCAN(HS)";
CM_ SG_ 1413 SI_BUS_04 "MQB/MQB A0 Standard+, High: ICAN
MQB2020: ICAN(HS)
MLBevo: ICAN
E3_Volumen: ABCAN(FD)
MQBw_Baseline: ICAN(HS)";
CM_ SG_ 1413 SI_BUS_05 "MQB/MQB A0/PQ26: DiagCAN
MQB2020: DiagCAN(FD)
MLBevo: DiagCAN
E3_Volumen: DiagCAN(FD)
MQBw_Baseline: DiagCAN(FD)";
CM_ SG_ 1413 SI_BUS_06 "MQB/MQB A0/PQ26: ECAN
MQB2020: FASCAN(FD)
MLBevo: ECAN
E3_Volumen: FASCAN_1(FD)
MQBw_Baseline: FASCAN_1(FD)";
CM_ SG_ 1413 SI_BUS_07 "MQB: LIN1 (Energie)
MQB2020: LIN1 (Energie)
MLBevo: LIN1 (Energie)
E3_Volumen: LIN 1 (Energie)
MQBw_Baseline: LIN1 (Energie)";
CM_ SG_ 1413 SI_BUS_08 "MQB: LIN2 (MFL)
MQB2020: LIN2 (MFL)
MLBevo: LIN2 (MFL)
E3_Volumen: LIN2 (MFL)
MQBw_Baseline: LIN2 (MFL)";
CM_ SG_ 1413 SI_BUS_09 "MQB: LIN3 (unbelegt)
MQB2020: LIN3 (Uhr/FES)
MLBevo: LIN3 (Energie2)
MEB: LIN3
E³ 1.1 UNECE: MDKCAN";
CM_ SG_ 1413 SI_BUS_10 "MLBevo: Flexray
MQB2020: MCAN
MQBw_Baseline: FASCAN_2(FD)
E³ 1.1 UNECE: FASCAN_2(FD)";
CM_ SG_ 1413 SI_BUS_11 "MLBevo: Ethernet
MEB: LIN4";
CM_ SG_ 1413 SI_BUS_12 "MQB: unbelegt
MLBevo: K2CAN
E3_Volumen: MFLCAN
MQBw_Baseline: K2CAN(FD)";
CM_ SG_ 1413 SI_BUS_13 "MQB: unbelegt
MLBevo: DCAN
MEB: CCAN
MQBw_Baseline: K3CAN(FD)";
CM_ SG_ 1413 SI_BUS_14 "MQB/MQB A0: unbelegt
MQB2020: HCAN
MLBevo: CCAN
E3_Volumen: EVCAN(FD)
MQBw_Baseline: EVCANFD(FD)";
CM_ SG_ 1413 SI_BUS_15 "MQB: frei
MQB2020: frei
MLBevo: frei
MEB: AFSCAN";
CM_ SG_ 1413 SI_Bus_Identifikation "Das Signal identifiziert den Bus eindeutig. Das Signal ist konstant auf jedem Bus.
Der Signalwert entspricht dem Wert 'Busnummer' aus der VW80127 Gateway_component_list_databus_identification (0x2A2D) 'Bus-Identifier'.";
CM_ SG_ 1413 SI_CAB "CAB = Clusteraktivbits 
(Verwendung nur für Empfänger die nicht den AutoSar-SSW Stack implementiert haben)";
CM_ SG_ 1413 SI_Diagnose_Aktiv "Gibt an ob Diagnose-Botschaften empfangen werden und somit eine Diagnose aktiv ist.
MQB: Gibt an ob Diagnose-Bus Botschaften empfangen werden und somit eine Diagnose aktiv ist.";
CM_ SG_ 1413 SI_NWDF "Netzwerk-Diagnose Freigebe zur zentralen Aktivierung der Netzwerkdiagnose";
CM_ SG_ 1413 SI_NWDF_gueltig "Gültigkeitsbit zu SI_NWDF gemäß Lastenheft: Zentrale Aktivierung Netzwerkdiagnose";
CM_ SG_ 1413 SI_QRS_Mode "Messmodus Quick-Ruhestrom";
CM_ SG_ 1413 SI_Sammel_SG_Fehler "Anzahl der gesetzten KD-Fehler direkt angeschlossener Steuergeräte der DK3 und DK4 gemäß 80127.
Hinweis: Ein Subbusmaster stellt nur die gesammelte Information der an ihn angeschlossenen Steuergeräte der DK3 und DK4 zur Verfügung.

Für ServiceKey Auswe";
CM_ SG_ 1413 SI_Sammelfehler "Sammelfehlermeldung zur Anzeige im Kombi - siehe Spez. Sammelfehlermeldung
Hinweis: Einzelne Steuergeräte können zur Anpassung an den Produktionsprozess im Gateway auskodiert werden!";
CM_ SG_ 1413 SI_T_Mode "0x0: Transportmodus nicht aktiv
0x1: Transportmodus aktiv";
CM_ SG_ 1413 SI_T_Schutz "Transportschutz-Signal, das bei Transportmodus und Motorlauf aktiv bleibt
0x0: Transportschutz nicht aktiv
0x1: Transportschutz aktiv";

CM_ SG_ 1375 TME_Absperrventil1_oeffnen "Signal an Standheizungs-SG das Absperrrventil anzusteuern";
CM_ SG_ 1375 TME_AC_LED "Steuerung der LED in der AC-Taste des KBTs";
CM_ SG_ 1375 TME_AC_Rueckmeldung "Status des Elektrischen Klimakompressors";
CM_ SG_ 1375 TME_Freigabe_Luft_PTC "Freigabe des Zuheizers im Klimagerät";
CM_ SG_ 1375 TME_Freigabe_Vorkond "Freigabe an das KBT, mit dem Innenraumkonditionieren zu beginnen.";
CM_ SG_ 1375 TME_Frischluftklappe_Soll "Sollvorgabe der Frischluftklappenstellung bei speziellem Heizbetrieb, z.B. Wärmepumpe";
CM_ SG_ 1375 TME_Heizstrategie "Info über aktuelle Heizstrategie an KBT";
CM_ SG_ 1375 TME_Heizungspumpen_Anst "Anforderung Heizungspumpenansteuerung";
CM_ SG_ 1375 TME_Kbr_Innenraum "Vorhandensein der Klimabereitschaft für Innenraum";
CM_ SG_ 1375 TME_Klima_Defizit "Für Innennraumklimatisierung aktuell nicht verfügbare  Leistung (Defizit = Istleistung - Solleistung)";
CM_ SG_ 1375 TME_Kuehlmittel_Sensor "Signal der Sensorelektroden für die Kühlmittelreserve aktuell, entstört, bewertet (OK/Mangel)
Signalaenderung BEV: Zusaetzlich zum Kuehlmittelsensor werden Fehler an Wasserpumpe des Kuehlsystems auf das Fehlerbit gemappt.";
CM_ SG_ 1375 TME_Nachlaufzeit_Heizp "Nachlaufzeit für Heizungspumpe";
CM_ SG_ 1375 TME_Systemstatus "Systemstatus der TME";
CM_ SG_ 1375 TME_Temp_KM_vor_HWT "Kühlmitteltemperatur vor HWT";
CM_ SG_ 1375 TME_Umluftklappe_Soll "Sollvorgabe der Umluftklappenstellung bei speziellem Heizbetrieb, z.B. Wärmepumpe";
CM_ SG_ 1375 TME_Verdampfer_Status "Verdampfer wird vom Kältemittel durchströmt";
CM_ SG_ 1375 TME_VoKo_Strategie_Anzeige "rueckgemeldete VoKo-Strategie fuer Anzeige
";
CM_ SG_ 1375 TME_Waermepumpe_aktiv "Aktivierungszustand der Wärmepumpe für Innenraumheizen";
CM_ SG_ 1375 TME_Zuheizer_Freigabe "Freigabe-Signal für Verbrennungszuheizfunktion";

CM_ SG_ 2527679762 TPUI_WarnLvlCmft "Display warning level for comfort pressure warning";
CM_ SG_ 2527679762 TPUI_WarnLvlMaxV "Display warning level for maxSpeed warning";
BA_DEF_REL_ BU_SG_REL_  "GenSigTimeoutTime" INT 0 65535;
BA_DEF_ BO_  "DiagRequest" ENUM "No", "Yes";
BA_DEF_ BO_  "DiagResponse" ENUM "No", "Yes";
BA_DEF_ BO_  "DiagState" ENUM "No", "Yes";
BA_DEF_ BO_  "GenMsgChkConstant" HEX 0 4095;
BA_DEF_ BO_  "GenMsgCycleTime" INT 0 65535;
BA_DEF_ BO_  "GenMsgCycleTimeFast" INT 0 65535;
BA_DEF_ BO_  "GenMsgDelayTime" INT 0 100000;
BA_DEF_ BO_  "GenMsgILSupport" ENUM "No", "Yes";
BA_DEF_ BO_  "GenMsgNrOfRepetition" INT 0 100;
BA_DEF_ BO_  "GenMsgPDUConstants" STRING;
BA_DEF_ BO_  "GenMsgSendType" ENUM "Cyclic", "not_used", "not_used", "not_used", "not_used", "not_used", "not_used", "IfActive", "NoMsgSendType";
BA_DEF_ BO_  "GenMsgStartDelayTime" INT 0 100000;
BA_DEF_ BO_  "NmMessage" ENUM "No", "Yes";
BA_DEF_ BO_  "NmhMessage" ENUM "No", "Yes";
BA_DEF_ BO_  "MsgType" ENUM "Application", "NM ", "NMH", "TP2.0", "ISO-TP ", "BAP", "EID", "KS", "XCP_PRE_CONFIGURED", "XCP_RUNTIME_CONFIGURED";
BA_DEF_ BO_  "VAGTP20_API" HEX 0 255;
BA_DEF_ BO_  "VAGTP20_DynConnection" ENUM "No", "Yes";
BA_DEF_ BO_  "VAGTP20_DynSetup" ENUM "No", "Yes";
BA_DEF_ BO_  "VAGTP20_StatConnection" ENUM "No", "Yes";
BA_DEF_ SG_  "GenSigActiveRepetitions" INT -2147483648 2147483647;
BA_DEF_ SG_  "GenSigInactiveValue" INT -2147483648 2147483647;
BA_DEF_ SG_  "GenSigSendType" ENUM "Cyclic", "OnWrite", "OnWriteWithRepetition", "OnChange", "OnChangeWithRepetition", "IfActive", "IfActiveWithRepetition", "NoSigSendType", "OnChangeAndIfActive", "OnChangeAndIfActiveWithRepetition";
BA_DEF_ SG_  "GenSigStartValue" INT -2147483648 2147483647;
BA_DEF_ SG_  "NWM-WakeupAllowed" ENUM "No", "Yes";
BA_DEF_ SG_  "GenSigFuncType" ENUM "NoFunction", "MsgCounter", "CRC-8", "XOR", "XOR-2", "DatedBit", "SW-Kl15", "CHK", "Constant", "Protocol", "CRC-8-SAE_J1850", "CRC-32", "DataLength", "DataID", "MsgCounter16", "SOK-Signatur", "Cluster";
BA_DEF_ SG_  "GenSigSwitchedByIgnition" ENUM "No", "Yes";
BA_DEF_ SG_  "Fehlerwert" HEX 0 2147483647;
BA_DEF_ SG_  "GenSigMissingSourceValue" HEX 0 2147483647;
BA_DEF_DEF_REL_  "GenSigTimeoutTime" 0;
BA_DEF_DEF_  "DiagRequest" "No";
BA_DEF_DEF_  "DiagResponse" "No";
BA_DEF_DEF_  "DiagState" "No";
BA_DEF_DEF_  "GenMsgChkConstant" 0;
BA_DEF_DEF_  "GenMsgCycleTime" 0;
BA_DEF_DEF_  "GenMsgCycleTimeFast" 0;
BA_DEF_DEF_  "GenMsgDelayTime" 0;
BA_DEF_DEF_  "GenMsgILSupport" "No";
BA_DEF_DEF_  "GenMsgNrOfRepetition" 0;
BA_DEF_DEF_  "GenMsgPDUConstants" "";
BA_DEF_DEF_  "GenMsgSendType" "NoMsgSendType";
BA_DEF_DEF_  "GenMsgStartDelayTime" 0;
BA_DEF_DEF_  "NmMessage" "No";
BA_DEF_DEF_  "NmhMessage" "No";
BA_DEF_DEF_  "MsgType" "Application";
BA_DEF_DEF_  "VAGTP20_API" 0;
BA_DEF_DEF_  "VAGTP20_DynConnection" "No";
BA_DEF_DEF_  "VAGTP20_DynSetup" "No";
BA_DEF_DEF_  "VAGTP20_StatConnection" "No";
BA_DEF_DEF_  "GenSigActiveRepetitions" 0;
BA_DEF_DEF_  "GenSigInactiveValue" 0;
BA_DEF_DEF_  "GenSigSendType" "NoSigSendType";
BA_DEF_DEF_  "GenSigStartValue" 0;
BA_DEF_DEF_  "NWM-WakeupAllowed" "No";
BA_DEF_DEF_  "GenSigFuncType" "NoFunction";
BA_DEF_DEF_  "GenSigSwitchedByIgnition" "Yes";
BA_DEF_DEF_  "Fehlerwert" 0;
BA_DEF_DEF_  "GenSigMissingSourceValue" 0;
BA_ "GenMsgCycleTime" BO_ 1529 320;
BA_ "GenMsgILSupport" BO_ 1529 1;
BA_ "GenMsgSendType" BO_ 1529 0;
BA_ "GenMsgCycleTime" BO_ 2589283632 800;
BA_ "GenMsgILSupport" BO_ 2589283632 1;
BA_ "GenMsgPDUConstants" BO_ 2589283632 "0x85,0xb8,0x38,0xf8,0x2b,0x6b,0x19,0x77,0x99,0x64,0x32,0xe3,0x21,0xdf,0xb3,0xf7";
BA_ "GenMsgSendType" BO_ 2589283632 0;
BA_ "GenMsgCycleTime" BO_ 1651 800;
BA_ "GenMsgILSupport" BO_ 1651 1;
BA_ "GenMsgPDUConstants" BO_ 1651 "0xbd,0xa4,0xbc,0xf6,0xb8,0x61,0xf9,0xb2,0x2d,0xf8,0x08,0xf2,0xc1,0x87,0x6b,0x14";
BA_ "GenMsgSendType" BO_ 1651 0;
BA_ "GenMsgCycleTime" BO_ 2463978816 800;
BA_ "GenMsgDelayTime" BO_ 2463978816 10;
BA_ "GenMsgILSupport" BO_ 2463978816 1;
BA_ "GenMsgPDUConstants" BO_ 2463978816 "0xef,0x3a,0xb6,0x66,0xc3,0x88,0x4f,0x62,0x40,0x0b,0x22,0x19,0x1a,0x7d,0x7b,0xcb";
BA_ "GenMsgSendType" BO_ 2463978816 0;
BA_ "GenMsgCycleTime" BO_ 2527679876 200;
BA_ "GenMsgILSupport" BO_ 2527679876 1;
BA_ "GenMsgPDUConstants" BO_ 2527679876 "0x8c,0x50,0xee,0x4f,0xa6,0xcc,0xcf,0x7d,0x2f,0x98,0x6b,0x27,0x41,0x9f,0x93,0xba";
BA_ "GenMsgSendType" BO_ 2527679876 0;
BA_ "GenMsgCycleTime" BO_ 1711 1000;
BA_ "GenMsgDelayTime" BO_ 1711 100;
BA_ "GenMsgILSupport" BO_ 1711 1;
BA_ "GenMsgSendType" BO_ 1711 0;
BA_ "GenMsgCycleTime" BO_ 1440 200;
BA_ "GenMsgILSupport" BO_ 1440 1;
BA_ "GenMsgSendType" BO_ 1440 0;
BA_ "GenMsgCycleTime" BO_ 1528 1000;
BA_ "GenMsgDelayTime" BO_ 1528 100;
BA_ "GenMsgILSupport" BO_ 1528 1;
BA_ "GenMsgSendType" BO_ 1528 0;
BA_ "GenMsgCycleTime" BO_ 424 20;
BA_ "GenMsgILSupport" BO_ 424 1;
BA_ "GenMsgPDUConstants" BO_ 424 "0x11,0x17,0xbb,0xaa,0xd0,0x83,0xe1,0x8e,0xa3,0x4d,0xef,0x50,0x88,0xa5,0x22,0xf6";
BA_ "GenMsgSendType" BO_ 424 0;
BA_ "GenMsgCycleTime" BO_ 1011 100;
BA_ "GenMsgILSupport" BO_ 1011 1;
BA_ "GenMsgSendType" BO_ 1011 0;
BA_ "GenMsgCycleTime" BO_ 1507 500;
BA_ "GenMsgILSupport" BO_ 1507 1;
BA_ "GenMsgSendType" BO_ 1507 0;
BA_ "GenMsgCycleTime" BO_ 1508 500;
BA_ "GenMsgDelayTime" BO_ 1508 50;
BA_ "GenMsgILSupport" BO_ 1508 1;
BA_ "GenMsgSendType" BO_ 1508 0;
BA_ "GenMsgCycleTime" BO_ 1509 1000;
BA_ "GenMsgILSupport" BO_ 1509 1;
BA_ "GenMsgSendType" BO_ 1509 0;
BA_ "GenMsgCycleTime" BO_ 1526 500;
BA_ "GenMsgDelayTime" BO_ 1526 50;
BA_ "GenMsgILSupport" BO_ 1526 1;
BA_ "GenMsgSendType" BO_ 1526 0;
BA_ "GenMsgCycleTime" BO_ 2527679503 500;
BA_ "GenMsgILSupport" BO_ 2527679503 1;
BA_ "GenMsgSendType" BO_ 2527679503 0;
BA_ "GenMsgCycleTime" BO_ 2589283459 500;
BA_ "GenMsgILSupport" BO_ 2589283459 1;
BA_ "GenMsgSendType" BO_ 2589283459 0;
BA_ "GenMsgCycleTime" BO_ 2589283460 500;
BA_ "GenMsgILSupport" BO_ 2589283460 1;
BA_ "GenMsgSendType" BO_ 2589283460 0;
BA_ "GenMsgCycleTime" BO_ 2463978593 100;
BA_ "GenMsgILSupport" BO_ 2463978593 1;
BA_ "GenMsgSendType" BO_ 2463978593 0;
BA_ "GenMsgCycleTime" BO_ 1510 1000;
BA_ "GenMsgILSupport" BO_ 1510 1;
BA_ "GenMsgSendType" BO_ 1510 0;
BA_ "GenMsgCycleTime" BO_ 1512 1000;
BA_ "GenMsgILSupport" BO_ 1512 1;
BA_ "GenMsgSendType" BO_ 1512 0;
BA_ "GenMsgCycleTime" BO_ 2589283497 500;
BA_ "GenMsgILSupport" BO_ 2589283497 1;
BA_ "GenMsgSendType" BO_ 2589283497 0;
BA_ "GenMsgCycleTime" BO_ 2589283498 500;
BA_ "GenMsgILSupport" BO_ 2589283498 1;
BA_ "GenMsgSendType" BO_ 2589283498 0;
BA_ "GenMsgCycleTime" BO_ 2589283413 500;
BA_ "GenMsgILSupport" BO_ 2589283413 1;
BA_ "GenMsgSendType" BO_ 2589283413 0;
BA_ "GenMsgCycleTime" BO_ 2589283414 500;
BA_ "GenMsgILSupport" BO_ 2589283414 1;
BA_ "GenMsgSendType" BO_ 2589283414 0;
BA_ "GenMsgCycleTime" BO_ 980 200;
BA_ "GenMsgCycleTimeFast" BO_ 980 80;
BA_ "GenMsgDelayTime" BO_ 980 40;
BA_ "GenMsgILSupport" BO_ 980 1;
BA_ "GenMsgNrOfRepetition" BO_ 980 5;
BA_ "GenMsgPDUConstants" BO_ 980 "0xc3,0x79,0xbf,0xdb,0xe9,0x11,0x46,0x86,0x69,0xb6,0x9b,0x29,0x15,0x9c,0x45,0x0d";
BA_ "GenMsgSendType" BO_ 980 0;
BA_ "GenMsgCycleTime" BO_ 1710 1000;
BA_ "GenMsgCycleTimeFast" BO_ 1710 100;
BA_ "GenMsgDelayTime" BO_ 1710 50;
BA_ "GenMsgILSupport" BO_ 1710 1;
BA_ "GenMsgNrOfRepetition" BO_ 1710 5;
BA_ "GenMsgSendType" BO_ 1710 0;
BA_ "GenMsgCycleTime" BO_ 1313 200;
BA_ "GenMsgILSupport" BO_ 1313 1;
BA_ "GenMsgSendType" BO_ 1313 0;
BA_ "GenMsgCycleTime" BO_ 1650 500;
BA_ "GenMsgDelayTime" BO_ 1650 50;
BA_ "GenMsgILSupport" BO_ 1650 1;
BA_ "GenMsgSendType" BO_ 1650 0;
BA_ "GenMsgCycleTime" BO_ 505 500;
BA_ "GenMsgILSupport" BO_ 505 1;
BA_ "GenMsgPDUConstants" BO_ 505 "0x14,0xf8,0xf6,0x94,0x2a,0x12,0x39,0x3d,0x98,0x3f,0xfb,0x9d,0x36,0xca,0x1d,0xe0";
BA_ "GenMsgSendType" BO_ 505 0;
BA_ "GenMsgChkConstant" BO_ 783 12;
BA_ "GenMsgCycleTime" BO_ 783 50;
BA_ "GenMsgILSupport" BO_ 783 1;
BA_ "GenMsgPDUConstants" BO_ 783 "0x0c,0x0c,0x0c,0x0c,0x0c,0x0c,0x0c,0x0c,0x0c,0x0c,0x0c,0x0c,0x0c,0x0c,0x0c,0x0c";
BA_ "GenMsgSendType" BO_ 783 0;
BA_ "GenMsgCycleTime" BO_ 673 200;
BA_ "GenMsgDelayTime" BO_ 673 40;
BA_ "GenMsgILSupport" BO_ 673 1;
BA_ "GenMsgSendType" BO_ 673 0;
BA_ "GenMsgCycleTime" BO_ 1413 1000;
BA_ "GenMsgDelayTime" BO_ 1413 10;
BA_ "GenMsgILSupport" BO_ 1413 1;
BA_ "GenMsgSendType" BO_ 1413 0;
BA_ "GenMsgStartDelayTime" BO_ 1413 85;
BA_ "GenMsgCycleTime" BO_ 1375 500;
BA_ "GenMsgDelayTime" BO_ 1375 20;
BA_ "GenMsgILSupport" BO_ 1375 1;
BA_ "GenMsgSendType" BO_ 1375 0;
BA_ "GenMsgCycleTime" BO_ 2527679762 200;
BA_ "GenMsgILSupport" BO_ 2527679762 1;
BA_ "GenMsgSendType" BO_ 2527679762 0;
BA_ "GenSigSendType" SG_ 1529 RDK_angelernt 0;
BA_ "GenSigSwitchedByIgnition" SG_ 1529 RDK_angelernt 0;
BA_ "GenSigSendType" SG_ 1529 RDK_FMVSS138_Lampe 0;
BA_ "GenSigSwitchedByIgnition" SG_ 1529 RDK_FMVSS138_Lampe 0;
BA_ "GenSigSendType" SG_ 1529 RDK_FMVSS138_MIL 0;
BA_ "GenSigSwitchedByIgnition" SG_ 1529 RDK_FMVSS138_MIL 0;
BA_ "GenSigSendType" SG_ 1529 RDK_Kalibrierung 0;
BA_ "GenSigSwitchedByIgnition" SG_ 1529 RDK_Kalibrierung 0;
BA_ "GenSigSendType" SG_ 1529 RDK_Reifendruck_Lampe 0;
BA_ "GenSigSwitchedByIgnition" SG_ 1529 RDK_Reifendruck_Lampe 0;
BA_ "GenSigSendType" SG_ 1529 RDK_Reifentemperatur_Lampe 0;
BA_ "GenSigSwitchedByIgnition" SG_ 1529 RDK_Reifentemperatur_Lampe 0;
BA_ "GenSigSendType" SG_ 1529 RDK_RS_aktiv 0;
BA_ "GenSigSwitchedByIgnition" SG_ 1529 RDK_RS_aktiv 0;
BA_ "GenSigSendType" SG_ 1529 RDK_Text_7 0;
BA_ "GenSigSwitchedByIgnition" SG_ 1529 RDK_Text_7 0;
BA_ "GenSigSendType" SG_ 1529 RDK_W_1_Reifen_HL 0;
BA_ "GenSigSwitchedByIgnition" SG_ 1529 RDK_W_1_Reifen_HL 0;
BA_ "GenSigSendType" SG_ 1529 RDK_W_1_Reifen_HR 0;
BA_ "GenSigSwitchedByIgnition" SG_ 1529 RDK_W_1_Reifen_HR 0;
BA_ "GenSigSendType" SG_ 1529 RDK_W_1_Reifen_VL 0;
BA_ "GenSigSwitchedByIgnition" SG_ 1529 RDK_W_1_Reifen_VL 0;
BA_ "GenSigSendType" SG_ 1529 RDK_W_1_Reifen_VR 0;
BA_ "GenSigSwitchedByIgnition" SG_ 1529 RDK_W_1_Reifen_VR 0;
BA_ "GenSigSendType" SG_ 1529 RDK_W_2_Reifen_HL 0;
BA_ "GenSigSwitchedByIgnition" SG_ 1529 RDK_W_2_Reifen_HL 0;
BA_ "GenSigSendType" SG_ 1529 RDK_W_2_Reifen_HR 0;
BA_ "GenSigSwitchedByIgnition" SG_ 1529 RDK_W_2_Reifen_HR 0;
BA_ "GenSigSendType" SG_ 1529 RDK_W_2_Reifen_VL 0;
BA_ "GenSigSwitchedByIgnition" SG_ 1529 RDK_W_2_Reifen_VL 0;
BA_ "GenSigSendType" SG_ 1529 RDK_W_2_Reifen_VR 0;
BA_ "GenSigSwitchedByIgnition" SG_ 1529 RDK_W_2_Reifen_VR 0;
BA_ "GenSigSendType" SG_ 1529 RDK_Warnungen_02 0;
BA_ "GenSigSwitchedByIgnition" SG_ 1529 RDK_Warnungen_02 0;
BA_ "GenSigSendType" SG_ 2589283632 RDK_03_BZ 0;
BA_ "GenSigFuncType" SG_ 2589283632 RDK_03_BZ 1;
BA_ "GenSigSwitchedByIgnition" SG_ 2589283632 RDK_03_BZ 0;
BA_ "GenSigSendType" SG_ 2589283632 RDK_03_CRC 0;
BA_ "GenSigFuncType" SG_ 2589283632 RDK_03_CRC 2;
BA_ "GenSigSwitchedByIgnition" SG_ 2589283632 RDK_03_CRC 0;
BA_ "GenSigSendType" SG_ 2589283632 RDK_Diff_Druck_HL 0;
BA_ "GenSigSwitchedByIgnition" SG_ 2589283632 RDK_Diff_Druck_HL 0;
BA_ "GenSigSendType" SG_ 2589283632 RDK_Diff_Druck_HR 0;
BA_ "GenSigSwitchedByIgnition" SG_ 2589283632 RDK_Diff_Druck_HR 0;
BA_ "GenSigSendType" SG_ 2589283632 RDK_Diff_Druck_VL 0;
BA_ "GenSigSwitchedByIgnition" SG_ 2589283632 RDK_Diff_Druck_VL 0;
BA_ "GenSigSendType" SG_ 2589283632 RDK_Diff_Druck_VR 0;
BA_ "GenSigSwitchedByIgnition" SG_ 2589283632 RDK_Diff_Druck_VR 0;
BA_ "GenSigSendType" SG_ 2589283632 RDK_Reifengroesse 0;
BA_ "GenSigSwitchedByIgnition" SG_ 2589283632 RDK_Reifengroesse 0;
BA_ "GenSigSendType" SG_ 2589283632 RDK_Reifentyp 0;
BA_ "GenSigSendType" SG_ 2589283632 RDK_Reifentyp_02 0;
BA_ "GenSigSwitchedByIgnition" SG_ 2589283632 RDK_Reifentyp_02 0;
BA_ "GenSigSendType" SG_ 2589283632 RDK_SollDruck_HA 0;
BA_ "GenSigStartValue" SG_ 2589283632 RDK_SollDruck_HA 63;
BA_ "GenSigSwitchedByIgnition" SG_ 2589283632 RDK_SollDruck_HA 0;
BA_ "GenSigSendType" SG_ 2589283632 RDK_SollDruck_VA 0;
BA_ "GenSigStartValue" SG_ 2589283632 RDK_SollDruck_VA 63;
BA_ "GenSigSwitchedByIgnition" SG_ 2589283632 RDK_SollDruck_VA 0;
BA_ "GenSigSendType" SG_ 1651 RDK_Druck_HL_unkomp 0;
BA_ "GenSigStartValue" SG_ 1651 RDK_Druck_HL_unkomp 63;
BA_ "GenSigSwitchedByIgnition" SG_ 1651 RDK_Druck_HL_unkomp 0;
BA_ "GenSigSendType" SG_ 1651 RDK_Druck_HR_unkomp 0;
BA_ "GenSigStartValue" SG_ 1651 RDK_Druck_HR_unkomp 63;
BA_ "GenSigSwitchedByIgnition" SG_ 1651 RDK_Druck_HR_unkomp 0;
BA_ "GenSigSendType" SG_ 1651 RDK_Druck_VL_unkomp 0;
BA_ "GenSigStartValue" SG_ 1651 RDK_Druck_VL_unkomp 63;
BA_ "GenSigSwitchedByIgnition" SG_ 1651 RDK_Druck_VL_unkomp 0;
BA_ "GenSigSendType" SG_ 1651 RDK_Druck_VR_unkomp 0;
BA_ "GenSigStartValue" SG_ 1651 RDK_Druck_VR_unkomp 63;
BA_ "GenSigSwitchedByIgnition" SG_ 1651 RDK_Druck_VR_unkomp 0;
BA_ "GenSigSendType" SG_ 1651 RDK_R_Temp_HL 0;
BA_ "GenSigStartValue" SG_ 1651 RDK_R_Temp_HL 253;
BA_ "GenSigSwitchedByIgnition" SG_ 1651 RDK_R_Temp_HL 0;
BA_ "Fehlerwert" SG_ 1651 RDK_R_Temp_HL 255;
BA_ "GenSigSendType" SG_ 1651 RDK_R_Temp_HR 0;
BA_ "GenSigStartValue" SG_ 1651 RDK_R_Temp_HR 253;
BA_ "GenSigSwitchedByIgnition" SG_ 1651 RDK_R_Temp_HR 0;
BA_ "Fehlerwert" SG_ 1651 RDK_R_Temp_HR 255;
BA_ "GenSigSendType" SG_ 1651 RDK_R_Temp_VL 0;
BA_ "GenSigStartValue" SG_ 1651 RDK_R_Temp_VL 253;
BA_ "GenSigSwitchedByIgnition" SG_ 1651 RDK_R_Temp_VL 0;
BA_ "Fehlerwert" SG_ 1651 RDK_R_Temp_VL 255;
BA_ "GenSigSendType" SG_ 1651 RDK_R_Temp_VR 0;
BA_ "GenSigStartValue" SG_ 1651 RDK_R_Temp_VR 253;
BA_ "GenSigSwitchedByIgnition" SG_ 1651 RDK_R_Temp_VR 0;
BA_ "Fehlerwert" SG_ 1651 RDK_R_Temp_VR 255;
BA_ "GenSigSendType" SG_ 1651 RDK_Signal_Alter_HL 0;
BA_ "GenSigSwitchedByIgnition" SG_ 1651 RDK_Signal_Alter_HL 0;
BA_ "GenSigSendType" SG_ 1651 RDK_Signal_Alter_HR 0;
BA_ "GenSigSwitchedByIgnition" SG_ 1651 RDK_Signal_Alter_HR 0;
BA_ "GenSigSendType" SG_ 1651 RDK_Signal_Alter_VL 0;
BA_ "GenSigSwitchedByIgnition" SG_ 1651 RDK_Signal_Alter_VL 0;
BA_ "GenSigSendType" SG_ 1651 RDK_Signal_Alter_VR 0;
BA_ "GenSigSwitchedByIgnition" SG_ 1651 RDK_Signal_Alter_VR 0;
BA_ "GenSigSendType" SG_ 2463978816 RDK_05_BZ 0;
BA_ "GenSigFuncType" SG_ 2463978816 RDK_05_BZ 1;
BA_ "GenSigSwitchedByIgnition" SG_ 2463978816 RDK_05_BZ 0;
BA_ "GenSigSendType" SG_ 2463978816 RDK_05_CRC 0;
BA_ "GenSigFuncType" SG_ 2463978816 RDK_05_CRC 2;
BA_ "GenSigSwitchedByIgnition" SG_ 2463978816 RDK_05_CRC 0;
BA_ "GenSigSendType" SG_ 2463978816 Solldruck_Fahrerauswahl 3;
BA_ "GenSigSwitchedByIgnition" SG_ 2463978816 Solldruck_Fahrerauswahl 0;
BA_ "GenSigSendType" SG_ 2463978816 Solldruck_TempAbhaengig_HL 3;
BA_ "GenSigStartValue" SG_ 2463978816 Solldruck_TempAbhaengig_HL 63;
BA_ "GenSigSwitchedByIgnition" SG_ 2463978816 Solldruck_TempAbhaengig_HL 0;
BA_ "GenSigSendType" SG_ 2463978816 Solldruck_TempAbhaengig_HR 3;
BA_ "GenSigStartValue" SG_ 2463978816 Solldruck_TempAbhaengig_HR 63;
BA_ "GenSigSwitchedByIgnition" SG_ 2463978816 Solldruck_TempAbhaengig_HR 0;
BA_ "GenSigSendType" SG_ 2463978816 Solldruck_TempAbhaengig_VL 3;
BA_ "GenSigStartValue" SG_ 2463978816 Solldruck_TempAbhaengig_VL 63;
BA_ "GenSigSwitchedByIgnition" SG_ 2463978816 Solldruck_TempAbhaengig_VL 0;
BA_ "GenSigSendType" SG_ 2463978816 Solldruck_TempAbhaengig_VR 3;
BA_ "GenSigStartValue" SG_ 2463978816 Solldruck_TempAbhaengig_VR 63;
BA_ "GenSigSwitchedByIgnition" SG_ 2463978816 Solldruck_TempAbhaengig_VR 0;
BA_ "GenSigSendType" SG_ 2463978816 TPMS_WarnWhlChgDet 3;
BA_ "GenSigSwitchedByIgnition" SG_ 2463978816 TPMS_WarnWhlChgDet 0;
BA_ "GenSigSendType" SG_ 2463978816 TPMS_WhlChgDetFrLe 3;
BA_ "GenSigSwitchedByIgnition" SG_ 2463978816 TPMS_WhlChgDetFrLe 0;
BA_ "GenSigSendType" SG_ 2463978816 TPMS_WhlChgDetFrRi 3;
BA_ "GenSigSwitchedByIgnition" SG_ 2463978816 TPMS_WhlChgDetFrRi 0;
BA_ "GenSigSendType" SG_ 2463978816 TPMS_WhlChgDetReLe 3;
BA_ "GenSigSwitchedByIgnition" SG_ 2463978816 TPMS_WhlChgDetReLe 0;
BA_ "GenSigSendType" SG_ 2463978816 TPMS_WhlChgDetReRi 3;
BA_ "GenSigSwitchedByIgnition" SG_ 2463978816 TPMS_WhlChgDetReRi 0;
BA_ "GenSigSendType" SG_ 2527679876 RDK_06_BZ 0;
BA_ "GenSigFuncType" SG_ 2527679876 RDK_06_BZ 1;
BA_ "GenSigSwitchedByIgnition" SG_ 2527679876 RDK_06_BZ 0;
BA_ "GenSigSendType" SG_ 2527679876 RDK_06_CRC 0;
BA_ "GenSigFuncType" SG_ 2527679876 RDK_06_CRC 2;
BA_ "GenSigSwitchedByIgnition" SG_ 2527679876 RDK_06_CRC 0;
BA_ "GenSigSendType" SG_ 2527679876 TPMS_SensPFrLe 0;
BA_ "GenSigStartValue" SG_ 2527679876 TPMS_SensPFrLe 63;
BA_ "GenSigSwitchedByIgnition" SG_ 2527679876 TPMS_SensPFrLe 0;
BA_ "GenSigSendType" SG_ 2527679876 TPMS_SensPFrRi 0;
BA_ "GenSigStartValue" SG_ 2527679876 TPMS_SensPFrRi 63;
BA_ "GenSigSwitchedByIgnition" SG_ 2527679876 TPMS_SensPFrRi 0;
BA_ "GenSigSendType" SG_ 2527679876 TPMS_SensPReLe 0;
BA_ "GenSigStartValue" SG_ 2527679876 TPMS_SensPReLe 63;
BA_ "GenSigSwitchedByIgnition" SG_ 2527679876 TPMS_SensPReLe 0;
BA_ "GenSigSendType" SG_ 2527679876 TPMS_SensPReRi 0;
BA_ "GenSigStartValue" SG_ 2527679876 TPMS_SensPReRi 63;
BA_ "GenSigSwitchedByIgnition" SG_ 2527679876 TPMS_SensPReRi 0;
BA_ "GenSigSendType" SG_ 2527679876 TPMS_SensSigAgeFrLe 0;
BA_ "GenSigStartValue" SG_ 2527679876 TPMS_SensSigAgeFrLe 14;
BA_ "GenSigSwitchedByIgnition" SG_ 2527679876 TPMS_SensSigAgeFrLe 0;
BA_ "Fehlerwert" SG_ 2527679876 TPMS_SensSigAgeFrLe 15;
BA_ "GenSigSendType" SG_ 2527679876 TPMS_SensSigAgeFrRi 0;
BA_ "GenSigStartValue" SG_ 2527679876 TPMS_SensSigAgeFrRi 14;
BA_ "GenSigSwitchedByIgnition" SG_ 2527679876 TPMS_SensSigAgeFrRi 0;
BA_ "Fehlerwert" SG_ 2527679876 TPMS_SensSigAgeFrRi 15;
BA_ "GenSigSendType" SG_ 2527679876 TPMS_SensSigAgeReLe 0;
BA_ "GenSigStartValue" SG_ 2527679876 TPMS_SensSigAgeReLe 14;
BA_ "GenSigSwitchedByIgnition" SG_ 2527679876 TPMS_SensSigAgeReLe 0;
BA_ "Fehlerwert" SG_ 2527679876 TPMS_SensSigAgeReLe 15;
BA_ "GenSigSendType" SG_ 2527679876 TPMS_SensSigAgeReRi 0;
BA_ "GenSigStartValue" SG_ 2527679876 TPMS_SensSigAgeReRi 14;
BA_ "GenSigSwitchedByIgnition" SG_ 2527679876 TPMS_SensSigAgeReRi 0;
BA_ "Fehlerwert" SG_ 2527679876 TPMS_SensSigAgeReRi 15;
BA_ "GenSigSendType" SG_ 1711 RV_Calib_Fehler 3;
BA_ "GenSigSwitchedByIgnition" SG_ 1711 RV_Calib_Fehler 0;
BA_ "GenSigSendType" SG_ 1711 RV_Dark_Screen 3;
BA_ "GenSigSwitchedByIgnition" SG_ 1711 RV_Dark_Screen 0;
BA_ "GenSigSendType" SG_ 1711 RV_Farbe 3;
BA_ "GenSigSwitchedByIgnition" SG_ 1711 RV_Farbe 0;
BA_ "GenSigSendType" SG_ 1711 RV_GL_LWS_Fehler 3;
BA_ "GenSigSwitchedByIgnition" SG_ 1711 RV_GL_LWS_Fehler 0;
BA_ "GenSigSendType" SG_ 1711 RV_GL_side 3;
BA_ "GenSigSendType" SG_ 1711 RV_GL_Trailer_connect 3;
BA_ "GenSigSwitchedByIgnition" SG_ 1711 RV_GL_Trailer_connect 0;
BA_ "GenSigSendType" SG_ 1711 RV_GL_Trunk_open 3;
BA_ "GenSigSwitchedByIgnition" SG_ 1711 RV_GL_Trunk_open 0;
BA_ "GenSigSendType" SG_ 1711 RV_Helligkeit 3;
BA_ "GenSigSwitchedByIgnition" SG_ 1711 RV_Helligkeit 0;
BA_ "GenSigSendType" SG_ 1711 RV_HMI_Mode 3;
BA_ "GenSigSwitchedByIgnition" SG_ 1711 RV_HMI_Mode 0;
BA_ "GenSigSendType" SG_ 1711 RV_Kontrast 3;
BA_ "GenSigSwitchedByIgnition" SG_ 1711 RV_Kontrast 0;
BA_ "GenSigSendType" SG_ 1711 RV_Menu_Item 3;
BA_ "GenSigSwitchedByIgnition" SG_ 1711 RV_Menu_Item 0;
BA_ "GenSigSendType" SG_ 1711 RV_Reinigung_Anf 3;
BA_ "GenSigSwitchedByIgnition" SG_ 1711 RV_Reinigung_Anf 0;
BA_ "GenSigSendType" SG_ 1711 RV_Settings_enabled 3;
BA_ "GenSigSwitchedByIgnition" SG_ 1711 RV_Settings_enabled 0;
BA_ "GenSigSendType" SG_ 1711 RV_System_aktiv 3;
BA_ "GenSigSwitchedByIgnition" SG_ 1711 RV_System_aktiv 0;
BA_ "GenSigSendType" SG_ 1711 RV_Video_on 3;
BA_ "GenSigSwitchedByIgnition" SG_ 1711 RV_Video_on 0;
BA_ "GenSigSendType" SG_ 1711 SV_Video_on 3;
BA_ "GenSigSendType" SG_ 1711 ZFAS_Umfeldbeleuchtung_Anf 3;
BA_ "GenSigSwitchedByIgnition" SG_ 1711 ZFAS_Umfeldbeleuchtung_Anf 0;
BA_ "GenSigSendType" SG_ 1440 LS_defekt 0;
BA_ "GenSigSwitchedByIgnition" SG_ 1440 LS_defekt 0;
BA_ "GenSigSendType" SG_ 1440 LS_Helligkeit_FW 0;
BA_ "GenSigStartValue" SG_ 1440 LS_Helligkeit_FW 1022;
BA_ "GenSigSwitchedByIgnition" SG_ 1440 LS_Helligkeit_FW 0;
BA_ "Fehlerwert" SG_ 1440 LS_Helligkeit_FW 1023;
BA_ "GenSigMissingSourceValue" SG_ 1440 LS_Helligkeit_FW 1023;
BA_ "GenSigSendType" SG_ 1440 LS_Helligkeit_IR 0;
BA_ "GenSigStartValue" SG_ 1440 LS_Helligkeit_IR 254;
BA_ "GenSigSwitchedByIgnition" SG_ 1440 LS_Helligkeit_IR 0;
BA_ "Fehlerwert" SG_ 1440 LS_Helligkeit_IR 255;
BA_ "GenSigMissingSourceValue" SG_ 1440 LS_Helligkeit_IR 255;
BA_ "GenSigSendType" SG_ 1440 LS_Verbau 0;
BA_ "GenSigSwitchedByIgnition" SG_ 1440 LS_Verbau 0;
BA_ "GenSigSendType" SG_ 1440 RLS_Vorfeldhelligkeit_Boost 0;
BA_ "GenSigStartValue" SG_ 1440 RLS_Vorfeldhelligkeit_Boost 15;
BA_ "GenSigSwitchedByIgnition" SG_ 1440 RLS_Vorfeldhelligkeit_Boost 0;
BA_ "GenSigSendType" SG_ 1440 RS_defekt 0;
BA_ "GenSigSwitchedByIgnition" SG_ 1440 RS_defekt 0;
BA_ "GenSigSendType" SG_ 1440 RS_Regenmenge 0;
BA_ "GenSigStartValue" SG_ 1440 RS_Regenmenge 14;
BA_ "GenSigSwitchedByIgnition" SG_ 1440 RS_Regenmenge 0;
BA_ "Fehlerwert" SG_ 1440 RS_Regenmenge 15;
BA_ "GenSigMissingSourceValue" SG_ 1440 RS_Regenmenge 15;
BA_ "GenSigSendType" SG_ 1440 RS_Verbau 0;
BA_ "GenSigSwitchedByIgnition" SG_ 1440 RS_Verbau 0;
BA_ "GenSigSendType" SG_ 1440 RS_Verglasung_schliessen 0;
BA_ "GenSigSwitchedByIgnition" SG_ 1440 RS_Verglasung_schliessen 0;
BA_ "GenSigSendType" SG_ 1440 RS_Wischergeschwindigkeit 0;
BA_ "GenSigSwitchedByIgnition" SG_ 1440 RS_Wischergeschwindigkeit 0;
BA_ "GenSigSendType" SG_ 1528 SAK_Charisma_FahrPr 3;
BA_ "GenSigSendType" SG_ 1528 SAK_Charisma_Status 3;
BA_ "GenSigSendType" SG_ 424 SARA_11_BZ 0;
BA_ "GenSigFuncType" SG_ 424 SARA_11_BZ 1;
BA_ "GenSigSwitchedByIgnition" SG_ 424 SARA_11_BZ 0;
BA_ "GenSigSendType" SG_ 424 SARA_11_CRC 0;
BA_ "GenSigFuncType" SG_ 424 SARA_11_CRC 2;
BA_ "GenSigSwitchedByIgnition" SG_ 424 SARA_11_CRC 0;
BA_ "GenSigSendType" SG_ 424 SARA_Accel_X_r 0;
BA_ "GenSigStartValue" SG_ 424 SARA_Accel_X_r 4096;
BA_ "GenSigSwitchedByIgnition" SG_ 424 SARA_Accel_X_r 0;
BA_ "Fehlerwert" SG_ 424 SARA_Accel_X_r 8191;
BA_ "GenSigSendType" SG_ 424 SARA_Accel_Y_r 0;
BA_ "GenSigStartValue" SG_ 424 SARA_Accel_Y_r 4096;
BA_ "GenSigSwitchedByIgnition" SG_ 424 SARA_Accel_Y_r 0;
BA_ "Fehlerwert" SG_ 424 SARA_Accel_Y_r 8191;
BA_ "GenSigSendType" SG_ 424 SARA_CF_Accel_X_r 0;
BA_ "GenSigStartValue" SG_ 424 SARA_CF_Accel_X_r 4;
BA_ "GenSigSwitchedByIgnition" SG_ 424 SARA_CF_Accel_X_r 0;
BA_ "GenSigSendType" SG_ 424 SARA_CF_Accel_Y_r 0;
BA_ "GenSigStartValue" SG_ 424 SARA_CF_Accel_Y_r 4;
BA_ "GenSigSwitchedByIgnition" SG_ 424 SARA_CF_Accel_Y_r 0;
BA_ "GenSigSendType" SG_ 424 SARA_CF_Omega_Z_r 0;
BA_ "GenSigStartValue" SG_ 424 SARA_CF_Omega_Z_r 4;
BA_ "GenSigSwitchedByIgnition" SG_ 424 SARA_CF_Omega_Z_r 0;
BA_ "GenSigSendType" SG_ 424 SARA_Omega_Z_r 0;
BA_ "GenSigStartValue" SG_ 424 SARA_Omega_Z_r 4096;
BA_ "GenSigSwitchedByIgnition" SG_ 424 SARA_Omega_Z_r 0;
BA_ "Fehlerwert" SG_ 424 SARA_Omega_Z_r 8191;
BA_ "GenSigSendType" SG_ 1011 SCR_01_BZ 0;
BA_ "GenSigFuncType" SG_ 1011 SCR_01_BZ 1;
BA_ "GenSigSwitchedByIgnition" SG_ 1011 SCR_01_BZ 0;
BA_ "GenSigSendType" SG_ 1011 SCR_Dosierpumpe_Drehzahl 0;
BA_ "GenSigStartValue" SG_ 1011 SCR_Dosierpumpe_Drehzahl 2046;
BA_ "GenSigSwitchedByIgnition" SG_ 1011 SCR_Dosierpumpe_Drehzahl 0;
BA_ "Fehlerwert" SG_ 1011 SCR_Dosierpumpe_Drehzahl 2047;
BA_ "GenSigSendType" SG_ 1011 SCR_Druck 0;
BA_ "GenSigStartValue" SG_ 1011 SCR_Druck 1022;
BA_ "GenSigSwitchedByIgnition" SG_ 1011 SCR_Druck 0;
BA_ "Fehlerwert" SG_ 1011 SCR_Druck 1023;
BA_ "GenSigSendType" SG_ 1011 SCR_Level_Aktivtank 0;
BA_ "GenSigStartValue" SG_ 1011 SCR_Level_Aktivtank 1022;
BA_ "GenSigSwitchedByIgnition" SG_ 1011 SCR_Level_Aktivtank 0;
BA_ "Fehlerwert" SG_ 1011 SCR_Level_Aktivtank 1023;
BA_ "GenSigSendType" SG_ 1011 SCR_Level_ReadAbove 0;
BA_ "GenSigSwitchedByIgnition" SG_ 1011 SCR_Level_ReadAbove 0;
BA_ "GenSigSendType" SG_ 1011 SCR_QBit_Level_Aktivtank_02 0;
BA_ "GenSigStartValue" SG_ 1011 SCR_QBit_Level_Aktivtank_02 1;
BA_ "GenSigSwitchedByIgnition" SG_ 1011 SCR_QBit_Level_Aktivtank_02 0;
BA_ "GenSigSendType" SG_ 1011 SCR_Sent_Level_Aktivtank 0;
BA_ "GenSigStartValue" SG_ 1011 SCR_Sent_Level_Aktivtank 1022;
BA_ "GenSigSwitchedByIgnition" SG_ 1011 SCR_Sent_Level_Aktivtank 0;
BA_ "GenSigSendType" SG_ 1011 SCR_Sent_Levelsignal_Status 0;
BA_ "GenSigStartValue" SG_ 1011 SCR_Sent_Levelsignal_Status 7;
BA_ "GenSigSwitchedByIgnition" SG_ 1011 SCR_Sent_Levelsignal_Status 0;
BA_ "Fehlerwert" SG_ 1011 SCR_Sent_Levelsignal_Status 6;
BA_ "GenSigSendType" SG_ 1507 SCR_02_BZ 0;
BA_ "GenSigFuncType" SG_ 1507 SCR_02_BZ 1;
BA_ "GenSigSwitchedByIgnition" SG_ 1507 SCR_02_BZ 0;
BA_ "GenSigSendType" SG_ 1507 SCR_Guetesensor 0;
BA_ "GenSigStartValue" SG_ 1507 SCR_Guetesensor 1022;
BA_ "GenSigSwitchedByIgnition" SG_ 1507 SCR_Guetesensor 0;
BA_ "Fehlerwert" SG_ 1507 SCR_Guetesensor 1023;
BA_ "GenSigSendType" SG_ 1507 SCR_Heizkreis_3_Strom 0;
BA_ "GenSigStartValue" SG_ 1507 SCR_Heizkreis_3_Strom 254;
BA_ "GenSigSwitchedByIgnition" SG_ 1507 SCR_Heizkreis_3_Strom 0;
BA_ "Fehlerwert" SG_ 1507 SCR_Heizkreis_3_Strom 255;
BA_ "GenSigSendType" SG_ 1507 SCR_Leitungsheizung_Strom 0;
BA_ "GenSigStartValue" SG_ 1507 SCR_Leitungsheizung_Strom 254;
BA_ "GenSigSwitchedByIgnition" SG_ 1507 SCR_Leitungsheizung_Strom 0;
BA_ "Fehlerwert" SG_ 1507 SCR_Leitungsheizung_Strom 255;
BA_ "GenSigSendType" SG_ 1507 SCR_Tankheizung_Strom 0;
BA_ "GenSigStartValue" SG_ 1507 SCR_Tankheizung_Strom 254;
BA_ "GenSigSwitchedByIgnition" SG_ 1507 SCR_Tankheizung_Strom 0;
BA_ "Fehlerwert" SG_ 1507 SCR_Tankheizung_Strom 255;
BA_ "GenSigSendType" SG_ 1507 SCR_Temp_Aktivtank 0;
BA_ "GenSigStartValue" SG_ 1507 SCR_Temp_Aktivtank 254;
BA_ "GenSigSwitchedByIgnition" SG_ 1507 SCR_Temp_Aktivtank 0;
BA_ "Fehlerwert" SG_ 1507 SCR_Temp_Aktivtank 255;
BA_ "GenSigSendType" SG_ 1507 SCR_Temp_Passivtank 0;
BA_ "GenSigStartValue" SG_ 1507 SCR_Temp_Passivtank 254;
BA_ "GenSigSwitchedByIgnition" SG_ 1507 SCR_Temp_Passivtank 0;
BA_ "Fehlerwert" SG_ 1507 SCR_Temp_Passivtank 255;
BA_ "GenSigSendType" SG_ 1507 SCR_Transferpumpe_Strom 0;
BA_ "GenSigStartValue" SG_ 1507 SCR_Transferpumpe_Strom 254;
BA_ "GenSigSwitchedByIgnition" SG_ 1507 SCR_Transferpumpe_Strom 0;
BA_ "Fehlerwert" SG_ 1507 SCR_Transferpumpe_Strom 255;
BA_ "GenSigSendType" SG_ 1508 SCR_03_BZ 0;
BA_ "GenSigFuncType" SG_ 1508 SCR_03_BZ 1;
BA_ "GenSigSwitchedByIgnition" SG_ 1508 SCR_03_BZ 0;
BA_ "GenSigSendType" SG_ 1508 SCR_Dosierpumpe_Status_Spule 3;
BA_ "GenSigSwitchedByIgnition" SG_ 1508 SCR_Dosierpumpe_Status_Spule 0;
BA_ "GenSigSendType" SG_ 1508 SCR_Druck_Status_02 3;
BA_ "GenSigSwitchedByIgnition" SG_ 1508 SCR_Druck_Status_02 0;
BA_ "GenSigSendType" SG_ 1508 SCR_Heizkreis_3_Status 3;
BA_ "GenSigStartValue" SG_ 1508 SCR_Heizkreis_3_Status 15;
BA_ "GenSigSwitchedByIgnition" SG_ 1508 SCR_Heizkreis_3_Status 0;
BA_ "GenSigSendType" SG_ 1508 SCR_Leitungsheizung_Status 3;
BA_ "GenSigStartValue" SG_ 1508 SCR_Leitungsheizung_Status 15;
BA_ "GenSigSwitchedByIgnition" SG_ 1508 SCR_Leitungsheizung_Status 0;
BA_ "GenSigSendType" SG_ 1508 SCR_Level_Aktivtank_Status 3;
BA_ "GenSigStartValue" SG_ 1508 SCR_Level_Aktivtank_Status 15;
BA_ "GenSigSwitchedByIgnition" SG_ 1508 SCR_Level_Aktivtank_Status 0;
BA_ "GenSigSendType" SG_ 1508 SCR_Level_Passivtank_Status 3;
BA_ "GenSigStartValue" SG_ 1508 SCR_Level_Passivtank_Status 15;
BA_ "GenSigSwitchedByIgnition" SG_ 1508 SCR_Level_Passivtank_Status 0;
BA_ "GenSigSendType" SG_ 1508 SCR_Sensorversorgung_12V_Status 3;
BA_ "GenSigStartValue" SG_ 1508 SCR_Sensorversorgung_12V_Status 15;
BA_ "GenSigSwitchedByIgnition" SG_ 1508 SCR_Sensorversorgung_12V_Status 0;
BA_ "GenSigSendType" SG_ 1508 SCR_Spannungsversorgung_Status 3;
BA_ "GenSigStartValue" SG_ 1508 SCR_Spannungsversorgung_Status 15;
BA_ "GenSigSwitchedByIgnition" SG_ 1508 SCR_Spannungsversorgung_Status 0;
BA_ "GenSigSendType" SG_ 1508 SCR_Tankheizung_Status 3;
BA_ "GenSigStartValue" SG_ 1508 SCR_Tankheizung_Status 15;
BA_ "GenSigSwitchedByIgnition" SG_ 1508 SCR_Tankheizung_Status 0;
BA_ "GenSigSendType" SG_ 1508 SCR_Temp_Aktivtank_Status_02 3;
BA_ "GenSigSwitchedByIgnition" SG_ 1508 SCR_Temp_Aktivtank_Status_02 0;
BA_ "GenSigSendType" SG_ 1508 SCR_Temp_Passivtank_Status 3;
BA_ "GenSigStartValue" SG_ 1508 SCR_Temp_Passivtank_Status 15;
BA_ "GenSigSwitchedByIgnition" SG_ 1508 SCR_Temp_Passivtank_Status 0;
BA_ "GenSigSendType" SG_ 1508 SCR_Transferpumpe_Status 3;
BA_ "GenSigSwitchedByIgnition" SG_ 1508 SCR_Transferpumpe_Status 0;
BA_ "GenSigSendType" SG_ 1508 SCR_VersorgungSensoren_Status_02 3;
BA_ "GenSigStartValue" SG_ 1508 SCR_VersorgungSensoren_Status_02 15;
BA_ "GenSigSwitchedByIgnition" SG_ 1508 SCR_VersorgungSensoren_Status_02 0;
BA_ "GenSigSendType" SG_ 1509 SCR_04_BZ 0;
BA_ "GenSigFuncType" SG_ 1509 SCR_04_BZ 1;
BA_ "GenSigSwitchedByIgnition" SG_ 1509 SCR_04_BZ 0;
BA_ "GenSigSendType" SG_ 1509 SCR_Ansteuerung_Dosierpumpe 0;
BA_ "GenSigSwitchedByIgnition" SG_ 1509 SCR_Ansteuerung_Dosierpumpe 0;
BA_ "GenSigSendType" SG_ 1509 SCR_Ansteuerung_Heizkreis_3 0;
BA_ "GenSigSwitchedByIgnition" SG_ 1509 SCR_Ansteuerung_Heizkreis_3 0;
BA_ "GenSigSendType" SG_ 1509 SCR_Ansteuerung_Leitungsheizung 0;
BA_ "GenSigSwitchedByIgnition" SG_ 1509 SCR_Ansteuerung_Leitungsheizung 0;
BA_ "GenSigSendType" SG_ 1509 SCR_Ansteuerung_Tankheizung 0;
BA_ "GenSigSwitchedByIgnition" SG_ 1509 SCR_Ansteuerung_Tankheizung 0;
BA_ "GenSigSendType" SG_ 1509 SCR_Ansteuerung_Transferpumpe 0;
BA_ "GenSigSwitchedByIgnition" SG_ 1509 SCR_Ansteuerung_Transferpumpe 0;
BA_ "GenSigSendType" SG_ 1509 SCR_CAL_CVN_CRC_32 0;
BA_ "GenSigSwitchedByIgnition" SG_ 1509 SCR_CAL_CVN_CRC_32 0;
BA_ "GenSigSendType" SG_ 1509 SCR_Steuergeraet_PMode 0;
BA_ "GenSigSwitchedByIgnition" SG_ 1509 SCR_Steuergeraet_PMode 0;
BA_ "GenSigSendType" SG_ 1526 SCR_05_BZ 0;
BA_ "GenSigFuncType" SG_ 1526 SCR_05_BZ 1;
BA_ "GenSigSwitchedByIgnition" SG_ 1526 SCR_05_BZ 0;
BA_ "GenSigSendType" SG_ 1526 SCR_DEF_Qualitaet_Medium 3;
BA_ "GenSigSwitchedByIgnition" SG_ 1526 SCR_DEF_Qualitaet_Medium 0;
BA_ "GenSigSendType" SG_ 1526 SCR_ECU_Datensatz_Status 3;
BA_ "GenSigStartValue" SG_ 1526 SCR_ECU_Datensatz_Status 3;
BA_ "GenSigSwitchedByIgnition" SG_ 1526 SCR_ECU_Datensatz_Status 0;
BA_ "GenSigSendType" SG_ 1526 SCR_HAL_Sensorik_Status 3;
BA_ "GenSigStartValue" SG_ 1526 SCR_HAL_Sensorik_Status 15;
BA_ "GenSigSwitchedByIgnition" SG_ 1526 SCR_HAL_Sensorik_Status 0;
BA_ "GenSigSendType" SG_ 1526 SCR_Level_Aktivtank_OOR4Quality 3;
BA_ "GenSigSwitchedByIgnition" SG_ 1526 SCR_Level_Aktivtank_OOR4Quality 0;
BA_ "GenSigSendType" SG_ 1526 SCR_Level_Aktivtank_OOR_minus 3;
BA_ "GenSigSwitchedByIgnition" SG_ 1526 SCR_Level_Aktivtank_OOR_minus 0;
BA_ "GenSigSendType" SG_ 1526 SCR_QBit_Qualitaet 0;
BA_ "GenSigStartValue" SG_ 1526 SCR_QBit_Qualitaet 1;
BA_ "GenSigSwitchedByIgnition" SG_ 1526 SCR_QBit_Qualitaet 0;
BA_ "GenSigSendType" SG_ 1526 SCR_Sent_1_elektrischer_Status 3;
BA_ "GenSigStartValue" SG_ 1526 SCR_Sent_1_elektrischer_Status 15;
BA_ "GenSigSwitchedByIgnition" SG_ 1526 SCR_Sent_1_elektrischer_Status 0;
BA_ "GenSigSendType" SG_ 1526 SCR_Sent_1_Signalstatus 3;
BA_ "GenSigStartValue" SG_ 1526 SCR_Sent_1_Signalstatus 3;
BA_ "GenSigSwitchedByIgnition" SG_ 1526 SCR_Sent_1_Signalstatus 0;
BA_ "GenSigSendType" SG_ 1526 SCR_Sent_2_elektrischer_Status 3;
BA_ "GenSigStartValue" SG_ 1526 SCR_Sent_2_elektrischer_Status 15;
BA_ "GenSigSwitchedByIgnition" SG_ 1526 SCR_Sent_2_elektrischer_Status 0;
BA_ "GenSigSendType" SG_ 1526 SCR_Sent_2_Signalstatus 3;
BA_ "GenSigStartValue" SG_ 1526 SCR_Sent_2_Signalstatus 3;
BA_ "GenSigSwitchedByIgnition" SG_ 1526 SCR_Sent_2_Signalstatus 0;
BA_ "GenSigSendType" SG_ 1526 SCR_Sent_Levelsensor 3;
BA_ "GenSigStartValue" SG_ 1526 SCR_Sent_Levelsensor 7;
BA_ "GenSigSwitchedByIgnition" SG_ 1526 SCR_Sent_Levelsensor 0;
BA_ "GenSigSendType" SG_ 1526 SCR_Sent_Qualitaetssensor 3;
BA_ "GenSigStartValue" SG_ 1526 SCR_Sent_Qualitaetssensor 7;
BA_ "GenSigSwitchedByIgnition" SG_ 1526 SCR_Sent_Qualitaetssensor 0;
BA_ "GenSigSendType" SG_ 1526 SCR_Sent_Temperatursensor 3;
BA_ "GenSigStartValue" SG_ 1526 SCR_Sent_Temperatursensor 7;
BA_ "GenSigSwitchedByIgnition" SG_ 1526 SCR_Sent_Temperatursensor 0;
BA_ "GenSigSendType" SG_ 1526 SCR_Steuergeraet_Bus_Status 3;
BA_ "GenSigStartValue" SG_ 1526 SCR_Steuergeraet_Bus_Status 3;
BA_ "GenSigSwitchedByIgnition" SG_ 1526 SCR_Steuergeraet_Bus_Status 0;
BA_ "GenSigSendType" SG_ 1526 SCR_Steuergeraet_Defekt_Status 3;
BA_ "GenSigStartValue" SG_ 1526 SCR_Steuergeraet_Defekt_Status 3;
BA_ "GenSigSwitchedByIgnition" SG_ 1526 SCR_Steuergeraet_Defekt_Status 0;
BA_ "GenSigSendType" SG_ 1526 SCR_Steuergeraet_Heizung_Status 3;
BA_ "GenSigStartValue" SG_ 1526 SCR_Steuergeraet_Heizung_Status 3;
BA_ "GenSigSwitchedByIgnition" SG_ 1526 SCR_Steuergeraet_Heizung_Status 0;
BA_ "GenSigSendType" SG_ 1526 SCR_Steuergeraet_Pumpe_Status 3;
BA_ "GenSigStartValue" SG_ 1526 SCR_Steuergeraet_Pumpe_Status 3;
BA_ "GenSigSwitchedByIgnition" SG_ 1526 SCR_Steuergeraet_Pumpe_Status 0;
BA_ "GenSigSendType" SG_ 1526 SCR_Steuergeraet_Relais_Status 3;
BA_ "GenSigStartValue" SG_ 1526 SCR_Steuergeraet_Relais_Status 3;
BA_ "GenSigSwitchedByIgnition" SG_ 1526 SCR_Steuergeraet_Relais_Status 0;
BA_ "GenSigSendType" SG_ 1526 SCR_Temp_DEF2_Sensor_Status 3;
BA_ "GenSigStartValue" SG_ 1526 SCR_Temp_DEF2_Sensor_Status 7;
BA_ "GenSigSwitchedByIgnition" SG_ 1526 SCR_Temp_DEF2_Sensor_Status 0;
BA_ "GenSigSendType" SG_ 2527679503 SCR_DEF_CAL_CVN_CRC_32 0;
BA_ "GenSigSwitchedByIgnition" SG_ 2527679503 SCR_DEF_CAL_CVN_CRC_32 0;
BA_ "GenSigSendType" SG_ 2527679503 SCR_Level_Aktivtank_saturated 0;
BA_ "GenSigSwitchedByIgnition" SG_ 2527679503 SCR_Level_Aktivtank_saturated 0;
BA_ "GenSigSendType" SG_ 2527679503 SCR_QBit_Qualitaet_Aktivtank 0;
BA_ "GenSigStartValue" SG_ 2527679503 SCR_QBit_Qualitaet_Aktivtank 1;
BA_ "GenSigSwitchedByIgnition" SG_ 2527679503 SCR_QBit_Qualitaet_Aktivtank 0;
BA_ "GenSigSendType" SG_ 2527679503 SCR_QBit_Temp_DEF_Sensor_02 0;
BA_ "GenSigStartValue" SG_ 2527679503 SCR_QBit_Temp_DEF_Sensor_02 1;
BA_ "GenSigSwitchedByIgnition" SG_ 2527679503 SCR_QBit_Temp_DEF_Sensor_02 0;
BA_ "GenSigSendType" SG_ 2527679503 SCR_Sent_Qualitaet_Aktivtank 0;
BA_ "GenSigStartValue" SG_ 2527679503 SCR_Sent_Qualitaet_Aktivtank 254;
BA_ "GenSigSwitchedByIgnition" SG_ 2527679503 SCR_Sent_Qualitaet_Aktivtank 0;
BA_ "GenSigSendType" SG_ 2527679503 SCR_Temp_DEF_Hinweis 0;
BA_ "GenSigStartValue" SG_ 2527679503 SCR_Temp_DEF_Hinweis 3;
BA_ "GenSigSwitchedByIgnition" SG_ 2527679503 SCR_Temp_DEF_Hinweis 0;
BA_ "GenSigSendType" SG_ 2527679503 SCR_Temperatur_DEF_Sensor 0;
BA_ "GenSigSwitchedByIgnition" SG_ 2527679503 SCR_Temperatur_DEF_Sensor 0;
BA_ "GenSigSendType" SG_ 2589283459 SCR_Heizkreis_3_P_effektiv 0;
BA_ "GenSigStartValue" SG_ 2589283459 SCR_Heizkreis_3_P_effektiv 254;
BA_ "GenSigSwitchedByIgnition" SG_ 2589283459 SCR_Heizkreis_3_P_effektiv 0;
BA_ "GenSigSendType" SG_ 2589283459 SCR_Heizkreis_3_P_Grenze 0;
BA_ "GenSigStartValue" SG_ 2589283459 SCR_Heizkreis_3_P_Grenze 254;
BA_ "GenSigSwitchedByIgnition" SG_ 2589283459 SCR_Heizkreis_3_P_Grenze 0;
BA_ "GenSigSendType" SG_ 2589283459 SCR_Tankheizkreis_P_Grenze 0;
BA_ "GenSigStartValue" SG_ 2589283459 SCR_Tankheizkreis_P_Grenze 254;
BA_ "GenSigSwitchedByIgnition" SG_ 2589283459 SCR_Tankheizkreis_P_Grenze 0;
BA_ "GenSigSendType" SG_ 2589283459 SCR_Tankheizung_P_effektiv 0;
BA_ "GenSigStartValue" SG_ 2589283459 SCR_Tankheizung_P_effektiv 254;
BA_ "GenSigSwitchedByIgnition" SG_ 2589283459 SCR_Tankheizung_P_effektiv 0;
BA_ "GenSigSendType" SG_ 2589283460 SCR_DEF2_CAL_CVN_CRC_32 0;
BA_ "GenSigSwitchedByIgnition" SG_ 2589283460 SCR_DEF2_CAL_CVN_CRC_32 0;
BA_ "GenSigSendType" SG_ 2589283460 SCR_QBit_Temp_DEF2_Sensor 0;
BA_ "GenSigStartValue" SG_ 2589283460 SCR_QBit_Temp_DEF2_Sensor 1;
BA_ "GenSigSwitchedByIgnition" SG_ 2589283460 SCR_QBit_Temp_DEF2_Sensor 0;
BA_ "GenSigSendType" SG_ 2589283460 SCR_Temp_DEF2_Sensor 0;
BA_ "GenSigStartValue" SG_ 2589283460 SCR_Temp_DEF2_Sensor 254;
BA_ "GenSigSwitchedByIgnition" SG_ 2589283460 SCR_Temp_DEF2_Sensor 0;
BA_ "GenSigSendType" SG_ 2463978593 SCR_Dosierpumpe_Umdrehungen 0;
BA_ "GenSigStartValue" SG_ 2463978593 SCR_Dosierpumpe_Umdrehungen 254;
BA_ "GenSigSwitchedByIgnition" SG_ 2463978593 SCR_Dosierpumpe_Umdrehungen 0;
BA_ "Fehlerwert" SG_ 2463978593 SCR_Dosierpumpe_Umdrehungen 255;
BA_ "GenSigSendType" SG_ 2463978593 SCR_QBit_Level_kurz_Aktivtank 0;
BA_ "GenSigStartValue" SG_ 2463978593 SCR_QBit_Level_kurz_Aktivtank 1;
BA_ "GenSigSwitchedByIgnition" SG_ 2463978593 SCR_QBit_Level_kurz_Aktivtank 0;
BA_ "GenSigSendType" SG_ 2463978593 SCR_Sent_Level_kurz_Aktivtank 0;
BA_ "GenSigStartValue" SG_ 2463978593 SCR_Sent_Level_kurz_Aktivtank 1022;
BA_ "GenSigSwitchedByIgnition" SG_ 2463978593 SCR_Sent_Level_kurz_Aktivtank 0;
BA_ "GenSigSendType" SG_ 1510 SCR_CAL_ID_Index_01 0;
BA_ "GenSigStartValue" SG_ 1510 SCR_CAL_ID_Index_01 83;
BA_ "GenSigSwitchedByIgnition" SG_ 1510 SCR_CAL_ID_Index_01 0;
BA_ "GenSigSendType" SG_ 1510 SCR_CAL_ID_Index_02 0;
BA_ "GenSigStartValue" SG_ 1510 SCR_CAL_ID_Index_02 67;
BA_ "GenSigSwitchedByIgnition" SG_ 1510 SCR_CAL_ID_Index_02 0;
BA_ "GenSigSendType" SG_ 1510 SCR_CAL_ID_Index_03 0;
BA_ "GenSigStartValue" SG_ 1510 SCR_CAL_ID_Index_03 82;
BA_ "GenSigSwitchedByIgnition" SG_ 1510 SCR_CAL_ID_Index_03 0;
BA_ "GenSigSendType" SG_ 1510 SCR_CAL_ID_Index_04 0;
BA_ "GenSigStartValue" SG_ 1510 SCR_CAL_ID_Index_04 48;
BA_ "GenSigSwitchedByIgnition" SG_ 1510 SCR_CAL_ID_Index_04 0;
BA_ "GenSigSendType" SG_ 1510 SCR_CAL_ID_Index_05 0;
BA_ "GenSigStartValue" SG_ 1510 SCR_CAL_ID_Index_05 48;
BA_ "GenSigSwitchedByIgnition" SG_ 1510 SCR_CAL_ID_Index_05 0;
BA_ "GenSigSendType" SG_ 1510 SCR_CAL_ID_Index_06 0;
BA_ "GenSigStartValue" SG_ 1510 SCR_CAL_ID_Index_06 48;
BA_ "GenSigSwitchedByIgnition" SG_ 1510 SCR_CAL_ID_Index_06 0;
BA_ "GenSigSendType" SG_ 1510 SCR_CAL_ID_Index_07 0;
BA_ "GenSigStartValue" SG_ 1510 SCR_CAL_ID_Index_07 48;
BA_ "GenSigSwitchedByIgnition" SG_ 1510 SCR_CAL_ID_Index_07 0;
BA_ "GenSigSendType" SG_ 1510 SCR_CAL_ID_Index_08 0;
BA_ "GenSigStartValue" SG_ 1510 SCR_CAL_ID_Index_08 48;
BA_ "GenSigSwitchedByIgnition" SG_ 1510 SCR_CAL_ID_Index_08 0;
BA_ "GenSigSendType" SG_ 1512 SCR_CAL_ID_Index_09 0;
BA_ "GenSigStartValue" SG_ 1512 SCR_CAL_ID_Index_09 48;
BA_ "GenSigSwitchedByIgnition" SG_ 1512 SCR_CAL_ID_Index_09 0;
BA_ "GenSigSendType" SG_ 1512 SCR_CAL_ID_Index_10 0;
BA_ "GenSigStartValue" SG_ 1512 SCR_CAL_ID_Index_10 48;
BA_ "GenSigSwitchedByIgnition" SG_ 1512 SCR_CAL_ID_Index_10 0;
BA_ "GenSigSendType" SG_ 1512 SCR_CAL_ID_Index_11 0;
BA_ "GenSigStartValue" SG_ 1512 SCR_CAL_ID_Index_11 48;
BA_ "GenSigSwitchedByIgnition" SG_ 1512 SCR_CAL_ID_Index_11 0;
BA_ "GenSigSendType" SG_ 1512 SCR_CAL_ID_Index_12 0;
BA_ "GenSigStartValue" SG_ 1512 SCR_CAL_ID_Index_12 48;
BA_ "GenSigSwitchedByIgnition" SG_ 1512 SCR_CAL_ID_Index_12 0;
BA_ "GenSigSendType" SG_ 1512 SCR_CAL_ID_Index_13 0;
BA_ "GenSigStartValue" SG_ 1512 SCR_CAL_ID_Index_13 48;
BA_ "GenSigSwitchedByIgnition" SG_ 1512 SCR_CAL_ID_Index_13 0;
BA_ "GenSigSendType" SG_ 1512 SCR_CAL_ID_Index_14 0;
BA_ "GenSigStartValue" SG_ 1512 SCR_CAL_ID_Index_14 48;
BA_ "GenSigSwitchedByIgnition" SG_ 1512 SCR_CAL_ID_Index_14 0;
BA_ "GenSigSendType" SG_ 1512 SCR_CAL_ID_Index_15 0;
BA_ "GenSigStartValue" SG_ 1512 SCR_CAL_ID_Index_15 48;
BA_ "GenSigSwitchedByIgnition" SG_ 1512 SCR_CAL_ID_Index_15 0;
BA_ "GenSigSendType" SG_ 1512 SCR_CAL_ID_Index_16 0;
BA_ "GenSigStartValue" SG_ 1512 SCR_CAL_ID_Index_16 48;
BA_ "GenSigSwitchedByIgnition" SG_ 1512 SCR_CAL_ID_Index_16 0;
BA_ "GenSigSendType" SG_ 2589283497 SCR_DEF2_CAL_ID_Index01 0;
BA_ "GenSigStartValue" SG_ 2589283497 SCR_DEF2_CAL_ID_Index01 1145390640;
BA_ "GenSigSwitchedByIgnition" SG_ 2589283497 SCR_DEF2_CAL_ID_Index01 0;
BA_ "GenSigSendType" SG_ 2589283497 SCR_DEF2_CAL_ID_Index02 0;
BA_ "GenSigStartValue" SG_ 2589283497 SCR_DEF2_CAL_ID_Index02 808464432;
BA_ "GenSigSwitchedByIgnition" SG_ 2589283497 SCR_DEF2_CAL_ID_Index02 0;
BA_ "GenSigSendType" SG_ 2589283498 SCR_DEF2_CAL_ID_Index03 0;
BA_ "GenSigStartValue" SG_ 2589283498 SCR_DEF2_CAL_ID_Index03 808464432;
BA_ "GenSigSwitchedByIgnition" SG_ 2589283498 SCR_DEF2_CAL_ID_Index03 0;
BA_ "GenSigSendType" SG_ 2589283498 SCR_DEF2_CAL_ID_Index04 0;
BA_ "GenSigStartValue" SG_ 2589283498 SCR_DEF2_CAL_ID_Index04 808464432;
BA_ "GenSigSwitchedByIgnition" SG_ 2589283498 SCR_DEF2_CAL_ID_Index04 0;
BA_ "GenSigSendType" SG_ 2589283413 SCR_DEF_CAL_ID_Index01 0;
BA_ "GenSigStartValue" SG_ 2589283413 SCR_DEF_CAL_ID_Index01 1145390640;
BA_ "GenSigSwitchedByIgnition" SG_ 2589283413 SCR_DEF_CAL_ID_Index01 0;
BA_ "GenSigSendType" SG_ 2589283413 SCR_DEF_CAL_ID_Index02 0;
BA_ "GenSigStartValue" SG_ 2589283413 SCR_DEF_CAL_ID_Index02 808464432;
BA_ "GenSigSwitchedByIgnition" SG_ 2589283413 SCR_DEF_CAL_ID_Index02 0;
BA_ "GenSigSendType" SG_ 2589283414 SCR_DEF_CAL_ID_Index03 0;
BA_ "GenSigStartValue" SG_ 2589283414 SCR_DEF_CAL_ID_Index03 808464432;
BA_ "GenSigSwitchedByIgnition" SG_ 2589283414 SCR_DEF_CAL_ID_Index03 0;
BA_ "GenSigSendType" SG_ 2589283414 SCR_DEF_CAL_ID_Index04 0;
BA_ "GenSigStartValue" SG_ 2589283414 SCR_DEF_CAL_ID_Index04 808464432;
BA_ "GenSigSwitchedByIgnition" SG_ 2589283414 SCR_DEF_CAL_ID_Index04 0;
BA_ "GenSigSendType" SG_ 980 BH_Blinker_Fehler 3;
BA_ "GenSigSwitchedByIgnition" SG_ 980 BH_Blinker_Fehler 0;
BA_ "Fehlerwert" SG_ 980 BH_Blinker_Fehler 1;
BA_ "GenSigActiveRepetitions" SG_ 980 BH_Blinker_li 5;
BA_ "GenSigSendType" SG_ 980 BH_Blinker_li 4;
BA_ "GenSigSwitchedByIgnition" SG_ 980 BH_Blinker_li 0;
BA_ "GenSigActiveRepetitions" SG_ 980 BH_Blinker_re 5;
BA_ "GenSigSendType" SG_ 980 BH_Blinker_re 4;
BA_ "GenSigSwitchedByIgnition" SG_ 980 BH_Blinker_re 0;
BA_ "GenSigSendType" SG_ 980 BH_Fernlicht 3;
BA_ "GenSigSwitchedByIgnition" SG_ 980 BH_Fernlicht 0;
BA_ "GenSigActiveRepetitions" SG_ 980 BH_Lichthupe 5;
BA_ "GenSigSendType" SG_ 980 BH_Lichthupe 4;
BA_ "GenSigSwitchedByIgnition" SG_ 980 BH_Lichthupe 0;
BA_ "GenSigSendType" SG_ 980 FAS_Taster 3;
BA_ "GenSigSwitchedByIgnition" SG_ 980 FAS_Taster 0;
BA_ "GenSigSendType" SG_ 980 FAS_Taster_Fehler 3;
BA_ "GenSigSwitchedByIgnition" SG_ 980 FAS_Taster_Fehler 0;
BA_ "Fehlerwert" SG_ 980 FAS_Taster_Fehler 1;
BA_ "GenSigSendType" SG_ 980 LRH_aktiv 3;
BA_ "GenSigSwitchedByIgnition" SG_ 980 LRH_aktiv 0;
BA_ "GenSigSendType" SG_ 980 LRH_On_Off 3;
BA_ "GenSigSwitchedByIgnition" SG_ 980 LRH_On_Off 0;
BA_ "Fehlerwert" SG_ 980 LRH_On_Off 3;
BA_ "GenSigSendType" SG_ 980 SMLS_01_BZ 0;
BA_ "GenSigFuncType" SG_ 980 SMLS_01_BZ 1;
BA_ "GenSigSwitchedByIgnition" SG_ 980 SMLS_01_BZ 0;
BA_ "GenSigSendType" SG_ 980 SMLS_01_CRC 0;
BA_ "GenSigFuncType" SG_ 980 SMLS_01_CRC 2;
BA_ "GenSigSwitchedByIgnition" SG_ 980 SMLS_01_CRC 0;
BA_ "GenSigActiveRepetitions" SG_ 980 SMLS_Hupe 5;
BA_ "GenSigSendType" SG_ 980 SMLS_Hupe 4;
BA_ "GenSigSwitchedByIgnition" SG_ 980 SMLS_Hupe 0;
BA_ "GenSigSendType" SG_ 980 SMLS_P_verriegelt_plausibel 3;
BA_ "GenSigSwitchedByIgnition" SG_ 980 SMLS_P_verriegelt_plausibel 0;
BA_ "GenSigActiveRepetitions" SG_ 980 SMLS_PTT 5;
BA_ "GenSigSendType" SG_ 980 SMLS_PTT 4;
BA_ "GenSigSendType" SG_ 980 WH_Frontwaschen 3;
BA_ "GenSigSwitchedByIgnition" SG_ 980 WH_Frontwaschen 0;
BA_ "GenSigSendType" SG_ 980 WH_Heckintervall 3;
BA_ "GenSigSwitchedByIgnition" SG_ 980 WH_Heckintervall 0;
BA_ "GenSigSendType" SG_ 980 WH_Heckwaschen 3;
BA_ "GenSigSwitchedByIgnition" SG_ 980 WH_Heckwaschen 0;
BA_ "GenSigSendType" SG_ 980 WH_Intervall 3;
BA_ "GenSigSwitchedByIgnition" SG_ 980 WH_Intervall 0;
BA_ "GenSigSendType" SG_ 980 WH_Intervallstufen 3;
BA_ "GenSigSwitchedByIgnition" SG_ 980 WH_Intervallstufen 0;
BA_ "Fehlerwert" SG_ 980 WH_Intervallstufen 15;
BA_ "GenSigMissingSourceValue" SG_ 980 WH_Intervallstufen 15;
BA_ "GenSigActiveRepetitions" SG_ 980 WH_SRA 5;
BA_ "GenSigSendType" SG_ 980 WH_SRA 4;
BA_ "GenSigSwitchedByIgnition" SG_ 980 WH_SRA 0;
BA_ "GenSigActiveRepetitions" SG_ 980 WH_Tipwischen 5;
BA_ "GenSigSendType" SG_ 980 WH_Tipwischen 4;
BA_ "GenSigSwitchedByIgnition" SG_ 980 WH_Tipwischen 0;
BA_ "GenSigActiveRepetitions" SG_ 980 WH_Tipwischen_lang 5;
BA_ "GenSigSendType" SG_ 980 WH_Tipwischen_lang 4;
BA_ "GenSigSwitchedByIgnition" SG_ 980 WH_Tipwischen_lang 0;
BA_ "GenSigSendType" SG_ 980 WH_Wischer_Fehler 3;
BA_ "GenSigSwitchedByIgnition" SG_ 980 WH_Wischer_Fehler 0;
BA_ "Fehlerwert" SG_ 980 WH_Wischer_Fehler 1;
BA_ "GenSigSendType" SG_ 980 WH_WischerStufe1 3;
BA_ "GenSigSwitchedByIgnition" SG_ 980 WH_WischerStufe1 0;
BA_ "GenSigSendType" SG_ 980 WH_WischerStufe2 3;
BA_ "GenSigSwitchedByIgnition" SG_ 980 WH_WischerStufe2 0;
BA_ "GenSigActiveRepetitions" SG_ 1710 SP_abklappen 5;
BA_ "GenSigSendType" SG_ 1710 SP_abklappen 4;
BA_ "GenSigSwitchedByIgnition" SG_ 1710 SP_abklappen 0;
BA_ "GenSigActiveRepetitions" SG_ 1710 SP_anklappen 5;
BA_ "GenSigSendType" SG_ 1710 SP_anklappen 4;
BA_ "GenSigSwitchedByIgnition" SG_ 1710 SP_anklappen 0;
BA_ "GenSigSendType" SG_ 1710 SP_ARA_Status 0;
BA_ "GenSigActiveRepetitions" SG_ 1710 SP_Auswahl_li 5;
BA_ "GenSigSendType" SG_ 1710 SP_Auswahl_li 4;
BA_ "GenSigSwitchedByIgnition" SG_ 1710 SP_Auswahl_li 0;
BA_ "GenSigActiveRepetitions" SG_ 1710 SP_Auswahl_re 5;
BA_ "GenSigSendType" SG_ 1710 SP_Auswahl_re 4;
BA_ "GenSigSwitchedByIgnition" SG_ 1710 SP_Auswahl_re 0;
BA_ "GenSigActiveRepetitions" SG_ 1710 SP_BT_links 5;
BA_ "GenSigSendType" SG_ 1710 SP_BT_links 4;
BA_ "GenSigSwitchedByIgnition" SG_ 1710 SP_BT_links 0;
BA_ "GenSigActiveRepetitions" SG_ 1710 SP_BT_oben 5;
BA_ "GenSigSendType" SG_ 1710 SP_BT_oben 4;
BA_ "GenSigSwitchedByIgnition" SG_ 1710 SP_BT_oben 0;
BA_ "GenSigActiveRepetitions" SG_ 1710 SP_BT_rechts 5;
BA_ "GenSigSendType" SG_ 1710 SP_BT_rechts 4;
BA_ "GenSigSwitchedByIgnition" SG_ 1710 SP_BT_rechts 0;
BA_ "GenSigActiveRepetitions" SG_ 1710 SP_BT_unten 5;
BA_ "GenSigSendType" SG_ 1710 SP_BT_unten 4;
BA_ "GenSigSwitchedByIgnition" SG_ 1710 SP_BT_unten 0;
BA_ "GenSigActiveRepetitions" SG_ 1710 SP_FT_links 5;
BA_ "GenSigSendType" SG_ 1710 SP_FT_links 4;
BA_ "GenSigSwitchedByIgnition" SG_ 1710 SP_FT_links 0;
BA_ "GenSigActiveRepetitions" SG_ 1710 SP_FT_oben 5;
BA_ "GenSigSendType" SG_ 1710 SP_FT_oben 4;
BA_ "GenSigSwitchedByIgnition" SG_ 1710 SP_FT_oben 0;
BA_ "GenSigActiveRepetitions" SG_ 1710 SP_FT_rechts 5;
BA_ "GenSigSendType" SG_ 1710 SP_FT_rechts 4;
BA_ "GenSigSwitchedByIgnition" SG_ 1710 SP_FT_rechts 0;
BA_ "GenSigActiveRepetitions" SG_ 1710 SP_FT_unten 5;
BA_ "GenSigSendType" SG_ 1710 SP_FT_unten 4;
BA_ "GenSigSwitchedByIgnition" SG_ 1710 SP_FT_unten 0;
BA_ "GenSigSendType" SG_ 1710 SP_Hzg_Taster 3;
BA_ "GenSigSwitchedByIgnition" SG_ 1710 SP_Hzg_Taster 0;
BA_ "GenSigActiveRepetitions" SG_ 1710 SP_normieren 5;
BA_ "GenSigSendType" SG_ 1710 SP_normieren 4;
BA_ "GenSigSwitchedByIgnition" SG_ 1710 SP_normieren 0;
BA_ "GenSigActiveRepetitions" SG_ 1710 SP_S_Klappen 5;
BA_ "GenSigSendType" SG_ 1710 SP_S_Klappen 4;
BA_ "GenSigSwitchedByIgnition" SG_ 1710 SP_S_Klappen 0;
BA_ "GenSigActiveRepetitions" SG_ 1710 SP_S_links 5;
BA_ "GenSigSendType" SG_ 1710 SP_S_links 4;
BA_ "GenSigSwitchedByIgnition" SG_ 1710 SP_S_links 0;
BA_ "GenSigActiveRepetitions" SG_ 1710 SP_S_oben 5;
BA_ "GenSigSendType" SG_ 1710 SP_S_oben 4;
BA_ "GenSigSwitchedByIgnition" SG_ 1710 SP_S_oben 0;
BA_ "GenSigActiveRepetitions" SG_ 1710 SP_S_rechts 5;
BA_ "GenSigSendType" SG_ 1710 SP_S_rechts 4;
BA_ "GenSigSwitchedByIgnition" SG_ 1710 SP_S_rechts 0;
BA_ "GenSigActiveRepetitions" SG_ 1710 SP_S_unten 5;
BA_ "GenSigSendType" SG_ 1710 SP_S_unten 4;
BA_ "GenSigSwitchedByIgnition" SG_ 1710 SP_S_unten 0;
BA_ "GenSigSendType" SG_ 1710 SP_Verstellschalter_Fehler 0;
BA_ "Fehlerwert" SG_ 1710 SP_Verstellschalter_Fehler 1;
BA_ "GenSigSendType" SG_ 1313 STH_EKP_Anst 0;
BA_ "GenSigSwitchedByIgnition" SG_ 1313 STH_EKP_Anst 0;
BA_ "GenSigSendType" SG_ 1313 STH_Fehler_ElWaPu 0;
BA_ "GenSigSwitchedByIgnition" SG_ 1313 STH_Fehler_ElWaPu 0;
BA_ "Fehlerwert" SG_ 1313 STH_Fehler_ElWaPu 1;
BA_ "GenSigSendType" SG_ 1313 STH_Fehlerstatus 0;
BA_ "GenSigSwitchedByIgnition" SG_ 1313 STH_Fehlerstatus 0;
BA_ "GenSigSendType" SG_ 1313 STH_Funk_aus 0;
BA_ "GenSigSwitchedByIgnition" SG_ 1313 STH_Funk_aus 0;
BA_ "GenSigSendType" SG_ 1313 STH_Funk_ein 0;
BA_ "GenSigSwitchedByIgnition" SG_ 1313 STH_Funk_ein 0;
BA_ "GenSigSendType" SG_ 1313 STH_Geblaese 0;
BA_ "GenSigSwitchedByIgnition" SG_ 1313 STH_Geblaese 0;
BA_ "GenSigSendType" SG_ 1313 STH_Heizleistung 0;
BA_ "GenSigSwitchedByIgnition" SG_ 1313 STH_Heizleistung 0;
BA_ "GenSigSendType" SG_ 1313 STH_KL_HUP 0;
BA_ "GenSigSwitchedByIgnition" SG_ 1313 STH_KL_HUP 0;
BA_ "GenSigSendType" SG_ 1313 STH_KVS 0;
BA_ "GenSigSwitchedByIgnition" SG_ 1313 STH_KVS 0;
BA_ "GenSigSendType" SG_ 1313 STH_KVS_Ueberlauf 0;
BA_ "GenSigSwitchedByIgnition" SG_ 1313 STH_KVS_Ueberlauf 0;
BA_ "GenSigSendType" SG_ 1313 STH_LED 0;
BA_ "GenSigSwitchedByIgnition" SG_ 1313 STH_LED 0;
BA_ "GenSigSendType" SG_ 1313 STH_Motorvorwaermung 0;
BA_ "GenSigSwitchedByIgnition" SG_ 1313 STH_Motorvorwaermung 0;
BA_ "GenSigSendType" SG_ 1313 STH_Pumpe_ein 0;
BA_ "GenSigSwitchedByIgnition" SG_ 1313 STH_Pumpe_ein 0;
BA_ "GenSigSendType" SG_ 1313 STH_Pumpen_Anf_extern 0;
BA_ "GenSigSwitchedByIgnition" SG_ 1313 STH_Pumpen_Anf_extern 0;
BA_ "GenSigSendType" SG_ 1313 STH_Servicemode 0;
BA_ "GenSigSwitchedByIgnition" SG_ 1313 STH_Servicemode 0;
BA_ "GenSigSendType" SG_ 1313 STH_SH_ZH 0;
BA_ "GenSigSwitchedByIgnition" SG_ 1313 STH_SH_ZH 0;
BA_ "GenSigSendType" SG_ 1313 STH_Start_folgt 0;
BA_ "GenSigSwitchedByIgnition" SG_ 1313 STH_Start_folgt 0;
BA_ "GenSigSendType" SG_ 1313 STH_Texte 0;
BA_ "GenSigSwitchedByIgnition" SG_ 1313 STH_Texte 0;
BA_ "GenSigSendType" SG_ 1313 STH_Ventil_Status 0;
BA_ "GenSigSwitchedByIgnition" SG_ 1313 STH_Ventil_Status 0;
BA_ "GenSigSendType" SG_ 1313 STH_Ventiloeffnungszeit 0;
BA_ "GenSigSwitchedByIgnition" SG_ 1313 STH_Ventiloeffnungszeit 0;
BA_ "GenSigSendType" SG_ 1313 STH_Waermeeintrag 0;
BA_ "GenSigSwitchedByIgnition" SG_ 1313 STH_Waermeeintrag 0;
BA_ "GenSigSendType" SG_ 1313 STH_war_aktiv 0;
BA_ "GenSigSwitchedByIgnition" SG_ 1313 STH_war_aktiv 0;
BA_ "GenSigSendType" SG_ 1313 STH_Wassertemp 0;
BA_ "GenSigStartValue" SG_ 1313 STH_Wassertemp 254;
BA_ "GenSigSwitchedByIgnition" SG_ 1313 STH_Wassertemp 0;
BA_ "Fehlerwert" SG_ 1313 STH_Wassertemp 255;
BA_ "GenSigSendType" SG_ 1313 STH_Zusatzheizung 0;
BA_ "GenSigSwitchedByIgnition" SG_ 1313 STH_Zusatzheizung 0;
BA_ "GenSigSendType" SG_ 1650 STH_ZZ_Betriebsdauer 3;
BA_ "GenSigSwitchedByIgnition" SG_ 1650 STH_ZZ_Betriebsdauer 0;
BA_ "GenSigSendType" SG_ 1650 STH_ZZ_Betriebsmodus 3;
BA_ "GenSigSwitchedByIgnition" SG_ 1650 STH_ZZ_Betriebsmodus 0;
BA_ "GenSigSendType" SG_ 1650 STH_ZZ_Minute 3;
BA_ "GenSigSwitchedByIgnition" SG_ 1650 STH_ZZ_Minute 0;
BA_ "GenSigSendType" SG_ 1650 STH_ZZ_Monat 3;
BA_ "GenSigSwitchedByIgnition" SG_ 1650 STH_ZZ_Monat 0;
BA_ "GenSigSendType" SG_ 1650 STH_ZZ_Status_Timer 3;
BA_ "GenSigSwitchedByIgnition" SG_ 1650 STH_ZZ_Status_Timer 0;
BA_ "GenSigSendType" SG_ 1650 STH_ZZ_Stunde 3;
BA_ "GenSigSwitchedByIgnition" SG_ 1650 STH_ZZ_Stunde 0;
BA_ "GenSigSendType" SG_ 1650 STH_ZZ_Tag 3;
BA_ "GenSigSwitchedByIgnition" SG_ 1650 STH_ZZ_Tag 0;
BA_ "GenSigSendType" SG_ 505 ACA_HF_Grund_AV_AB 0;
BA_ "GenSigSendType" SG_ 505 ACA_HF_Status 0;
BA_ "GenSigStartValue" SG_ 505 ACA_HF_Status 1;
BA_ "GenSigSendType" SG_ 505 ACA_QF_Fahreruebernahme 0;
BA_ "GenSigSendType" SG_ 505 ACA_QF_Status_Anzeige 0;
BA_ "GenSigSendType" SG_ 505 ACF_Spurwechsel_moeglich 0;
BA_ "GenSigSendType" SG_ 505 ACF_Spurwechsel_wahrscheinlich 0;
BA_ "GenSigSendType" SG_ 505 ACF_SwuFahrerUnaufmerksam 0;
BA_ "GenSigSwitchedByIgnition" SG_ 505 ACF_SwuFahrerUnaufmerksam 0;
BA_ "GenSigSendType" SG_ 505 FZE_Spurwechsel_erkannt_li 0;
BA_ "GenSigSendType" SG_ 505 FZE_Spurwechsel_erkannt_re 0;
BA_ "GenSigSendType" SG_ 505 FZE_STP_Abschaltbedingung 0;
BA_ "GenSigStartValue" SG_ 505 FZE_STP_Abschaltbedingung 1;
BA_ "GenSigSendType" SG_ 505 FZE_STP_Aktivierverhinderung 0;
BA_ "GenSigSwitchedByIgnition" SG_ 505 FZE_STP_Aktivierverhinderung 0;
BA_ "GenSigSendType" SG_ 505 FZE_STP_Status 0;
BA_ "GenSigSendType" SG_ 505 STP_03_BZ 0;
BA_ "GenSigFuncType" SG_ 505 STP_03_BZ 1;
BA_ "GenSigSendType" SG_ 505 STP_03_CRC 0;
BA_ "GenSigFuncType" SG_ 505 STP_03_CRC 2;
BA_ "GenSigSendType" SG_ 505 STP_Funktion_freigegeben 0;
BA_ "GenSigSendType" SG_ 505 STP_Notlaufaktivierung 0;
BA_ "GenSigSendType" SG_ 505 STP_Slave_Status 0;
BA_ "GenSigSendType" SG_ 783 ASW_Kombitexte 0;
BA_ "GenSigSwitchedByIgnition" SG_ 783 ASW_Kombitexte 0;
BA_ "GenSigSendType" SG_ 783 ASW_Modus 0;
BA_ "GenSigStartValue" SG_ 783 ASW_Modus 4;
BA_ "GenSigSendType" SG_ 783 ASW_Status 0;
BA_ "GenSigSwitchedByIgnition" SG_ 783 ASW_Status 0;
BA_ "Fehlerwert" SG_ 783 ASW_Status 2;
BA_ "GenSigSendType" SG_ 783 ASW_Warnung_BFS 0;
BA_ "GenSigSwitchedByIgnition" SG_ 783 ASW_Warnung_BFS 0;
BA_ "GenSigSendType" SG_ 783 ASW_Warnung_FS 0;
BA_ "GenSigSwitchedByIgnition" SG_ 783 ASW_Warnung_FS 0;
BA_ "GenSigSendType" SG_ 783 Heckradar_Kombitexte 0;
BA_ "GenSigSwitchedByIgnition" SG_ 783 Heckradar_Kombitexte 0;
BA_ "GenSigSendType" SG_ 783 HRE_Anzeigetexte 0;
BA_ "GenSigSwitchedByIgnition" SG_ 783 HRE_Anzeigetexte 0;
BA_ "GenSigSendType" SG_ 783 RCTA_Kombitexte 0;
BA_ "GenSigSwitchedByIgnition" SG_ 783 RCTA_Kombitexte 0;
BA_ "GenSigSendType" SG_ 783 SWA_01_BZ 0;
BA_ "GenSigFuncType" SG_ 783 SWA_01_BZ 1;
BA_ "GenSigSwitchedByIgnition" SG_ 783 SWA_01_BZ 0;
BA_ "GenSigSendType" SG_ 783 SWA_01_CRC 0;
BA_ "GenSigFuncType" SG_ 783 SWA_01_CRC 2;
BA_ "GenSigSwitchedByIgnition" SG_ 783 SWA_01_CRC 0;
BA_ "GenSigSendType" SG_ 783 SWA_Anzeigen 0;
BA_ "GenSigSwitchedByIgnition" SG_ 783 SWA_Anzeigen 0;
BA_ "GenSigSendType" SG_ 783 SWA_Blindheit_erkannt 0;
BA_ "GenSigSendType" SG_ 783 SWA_FT_RueckLED 0;
BA_ "GenSigSwitchedByIgnition" SG_ 783 SWA_FT_RueckLED 0;
BA_ "GenSigSendType" SG_ 783 SWA_Infostufe_SWA_li 0;
BA_ "GenSigSendType" SG_ 783 SWA_Infostufe_SWA_re 0;
BA_ "GenSigSendType" SG_ 783 SWA_Kolonne_li 0;
BA_ "GenSigSendType" SG_ 783 SWA_Kolonne_mi 0;
BA_ "GenSigSendType" SG_ 783 SWA_Kolonne_re 0;
BA_ "GenSigSendType" SG_ 783 SWA_Modus 0;
BA_ "GenSigSendType" SG_ 783 SWA_rel_Fehler 0;
BA_ "Fehlerwert" SG_ 783 SWA_rel_Fehler 1;
BA_ "GenSigSendType" SG_ 783 SWA_rel_Nichtverf 0;
BA_ "GenSigSendType" SG_ 783 SWA_Sta_aktiv 0;
BA_ "GenSigSendType" SG_ 783 SWA_Sta_passiv 0;
BA_ "GenSigSendType" SG_ 783 SWA_Standziele_li 0;
BA_ "GenSigSendType" SG_ 783 SWA_Standziele_re 0;
BA_ "GenSigSendType" SG_ 783 SWA_Status_02 0;
BA_ "Fehlerwert" SG_ 783 SWA_Status_02 3;
BA_ "GenSigSendType" SG_ 783 SWA_Warnung_SWA_li 0;
BA_ "GenSigSendType" SG_ 783 SWA_Warnung_SWA_re 0;
BA_ "GenSigSendType" SG_ 673 SWA_LED_Hell_BFS 3;
BA_ "GenSigStartValue" SG_ 673 SWA_LED_Hell_BFS 126;
BA_ "Fehlerwert" SG_ 673 SWA_LED_Hell_BFS 127;
BA_ "GenSigSendType" SG_ 673 SWA_LED_Hell_FS 3;
BA_ "GenSigStartValue" SG_ 673 SWA_LED_Hell_FS 126;
BA_ "Fehlerwert" SG_ 673 SWA_LED_Hell_FS 127;
BA_ "GenSigSendType" SG_ 673 SWA_LED_Modus_BFS 3;
BA_ "GenSigSendType" SG_ 673 SWA_LED_Modus_FS 3;
BA_ "GenSigSendType" SG_ 1413 GW_KD_Fehler 3;
BA_ "GenSigSendType" SG_ 1413 SI_BUS_01 3;
BA_ "GenSigStartValue" SG_ 1413 SI_BUS_01 1;
BA_ "GenSigSwitchedByIgnition" SG_ 1413 SI_BUS_01 0;
BA_ "GenSigSendType" SG_ 1413 SI_BUS_02 3;
BA_ "GenSigStartValue" SG_ 1413 SI_BUS_02 1;
BA_ "GenSigSwitchedByIgnition" SG_ 1413 SI_BUS_02 0;
BA_ "GenSigSendType" SG_ 1413 SI_BUS_03 3;
BA_ "GenSigStartValue" SG_ 1413 SI_BUS_03 1;
BA_ "GenSigSwitchedByIgnition" SG_ 1413 SI_BUS_03 0;
BA_ "GenSigSendType" SG_ 1413 SI_BUS_04 3;
BA_ "GenSigStartValue" SG_ 1413 SI_BUS_04 1;
BA_ "GenSigSwitchedByIgnition" SG_ 1413 SI_BUS_04 0;
BA_ "GenSigSendType" SG_ 1413 SI_BUS_05 3;
BA_ "GenSigStartValue" SG_ 1413 SI_BUS_05 1;
BA_ "GenSigSwitchedByIgnition" SG_ 1413 SI_BUS_05 0;
BA_ "GenSigSendType" SG_ 1413 SI_BUS_06 3;
BA_ "GenSigStartValue" SG_ 1413 SI_BUS_06 1;
BA_ "GenSigSwitchedByIgnition" SG_ 1413 SI_BUS_06 0;
BA_ "GenSigSendType" SG_ 1413 SI_BUS_07 3;
BA_ "GenSigStartValue" SG_ 1413 SI_BUS_07 1;
BA_ "GenSigSwitchedByIgnition" SG_ 1413 SI_BUS_07 0;
BA_ "GenSigSendType" SG_ 1413 SI_BUS_08 3;
BA_ "GenSigStartValue" SG_ 1413 SI_BUS_08 1;
BA_ "GenSigSwitchedByIgnition" SG_ 1413 SI_BUS_08 0;
BA_ "GenSigSendType" SG_ 1413 SI_BUS_09 3;
BA_ "GenSigStartValue" SG_ 1413 SI_BUS_09 1;
BA_ "GenSigSwitchedByIgnition" SG_ 1413 SI_BUS_09 0;
BA_ "GenSigSendType" SG_ 1413 SI_BUS_10 3;
BA_ "GenSigStartValue" SG_ 1413 SI_BUS_10 1;
BA_ "GenSigSwitchedByIgnition" SG_ 1413 SI_BUS_10 0;
BA_ "GenSigSendType" SG_ 1413 SI_BUS_11 3;
BA_ "GenSigStartValue" SG_ 1413 SI_BUS_11 1;
BA_ "GenSigSwitchedByIgnition" SG_ 1413 SI_BUS_11 0;
BA_ "GenSigSendType" SG_ 1413 SI_BUS_12 3;
BA_ "GenSigStartValue" SG_ 1413 SI_BUS_12 1;
BA_ "GenSigSwitchedByIgnition" SG_ 1413 SI_BUS_12 0;
BA_ "GenSigSendType" SG_ 1413 SI_BUS_13 3;
BA_ "GenSigStartValue" SG_ 1413 SI_BUS_13 1;
BA_ "GenSigSwitchedByIgnition" SG_ 1413 SI_BUS_13 0;
BA_ "GenSigSendType" SG_ 1413 SI_BUS_14 3;
BA_ "GenSigStartValue" SG_ 1413 SI_BUS_14 1;
BA_ "GenSigSwitchedByIgnition" SG_ 1413 SI_BUS_14 0;
BA_ "GenSigSendType" SG_ 1413 SI_BUS_15 3;
BA_ "GenSigStartValue" SG_ 1413 SI_BUS_15 1;
BA_ "GenSigSwitchedByIgnition" SG_ 1413 SI_BUS_15 0;
BA_ "GenSigSendType" SG_ 1413 SI_Bus_Identifikation 0;
BA_ "GenSigSwitchedByIgnition" SG_ 1413 SI_Bus_Identifikation 0;
BA_ "GenSigSendType" SG_ 1413 SI_CAB 3;
BA_ "GenSigFuncType" SG_ 1413 SI_CAB 16;
BA_ "GenSigSwitchedByIgnition" SG_ 1413 SI_CAB 0;
BA_ "GenSigSendType" SG_ 1413 SI_Diagnose_Aktiv 3;
BA_ "GenSigSwitchedByIgnition" SG_ 1413 SI_Diagnose_Aktiv 0;
BA_ "GenSigSendType" SG_ 1413 SI_NWDF 3;
BA_ "GenSigSwitchedByIgnition" SG_ 1413 SI_NWDF 0;
BA_ "GenSigSendType" SG_ 1413 SI_NWDF_gueltig 3;
BA_ "GenSigFuncType" SG_ 1413 SI_NWDF_gueltig 8;
BA_ "GenSigSwitchedByIgnition" SG_ 1413 SI_NWDF_gueltig 0;
BA_ "GenSigSendType" SG_ 1413 SI_QRS_Mode 3;
BA_ "GenSigSwitchedByIgnition" SG_ 1413 SI_QRS_Mode 0;
BA_ "GenSigSendType" SG_ 1413 SI_Sammel_SG_Fehler 0;
BA_ "GenSigStartValue" SG_ 1413 SI_Sammel_SG_Fehler 63;
BA_ "GenSigSwitchedByIgnition" SG_ 1413 SI_Sammel_SG_Fehler 0;
BA_ "GenSigSendType" SG_ 1413 SI_Sammelfehler 3;
BA_ "GenSigSwitchedByIgnition" SG_ 1413 SI_Sammelfehler 0;
BA_ "GenSigSendType" SG_ 1413 SI_T_Mode 3;
BA_ "GenSigSwitchedByIgnition" SG_ 1413 SI_T_Mode 0;
BA_ "GenSigSendType" SG_ 1413 SI_T_Schutz 3;
BA_ "GenSigSwitchedByIgnition" SG_ 1413 SI_T_Schutz 0;
BA_ "GenSigSendType" SG_ 1375 TME_Absperrventil1_oeffnen 0;
BA_ "GenSigSwitchedByIgnition" SG_ 1375 TME_Absperrventil1_oeffnen 0;
BA_ "GenSigSendType" SG_ 1375 TME_AC_LED 3;
BA_ "GenSigSwitchedByIgnition" SG_ 1375 TME_AC_LED 0;
BA_ "GenSigSendType" SG_ 1375 TME_AC_Rueckmeldung 0;
BA_ "GenSigSwitchedByIgnition" SG_ 1375 TME_AC_Rueckmeldung 0;
BA_ "Fehlerwert" SG_ 1375 TME_AC_Rueckmeldung 3;
BA_ "GenSigSendType" SG_ 1375 TME_Freigabe_Luft_PTC 0;
BA_ "GenSigSwitchedByIgnition" SG_ 1375 TME_Freigabe_Luft_PTC 0;
BA_ "GenSigSendType" SG_ 1375 TME_Freigabe_Vorkond 3;
BA_ "GenSigSwitchedByIgnition" SG_ 1375 TME_Freigabe_Vorkond 0;
BA_ "GenSigSendType" SG_ 1375 TME_Frischluftklappe_Soll 0;
BA_ "GenSigStartValue" SG_ 1375 TME_Frischluftklappe_Soll 126;
BA_ "GenSigSwitchedByIgnition" SG_ 1375 TME_Frischluftklappe_Soll 0;
BA_ "Fehlerwert" SG_ 1375 TME_Frischluftklappe_Soll 127;
BA_ "GenSigSendType" SG_ 1375 TME_Heizstrategie 3;
BA_ "GenSigSwitchedByIgnition" SG_ 1375 TME_Heizstrategie 0;
BA_ "Fehlerwert" SG_ 1375 TME_Heizstrategie 15;
BA_ "GenSigSendType" SG_ 1375 TME_Heizungspumpen_Anst 0;
BA_ "GenSigStartValue" SG_ 1375 TME_Heizungspumpen_Anst 14;
BA_ "GenSigSwitchedByIgnition" SG_ 1375 TME_Heizungspumpen_Anst 0;
BA_ "Fehlerwert" SG_ 1375 TME_Heizungspumpen_Anst 13;
BA_ "GenSigSendType" SG_ 1375 TME_Kbr_Innenraum 3;
BA_ "GenSigSwitchedByIgnition" SG_ 1375 TME_Kbr_Innenraum 0;
BA_ "GenSigSendType" SG_ 1375 TME_Klima_Defizit 0;
BA_ "GenSigStartValue" SG_ 1375 TME_Klima_Defizit 254;
BA_ "GenSigSwitchedByIgnition" SG_ 1375 TME_Klima_Defizit 0;
BA_ "Fehlerwert" SG_ 1375 TME_Klima_Defizit 255;
BA_ "GenSigSendType" SG_ 1375 TME_Kuehlmittel_Sensor 0;
BA_ "GenSigSwitchedByIgnition" SG_ 1375 TME_Kuehlmittel_Sensor 0;
BA_ "GenSigSendType" SG_ 1375 TME_Nachlaufzeit_Heizp 0;
BA_ "GenSigSwitchedByIgnition" SG_ 1375 TME_Nachlaufzeit_Heizp 0;
BA_ "GenSigSendType" SG_ 1375 TME_Systemstatus 3;
BA_ "GenSigSwitchedByIgnition" SG_ 1375 TME_Systemstatus 0;
BA_ "Fehlerwert" SG_ 1375 TME_Systemstatus 3;
BA_ "GenSigSendType" SG_ 1375 TME_Temp_KM_vor_HWT 0;
BA_ "GenSigStartValue" SG_ 1375 TME_Temp_KM_vor_HWT 254;
BA_ "GenSigSwitchedByIgnition" SG_ 1375 TME_Temp_KM_vor_HWT 0;
BA_ "Fehlerwert" SG_ 1375 TME_Temp_KM_vor_HWT 255;
BA_ "GenSigSendType" SG_ 1375 TME_Umluftklappe_Soll 0;
BA_ "GenSigSwitchedByIgnition" SG_ 1375 TME_Umluftklappe_Soll 0;
BA_ "Fehlerwert" SG_ 1375 TME_Umluftklappe_Soll 127;
BA_ "GenSigSendType" SG_ 1375 TME_Verdampfer_Status 3;
BA_ "GenSigSwitchedByIgnition" SG_ 1375 TME_Verdampfer_Status 0;
BA_ "GenSigSendType" SG_ 1375 TME_VoKo_Strategie_Anzeige 3;
BA_ "GenSigStartValue" SG_ 1375 TME_VoKo_Strategie_Anzeige 14;
BA_ "GenSigSwitchedByIgnition" SG_ 1375 TME_VoKo_Strategie_Anzeige 0;
BA_ "Fehlerwert" SG_ 1375 TME_VoKo_Strategie_Anzeige 15;
BA_ "GenSigSendType" SG_ 1375 TME_Waermepumpe_aktiv 0;
BA_ "GenSigSwitchedByIgnition" SG_ 1375 TME_Waermepumpe_aktiv 0;
BA_ "GenSigSendType" SG_ 1375 TME_Zuheizer_Freigabe 3;
BA_ "GenSigSwitchedByIgnition" SG_ 1375 TME_Zuheizer_Freigabe 0;
BA_ "GenSigSendType" SG_ 2527679762 TPUI_WarnLvlCmft 0;
BA_ "GenSigStartValue" SG_ 2527679762 TPUI_WarnLvlCmft 14;
BA_ "GenSigSwitchedByIgnition" SG_ 2527679762 TPUI_WarnLvlCmft 0;
BA_ "Fehlerwert" SG_ 2527679762 TPUI_WarnLvlCmft 15;
BA_ "GenSigSendType" SG_ 2527679762 TPUI_WarnLvlMaxV 0;
BA_ "GenSigStartValue" SG_ 2527679762 TPUI_WarnLvlMaxV 14;
BA_ "GenSigSwitchedByIgnition" SG_ 2527679762 TPUI_WarnLvlMaxV 0;
BA_ "Fehlerwert" SG_ 2527679762 TPUI_WarnLvlMaxV 15;
BA_REL_ "GenSigTimeoutTime" BU_SG_REL_ AEM SG_ 1413 SI_NWDF 5000;
BA_REL_ "GenSigTimeoutTime" BU_SG_REL_ AEM SG_ 1413 SI_NWDF_gueltig 5000;
BA_REL_ "GenSigTimeoutTime" BU_SG_REL_ E_Sound SG_ 424 SARA_Accel_X_r 500;
BA_REL_ "GenSigTimeoutTime" BU_SG_REL_ E_Sound SG_ 1413 SI_NWDF 5000;
BA_REL_ "GenSigTimeoutTime" BU_SG_REL_ E_Sound SG_ 1413 SI_NWDF_gueltig 5000;
BA_REL_ "GenSigTimeoutTime" BU_SG_REL_ FLA SG_ 424 SARA_Omega_Z_r 500;
BA_REL_ "GenSigTimeoutTime" BU_SG_REL_ FLA SG_ 424 SARA_CF_Omega_Z_r 500;
BA_REL_ "GenSigTimeoutTime" BU_SG_REL_ FLA SG_ 980 BH_Fernlicht 2000;
BA_REL_ "GenSigTimeoutTime" BU_SG_REL_ FLA SG_ 1413 SI_NWDF 5000;
BA_REL_ "GenSigTimeoutTime" BU_SG_REL_ FLA SG_ 1413 SI_NWDF_gueltig 5000;
BA_REL_ "GenSigTimeoutTime" BU_SG_REL_ Gateway SG_ 1529 RDK_Warnungen_02 3200;
BA_REL_ "GenSigTimeoutTime" BU_SG_REL_ Gateway SG_ 1528 SAK_Charisma_FahrPr 5000;
BA_REL_ "GenSigTimeoutTime" BU_SG_REL_ Gateway SG_ 1528 SAK_Charisma_Status 5000;
BA_REL_ "GenSigTimeoutTime" BU_SG_REL_ Gateway SG_ 1011 SCR_Sent_Level_Aktivtank 1000;
BA_REL_ "GenSigTimeoutTime" BU_SG_REL_ Gateway SG_ 1507 SCR_Heizkreis_3_Strom 5000;
BA_REL_ "GenSigTimeoutTime" BU_SG_REL_ Gateway SG_ 1507 SCR_Leitungsheizung_Strom 5000;
BA_REL_ "GenSigTimeoutTime" BU_SG_REL_ Gateway SG_ 1507 SCR_Tankheizung_Strom 5000;
BA_REL_ "GenSigTimeoutTime" BU_SG_REL_ Gateway SG_ 1313 STH_Zusatzheizung 2000;
BA_REL_ "GenSigTimeoutTime" BU_SG_REL_ Gateway SG_ 1313 STH_LED 2000;
BA_REL_ "GenSigTimeoutTime" BU_SG_REL_ Gateway SG_ 1313 STH_Heizleistung 2000;
BA_REL_ "GenSigTimeoutTime" BU_SG_REL_ Gateway_PAG SG_ 1529 RDK_Warnungen_02 3200;
BA_REL_ "GenSigTimeoutTime" BU_SG_REL_ Gateway_PAG SG_ 1529 RDK_Reifentemperatur_Lampe 3200;
BA_REL_ "GenSigTimeoutTime" BU_SG_REL_ Gateway_PAG SG_ 1528 SAK_Charisma_FahrPr 5000;
BA_REL_ "GenSigTimeoutTime" BU_SG_REL_ Gateway_PAG SG_ 1528 SAK_Charisma_Status 5000;
BA_REL_ "GenSigTimeoutTime" BU_SG_REL_ Gateway_PAG SG_ 1011 SCR_Sent_Level_Aktivtank 1000;
BA_REL_ "GenSigTimeoutTime" BU_SG_REL_ Gateway_PAG SG_ 1507 SCR_Heizkreis_3_Strom 5000;
BA_REL_ "GenSigTimeoutTime" BU_SG_REL_ Gateway_PAG SG_ 1507 SCR_Leitungsheizung_Strom 5000;
BA_REL_ "GenSigTimeoutTime" BU_SG_REL_ Gateway_PAG SG_ 1507 SCR_Tankheizung_Strom 5000;
BA_REL_ "GenSigTimeoutTime" BU_SG_REL_ Gateway_PAG SG_ 1313 STH_Zusatzheizung 2000;
BA_REL_ "GenSigTimeoutTime" BU_SG_REL_ Gateway_PAG SG_ 1313 STH_LED 2000;
BA_REL_ "GenSigTimeoutTime" BU_SG_REL_ Gateway_PAG SG_ 1313 STH_Heizleistung 2000;
BA_REL_ "GenSigTimeoutTime" BU_SG_REL_ ISE SG_ 424 SARA_Accel_X_r 500;
BA_REL_ "GenSigTimeoutTime" BU_SG_REL_ ISE SG_ 1413 SI_NWDF 5000;
BA_REL_ "GenSigTimeoutTime" BU_SG_REL_ ISE SG_ 1413 SI_NWDF_gueltig 5000;
BA_REL_ "GenSigTimeoutTime" BU_SG_REL_ NightVision SG_ 1440 LS_Helligkeit_IR 2000;
BA_REL_ "GenSigTimeoutTime" BU_SG_REL_ NightVision SG_ 1440 LS_Helligkeit_FW 2000;
BA_REL_ "GenSigTimeoutTime" BU_SG_REL_ NightVision SG_ 1440 LS_defekt 2000;
BA_REL_ "GenSigTimeoutTime" BU_SG_REL_ NightVision SG_ 1440 LS_Verbau 2000;
BA_REL_ "GenSigTimeoutTime" BU_SG_REL_ NightVision SG_ 1440 RS_Verbau 2000;
BA_REL_ "GenSigTimeoutTime" BU_SG_REL_ NightVision SG_ 1440 RS_defekt 2000;
BA_REL_ "GenSigTimeoutTime" BU_SG_REL_ NightVision SG_ 1440 RS_Wischergeschwindigkeit 2000;
BA_REL_ "GenSigTimeoutTime" BU_SG_REL_ NightVision SG_ 424 SARA_Omega_Z_r 500;
BA_REL_ "GenSigTimeoutTime" BU_SG_REL_ NightVision SG_ 424 SARA_CF_Omega_Z_r 500;
BA_REL_ "GenSigTimeoutTime" BU_SG_REL_ NightVision SG_ 505 STP_Funktion_freigegeben 5000;
BA_REL_ "GenSigTimeoutTime" BU_SG_REL_ NightVision SG_ 1413 SI_NWDF 5000;
BA_REL_ "GenSigTimeoutTime" BU_SG_REL_ NightVision SG_ 1413 SI_NWDF_gueltig 5000;
BA_REL_ "GenSigTimeoutTime" BU_SG_REL_ RDK SG_ 1413 SI_QRS_Mode 5000;
BA_REL_ "GenSigTimeoutTime" BU_SG_REL_ RDK SG_ 1413 SI_T_Mode 5000;
BA_REL_ "GenSigTimeoutTime" BU_SG_REL_ RDK SG_ 1413 SI_NWDF 5000;
BA_REL_ "GenSigTimeoutTime" BU_SG_REL_ RDK SG_ 1413 SI_NWDF_gueltig 5000;
BA_REL_ "GenSigTimeoutTime" BU_SG_REL_ SAK SG_ 1413 SI_NWDF 5000;
BA_REL_ "GenSigTimeoutTime" BU_SG_REL_ SAK SG_ 1413 SI_NWDF_gueltig 5000;
BA_REL_ "GenSigTimeoutTime" BU_SG_REL_ SAK2 SG_ 1413 SI_NWDF 5000;
BA_REL_ "GenSigTimeoutTime" BU_SG_REL_ SAK2 SG_ 1413 SI_NWDF_gueltig 5000;
BA_REL_ "GenSigTimeoutTime" BU_SG_REL_ SCR SG_ 1413 SI_BUS_10 5000;
BA_REL_ "GenSigTimeoutTime" BU_SG_REL_ STH_MLBevo SG_ 1413 SI_QRS_Mode 5000;
BA_REL_ "GenSigTimeoutTime" BU_SG_REL_ STH_MLBevo SG_ 1413 SI_T_Mode 5000;
BA_REL_ "GenSigTimeoutTime" BU_SG_REL_ STH_MLBevo SG_ 1413 SI_NWDF 5000;
BA_REL_ "GenSigTimeoutTime" BU_SG_REL_ STH_MLBevo SG_ 1413 SI_NWDF_gueltig 5000;
BA_REL_ "GenSigTimeoutTime" BU_SG_REL_ STH_MLBevo SG_ 1413 SI_BUS_01 5000;
BA_REL_ "GenSigTimeoutTime" BU_SG_REL_ STH_MLBevo SG_ 1413 SI_BUS_03 5000;
BA_REL_ "GenSigTimeoutTime" BU_SG_REL_ STH_MLBevo SG_ 1375 TME_Zuheizer_Freigabe 5000;
BA_REL_ "GenSigTimeoutTime" BU_SG_REL_ STH_MLBevo SG_ 1375 TME_Heizungspumpen_Anst 5000;
BA_REL_ "GenSigTimeoutTime" BU_SG_REL_ STH_MLBevo SG_ 1375 TME_Nachlaufzeit_Heizp 5000;
BA_REL_ "GenSigTimeoutTime" BU_SG_REL_ STH_MLBevo SG_ 1375 TME_Absperrventil1_oeffnen 5000;
BA_REL_ "GenSigTimeoutTime" BU_SG_REL_ TopView SG_ 424 SARA_Accel_X_r 500;
BA_REL_ "GenSigTimeoutTime" BU_SG_REL_ TopView SG_ 424 SARA_Accel_Y_r 500;
BA_REL_ "GenSigTimeoutTime" BU_SG_REL_ TopView SG_ 424 SARA_Omega_Z_r 500;
BA_REL_ "GenSigTimeoutTime" BU_SG_REL_ TopView SG_ 424 SARA_CF_Accel_X_r 500;
BA_REL_ "GenSigTimeoutTime" BU_SG_REL_ TopView SG_ 424 SARA_CF_Accel_Y_r 500;
BA_REL_ "GenSigTimeoutTime" BU_SG_REL_ TopView SG_ 424 SARA_CF_Omega_Z_r 500;
BA_REL_ "GenSigTimeoutTime" BU_SG_REL_ TopView SG_ 980 BH_Blinker_li 2000;
BA_REL_ "GenSigTimeoutTime" BU_SG_REL_ TopView SG_ 980 BH_Blinker_re 2000;
BA_REL_ "GenSigTimeoutTime" BU_SG_REL_ TopView SG_ 1710 SP_S_Klappen 5000;
BA_REL_ "GenSigTimeoutTime" BU_SG_REL_ TopView SG_ 1413 SI_NWDF 5000;
BA_REL_ "GenSigTimeoutTime" BU_SG_REL_ TopView SG_ 1413 SI_NWDF_gueltig 5000;
BA_REL_ "GenSigTimeoutTime" BU_SG_REL_ TopView SG_ 1413 SI_CAB 5000;
VAL_ 1529 RDK_FMVSS138_Lampe 0 "RDK_WaLa_inaktiv" 1 "RDK_WaLa_aktiv" ;
VAL_ 1529 RDK_FMVSS138_MIL 0 "keine_Stoerungsanzeige" 1 "Stoerungsanzeige" ;
VAL_ 1529 RDK_Kalibrierung 0 "BAP_Kalibrierung" 1 "CAN_Kombitaster_Kalibrierung" ;
VAL_ 1529 RDK_Reifendruck_Lampe 0 "RDK_WaLa_inaktiv" 1 "RDK_WaLa_aktiv" ;
VAL_ 1529 RDK_Warnungen_02 0 "keine_Anzeige" 1 "Reifen_allgemein_Warnstufe_1" 2 "Reifen_vorne_links_Warnstufe_1" 3 "Reifen_vorne_rechts_Warnstufe_1" 4 "Reifen_hinten_links_Warnstufe_1" 5 "Reifen_hinten_rechts_Warnstufe_1" 6 "Reifen_allgemein_Warnstufe_2" 7 "Reifen_vorne_links_Warnstufe_2" 8 "Reifen_vorne_rechts_Warnstufe_2" 9 "Reifen_hinten_links_Warnstufe_2" 10 "Reifen_hinten_rechts_Warnstufe_2" 11 "Reifen_allgemein_Warnstufe_3" 12 "Reifen_vorne_links_Warnstufe_3" 13 "Reifen_vorne_rechts_Warnstufe_3" 14 "Reifen_hinten_links_Warnstufe_3" 15 "Reifen_hinten_rechts_Warnstufe_3" 16 "Akustikausgabe_Kalibrierung_io" 17 "Textausgabe_Kalibrierung_io" 18 "Akustik_Textausgabe_Kalibrier_io" 19 "RDK_aktiviert" 20 "RDK_deaktiviert" 21 "RDK_Systemstoerung" 22 "RDK_Systemstoerung_temporaer" 23 "V_Warnschwelle_1" 24 "V_Warnschwelle_2" 25 "Radwechsel_allgemein" 26 "Teilueberwachung" 27 "V_Warnschwelle_3" 28 "V_Warnschwelle_4" 29 "V_Warnschwelle_5" 30 "Reifendruecke_kalibrieren" ;
VAL_ 1529 RDK_angelernt 0 "nicht_angelernt" 1 "angelernt" ;
VAL_ 1529 RDK_Reifentemperatur_Lampe 0 "RDK_WaLa_inaktiv" 1 "RDK_WaLa_aktiv" ;
VAL_ 1529 RDK_RS_aktiv 0 "inaktiv" 1 "aktiv" ;
VAL_ 1529 RDK_Text_7 0 "inaktiv" 1 "aktiv" ;
VAL_ 1529 RDK_W_1_Reifen_HL 0 "inaktiv" 1 "aktiv" ;
VAL_ 1529 RDK_W_1_Reifen_HR 0 "inaktiv" 1 "aktiv" ;
VAL_ 1529 RDK_W_1_Reifen_VL 0 "inaktiv" 1 "aktiv" ;
VAL_ 1529 RDK_W_1_Reifen_VR 0 "inaktiv" 1 "aktiv" ;
VAL_ 1529 RDK_W_2_Reifen_HL 0 "inaktiv" 1 "aktiv" ;
VAL_ 1529 RDK_W_2_Reifen_HR 0 "inaktiv" 1 "aktiv" ;
VAL_ 1529 RDK_W_2_Reifen_VL 0 "inaktiv" 1 "aktiv" ;
VAL_ 1529 RDK_W_2_Reifen_VR 0 "inaktiv" 1 "aktiv" ;
VAL_ 2589283632 RDK_Reifentyp_02 0 "Init" 1 "SummerSport" 2 "Offroad" ;
VAL_ 2589283632 RDK_Reifengroesse 0 "Init" 1 "Zoll_16" 2 "Zoll_17" 3 "Zoll_18" 4 "Zoll_19" 5 "Zoll_20" 6 "Zoll_21" 7 "Zoll_22" ;
VAL_ 2589283632 RDK_Reifentyp 0 "Init" 1 "Winter" 2 "Sommer" 3 "Ganzjahresreifen" 4 "Kundenspezifisch" 5 "UHP" 6 "eDistance" 7 "ePerformance" ;
VAL_ 2589283632 RDK_SollDruck_VA 63 "Init" ;
VAL_ 2589283632 RDK_SollDruck_HA 63 "Init" ;
VAL_ 1651 RDK_Druck_VL_unkomp 63 "Init" ;
VAL_ 1651 RDK_Signal_Alter_VL 0 "Signal_ist_aktuell__Init" 1 "kein_neues_Signal_fuer_3_Minuten" 2 "kein_neues_Signal_fuer_6_Minuten" 3 "kein_neues_Signal_fuer_9_Minuten" ;
VAL_ 1651 RDK_Druck_VR_unkomp 63 "Init" ;
VAL_ 1651 RDK_Signal_Alter_VR 0 "Signal_ist_aktuell__Init" 1 "kein_neues_Signal_fuer_3_Minuten" 2 "kein_neues_Signal_fuer_6_Minuten" 3 "kein_neues_Signal_fuer_9_Minuten" ;
VAL_ 1651 RDK_Druck_HL_unkomp 63 "Init" ;
VAL_ 1651 RDK_Signal_Alter_HL 0 "Signal_ist_aktuell__Init" 1 "kein_neues_Signal_fuer_3_Minuten" 2 "kein_neues_Signal_fuer_6_Minuten" 3 "kein_neues_Signal_fuer_9_Minuten" ;
VAL_ 1651 RDK_Druck_HR_unkomp 63 "Init" ;
VAL_ 1651 RDK_Signal_Alter_HR 0 "Signal_ist_aktuell__Init" 1 "kein_neues_Signal_fuer_3_Minuten" 2 "kein_neues_Signal_fuer_6_Minuten" 3 "kein_neues_Signal_fuer_9_Minuten" ;
VAL_ 1651 RDK_R_Temp_VL 254 "Signal_nicht_verfuegbar" 255 "Fehler" ;
VAL_ 1651 RDK_R_Temp_VR 254 "Signal_nicht_verfuegbar" 255 "Fehler" ;
VAL_ 1651 RDK_R_Temp_HL 254 "Signal_nicht_verfuegbar" 255 "Fehler" ;
VAL_ 1651 RDK_R_Temp_HR 254 "Signal_nicht_verfuegbar" 255 "Fehler" ;
VAL_ 2463978816 TPMS_WhlChgDetFrLe 0 "No_wheel_change_detected" 1 "Wheel_change_detected" ;
VAL_ 2463978816 TPMS_WhlChgDetFrRi 0 "No_wheel_change_detected" 1 "Wheel_change_detected" ;
VAL_ 2463978816 TPMS_WhlChgDetReLe 0 "No_wheel_change_detected" 1 "Wheel_change_detected" ;
VAL_ 2463978816 TPMS_WhlChgDetReRi 0 "No_wheel_change_detected" 1 "Wheel_change_detected" ;
VAL_ 2463978816 TPMS_WarnWhlChgDet 0 "Warning_wheel_change_detected_in" 1 "Warning_wheel_change_detected_ac" ;
VAL_ 2463978816 Solldruck_TempAbhaengig_HR 63 "Init" ;
VAL_ 2463978816 Solldruck_TempAbhaengig_VL 63 "Init" ;
VAL_ 2463978816 Solldruck_TempAbhaengig_VR 63 "Init" ;
VAL_ 2463978816 Solldruck_TempAbhaengig_HL 63 "Init" ;
VAL_ 2463978816 Solldruck_Fahrerauswahl 0 "Solldruck_Fahrerauswahl_A" 1 "Solldruck_Fahrerauswahl_B" 2 "Solldruck_Fahrerauswahl_C" 3 "Solldruck_Fahrerauswahl_D" ;
VAL_ 2527679876 TPMS_SensSigAgeFrLe 11 "Larger_than_10_minutes" 12 "Reserved" 13 "Reserved" 14 "Init" 15 "Fehler" ;
VAL_ 2527679876 TPMS_SensSigAgeFrRi 11 "Larger_than_10_minutes" 12 "Reserved" 13 "Reserved" 14 "Init" 15 "Fehler" ;
VAL_ 2527679876 TPMS_SensSigAgeReLe 11 "Larger_than_10_minutes" 12 "Reserved" 13 "Reserved" 14 "Init" 15 "Fehler" ;
VAL_ 2527679876 TPMS_SensSigAgeReRi 11 "Larger_than_10_minutes" 12 "Reserved" 13 "Reserved" 14 "Init" 15 "Fehler" ;
VAL_ 2527679876 TPMS_SensPFrLe 63 "Init" ;
VAL_ 2527679876 TPMS_SensPFrRi 63 "Init" ;
VAL_ 2527679876 TPMS_SensPReLe 63 "Init" ;
VAL_ 2527679876 TPMS_SensPReRi 63 "Init" ;
VAL_ 1711 RV_Video_on 0 "Kamerabild wird nicht angezeigt" 1 "Kamerabild wird angezeigt" ;
VAL_ 1711 RV_Dark_Screen 0 "Kamerabild nicht verdunkeln" 1 "Kamerabild verdunkeln" ;
VAL_ 1711 RV_HMI_Mode 0 "Parkluecke  (Modus 1)" 1 "Parallel zur Straße (Modus 2)" 2 "reserviert" 3 "Kalibrierung (nur Diagnose)" ;
VAL_ 1711 RV_GL_side 0 "Guidelines_abgeschaltet" 1 "Guidelines_Anzeige_rechte_Seite" 2 "Guiedelines_Anzeige_linke_Seite" 3 "Guiedelines_Anzeige_beide_Seiten" ;
VAL_ 1711 RV_System_aktiv 0 "System nicht betriebsbereit" 1 "System betriebsbereit" ;
VAL_ 1711 RV_Reinigung_Anf 0 "nicht_reinigen" 1 "reinigen" ;
VAL_ 1711 RV_Settings_enabled 0 "Menu 'Einstellungen' nicht aktiviert" 1 "Menu 'Einstellungen' aktiviert" ;
VAL_ 1711 RV_Menu_Item 0 "HMI Mode als ausgewaehlt markiert" 1 "Helligkeit als ausgewaehlt markiert" 2 "Kontrast als ausgewaehlt markiert" 3 "Farbsaettigung als ausgewaehlt markiert" ;
VAL_ 1711 SV_Video_on 0 "SideView_aus_/_nicht_verbaut" 1 "SideView_an" ;
VAL_ 1711 RV_Calib_Fehler 0 "Kalibrierung_i.O." 1 "RearView_nicht_kalibriert" ;
VAL_ 1711 RV_GL_Trailer_connect 0 "Guidelines_werden_angezeigt" 1 "Guidelines_wegen_angekoppeltem_Anhänger_deaktiviert" ;
VAL_ 1711 RV_GL_Trunk_open 0 "Guidelines_werden_angezeigt" 1 "Guidelines_wegen_geöffneter_Heckklappe_deaktiviert" ;
VAL_ 1711 RV_GL_LWS_Fehler 0 "Guidelines_werden_angezeigt" 1 "Guidelines_wegen_nicht_kalibriertem_Lenkwinkelsensor_deaktiviert" ;
VAL_ 1711 ZFAS_Umfeldbeleuchtung_Anf 0 "nicht_angefordert" 1 "angefordert" ;
VAL_ 1440 LS_Helligkeit_IR 254 "Init" 255 "Fehler" ;
VAL_ 1440 LS_Helligkeit_FW 1022 "Init" 1023 "Fehler" ;
VAL_ 1440 LS_defekt 0 "OK" 1 "defekt" ;
VAL_ 1440 LS_Verbau 0 "Init" 1 "Lichtsensor_verbaut" ;
VAL_ 1440 RS_Regenmenge 0 "0" 1 "0,0_bis_0,3" 2 "0,31_bis_1,4" 3 "1,41_bis_2,0" 4 "2,01_bis_2,8" 5 "2,81_bis_3,3" 6 "3,31_bis_4,0" 7 "4,01_bis_5,0" 8 "5,01_bis_7,0" 9 "7,01_bis_9,0" 10 "9,01_bis_11,0" 11 "11,01_bis_15,0" 12 "15,01_bis_22,0" 13 ">22,01" 14 "Init" 15 "Fehler" ;
VAL_ 1440 RS_Verbau 0 "Init" 1 "Regensensor verbaut" ;
VAL_ 1440 RS_Verglasung_schliessen 0 "Verglasung nicht schliessen" 1 "Verglasung schliessen" ;
VAL_ 1440 RS_defekt 0 "OK" 1 "defekt" ;
VAL_ 1440 RS_Wischergeschwindigkeit 0 "kein Wischen" 1 "42 Huebe/min" 2 "45 Huebe/min" 3 "48 Huebe/min" 4 "51 Huebe/min" 5 "54 Huebe/min" 6 "57 Huebe/min" 7 "60 Huebe/min" ;
VAL_ 1440 RLS_Vorfeldhelligkeit_Boost 0 "groesser_24413_Lux" 1 "bis_24413_Lux" 2 "bis_22193_Lux" 3 "bis_20176_Lux" 4 "bis_18342_Lux" 5 "bis_16647_Lux" 6 "bis_15158_Lux" 7 "bis_13780_Lux" 8 "bis_12527_Lux" 9 "bis_11388_Lux" 10 "bis_10353_Lux" 11 "bis_9412_Lux" 12 "bis_8556_Lux" 13 "bis_7778_Lux" 14 "bis_7071_Lux" 15 "bis_6428_Lux" ;
VAL_ 1528 SAK_Charisma_FahrPr 0 "keine_Funktion" 1 "Programm_1" 2 "Programm_2" 3 "Programm_3" 4 "Programm_4" 5 "Programm_5" 6 "Programm_6" 7 "Programm_7" 8 "Programm_8" 9 "Programm_9" 10 "Programm_10" 11 "Programm_11" 12 "Programm_12" 13 "Programm_13" 14 "Programm_14" 15 "Programm_15" ;
VAL_ 1528 SAK_Charisma_Status 0 "Init" 1 "verfuegbar" 2 "nicht_verfuegbar" 3 "asynchron_durch_Fahrerwunsch" ;
VAL_ 424 SARA_Accel_X_r 0 "nicht_verbaut" 8191 "Fehler" ;
VAL_ 424 SARA_Accel_Y_r 0 "nicht_verbaut" 8191 "Fehler" ;
VAL_ 424 SARA_Omega_Z_r 0 "nicht_verbaut" 8191 "Fehler" ;
VAL_ 424 SARA_CF_Accel_X_r 0 "gueltiger_Wert" 1 "nicht_belegt" 2 "nicht_belegt" 3 "temporaerer_Fehler" 4 "Init" 5 "Sensor_nicht_verbaut_Signal_nicht_berrechnet" 6 "Sensor_nicht_abgeglichen" 7 "Sensor_defekt" ;
VAL_ 424 SARA_CF_Accel_Y_r 0 "gueltiger_Wert" 1 "nicht_belegt" 2 "nicht_belegt" 3 "temporaerer_Fehler" 4 "Init" 5 "Sensor_nicht_verbaut_Signal_nicht_berrechnet" 6 "Sensor_nicht_abgeglichen" 7 "Sensor_defekt" ;
VAL_ 424 SARA_CF_Omega_Z_r 0 "gueltiger_Wert" 1 "nicht_belegt" 2 "nicht_belegt" 3 "temporaerer_Fehler" 4 "Init" 5 "Sensor_nicht_verbaut_Signal_nicht_berrechnet" 6 "Sensor_nicht_abgeglichen" 7 "Sensor_defekt" ;
VAL_ 1011 SCR_Sent_Levelsignal_Status 0 "kein_Wert_ermittelbar" 1 "Aggregatszustand_Mischphase" 2 "Aggregatszustand_Eis" 3 "Aggregatszustand_Fluessig" 6 "Fehler" 7 "Init" ;
VAL_ 1011 SCR_QBit_Level_Aktivtank_02 0 "gueltiger_Wert" 1 "Ersatz_Init_oder_Fehlerwert" ;
VAL_ 1011 SCR_Level_ReadAbove 0 "Readabove aus" 1 "Readabove aktiv" ;
VAL_ 1011 SCR_Dosierpumpe_Drehzahl 2046 "Init" 2047 "Fehler" ;
VAL_ 1011 SCR_Druck 1021 "nicht_verbaut" 1022 "Init" 1023 "Fehler" ;
VAL_ 1011 SCR_Level_Aktivtank 1021 "nicht_verbaut" 1022 "Init" 1023 "Fehler" ;
VAL_ 1011 SCR_Sent_Level_Aktivtank 1022 "Init" ;
VAL_ 1507 SCR_Heizkreis_3_Strom 253 "nicht_verbaut" 254 "Init" 255 "Fehler" ;
VAL_ 1507 SCR_Guetesensor 1021 "nicht_verbaut" 1022 "Init" 1023 "Fehler" ;
VAL_ 1507 SCR_Temp_Aktivtank 254 "Init" 255 "Fehler" ;
VAL_ 1507 SCR_Temp_Passivtank 253 "nicht_verbaut" 254 "Init" 255 "Fehler" ;
VAL_ 1507 SCR_Leitungsheizung_Strom 254 "Init" 255 "Fehler" ;
VAL_ 1507 SCR_Transferpumpe_Strom 253 "nicht_verbaut" 254 "Init" 255 "Fehler" ;
VAL_ 1507 SCR_Tankheizung_Strom 254 "Init" 255 "Fehler" ;
VAL_ 1508 SCR_Spannungsversorgung_Status 0 "kein_Fehler" 1 "KS-" 2 "KS+" 3 "OC" 4 "OOR+(Ueberspannung)" 5 "OOR-(Unterspannung)" 6 "RC+" 7 "RC-" 8 "KS+/OC" 9 "KS-/OC" 10 "KS-/KS+" 11 "KS-/KS+/OC" 12 "OOR+(FktEinschr_Ueberspg)" 13 "OOR-(FktEinschr_Unterspg)" 14 "frei" 15 "Diagnose_noch_nicht_beendet" ;
VAL_ 1508 SCR_VersorgungSensoren_Status_02 0 "kein_Fehler" 1 "KS-" 2 "KS+" 3 "OC" 4 "OOR+" 5 "OOR-" 6 "RC+" 7 "RC-" 10 "KS_Sensormasse" 11 "KS_Heizkreis_1" 12 "KS_Heizkreis_2" 13 "KS_Heizkreis_3" 14 "KS_Dosierpumpe" 15 "Diagnose_noch_nicht_beendet" ;
VAL_ 1508 SCR_Heizkreis_3_Status 0 "kein Fehler / Init / nicht verbaut" 1 "KS- (Kurzschluss nach minus)" 2 "KS+ (Kurzschluss nach plus)" 3 "OC (Leitungsunterbrechung)" 4 "OOR+ (Signal zu gross)" 5 "OOR- (Signal zu klein)" 6 "RC+ (Signal unplausibel zu gross)" 7 "RC- (Signal unplausibel zu klein)" 8 "KS+/OC (Kurzschluss nach plus/Unterbrechung)" 9 "KS-/OC  (Kurzschluss nach minus/Unterbrechung)" 10 "KS-/KS+  (Kurzschluss nach minus/plus)" 11 "KS-/KS+/OC (Kurzschluss nach minus/plus/Unterbrechung)" 12 "KS_Heizer" 13 "KS_Pumpe" 14 "frei" 15 "Diagnose_noch_nicht_beendet" ;
VAL_ 1508 SCR_Sensorversorgung_12V_Status 0 "kein_Fehler" 1 "KS-" 2 "KS+" 3 "OC" 4 "OOR+" 5 "OOR-" 6 "RC+" 7 "RC-" 10 "KS_Sensormasse" 15 "Diagnose_noch_nicht_beendet" ;
VAL_ 1508 SCR_Leitungsheizung_Status 0 "kein Fehler / Init / nicht verbaut" 1 "KS- (Kurzschluss nach minus)" 2 "KS+ (Kurzschluss nach plus)" 3 "OC (Leitungsunterbrechung)" 4 "OOR+ (Signal zu gross)" 5 "OOR- (Signal zu klein)" 6 "RC+ (Signal unplausibel zu gross)" 7 "RC- (Signal unplausibel zu klein)" 8 "KS+/OC (Kurzschluss nach plus/Unterbrechung)" 9 "KS-/OC  (Kurzschluss nach minus/Unterbrechung)" 10 "KS-/KS+  (Kurzschluss nach minus/plus)" 11 "KS-/KS+/OC (Kurzschluss nach minus/plus/Unterbrechung)" 12 "KS_Heizer" 13 "KS_Pumpe" 14 "KS_Heizer_3" 15 "Diagnose_noch_nicht_beendet" ;
VAL_ 1508 SCR_Tankheizung_Status 0 "kein Fehler / Init / nicht verbaut" 1 "KS- (Kurzschluss nach minus)" 2 "KS+ (Kurzschluss nach plus)" 3 "OC (Leitungsunterbrechung)" 4 "OOR+ (Signal zu gross)" 5 "OOR- (Signal zu klein)" 6 "RC+ (Signal unplausibel zu gross)" 7 "RC- (Signal unplausibel zu klein)" 8 "KS+/OC (Kurzschluss nach plus/Unterbrechung)" 9 "KS-/OC  (Kurzschluss nach minus/Unterbrechung)" 10 "KS-/KS+  (Kurzschluss nach minus/plus)" 11 "KS-/KS+/OC (Kurzschluss nach minus/plus/Unterbrechung)" 12 "KS_Heizer" 13 "KS_Pumpe" 14 "frei" 15 "Diagnose_noch_nicht_beendet" ;
VAL_ 1508 SCR_Druck_Status_02 0 "kein_Fehler" 1 "KS_minus" 2 "KS_plus" 3 "OC_Leitungsunterbrechung" 4 "OOR_plus" 5 "OOR_minus" 6 "RC_plus" 7 "RC_minus" 8 "KS_plus_Unterbrechung" 9 "KS_minus_OC_Opencircut" 11 "KS_Heizkreis_1" 12 "KS_Heizkreis_2" 13 "KS_Heizkreis_3" 14 "KS_Dosierpumpe" 15 "Diagnose_noch_nicht_beendet" ;
VAL_ 1508 SCR_Dosierpumpe_Status_Spule 0 "kein_Fehler" 1 "KS-" 2 "KS+" 3 "OC" 4 "OOR+" 5 "OOR-" 6 "RC+(Drehzahl_zu_hoch)" 7 "RC-(Drehzahl_zu_niedrig)" 8 "KS+/OC" 9 "KS-/OC" 10 "KS-/KS+" 11 "KS_Leitungsheizer" 12 "KS_zwischen_Phasen" 13 "KS_Heizer" 14 "KS_Heizer_3" 15 "Diagnose_noch_nicht_beendet" ;
VAL_ 1508 SCR_Transferpumpe_Status 0 "kein Fehler / Init / nicht verbaut" 1 "KS- (Kurzschluss nach minus)" 2 "KS+ (Kurzschluss nach plus)" 3 "OC (Leitungsunterbrechung)" 4 "OOR+ (Signal zu gross)" 5 "OOR- (Signal zu klein)" 6 "RC+ (Signal unplausibel zu gross)" 7 "RC- (Signal unplausibel zu klein)" 8 "KS+/OC (Kurzschluss nach plus/Unterbrechung)" 9 "KS-/OC  (Kurzschluss nach minus/Unterbrechung)" 10 "KS-/KS+  (Kurzschluss nach minus/plus)" 11 "KS-/KS+/OC (Kurzschluss nach minus/plus/Unterbrechung)" 12 "KS_Heizer" 13 "KS_Pumpe" 14 "KS_Heizer_3" 15 "Diagnose_noch_nicht_beendet" ;
VAL_ 1508 SCR_Level_Aktivtank_Status 0 "kein Fehler / Init / nicht verbaut" 1 "KS- (Kurzschluss nach minus)" 2 "KS+ (Kurzschluss nach plus)" 3 "OC (Leitungsunterbrechung)" 4 "OOR+ (Signal zu gross)" 5 "OOR- (Signal zu klein)" 6 "RC+ (Signal unplausibel zu gross)" 7 "RC- (Signal unplausibel zu klein)" 8 "KS+/OC (Kurzschluss nach plus/Unterbrechung)" 9 "KS-/OC  (Kurzschluss nach minus/Unterbrechung)" 10 "KS-/KS+  (Kurzschluss nach minus/plus)" 11 "KS-/KS+/OC (Kurzschluss nach minus/plus/Unterbrechung)" 12 "KS_Heizer" 13 "KS_Pumpe" 14 "frei" 15 "Diagnose_noch_nicht_beendet" ;
VAL_ 1508 SCR_Level_Passivtank_Status 0 "kein Fehler / Init / nicht verbaut" 1 "KS- (Kurzschluss nach minus)" 2 "KS+ (Kurzschluss nach plus)" 3 "OC (Leitungsunterbrechung)" 4 "OOR+ (Signal zu gross)" 5 "OOR- (Signal zu klein)" 6 "RC+ (Signal unplausibel zu gross)" 7 "RC- (Signal unplausibel zu klein)" 8 "KS+/OC (Kurzschluss nach plus/Unterbrechung)" 9 "KS-/OC  (Kurzschluss nach minus/Unterbrechung)" 10 "KS-/KS+  (Kurzschluss nach minus/plus)" 11 "KS-/KS+/OC (Kurzschluss nach minus/plus/Unterbrechung)" 12 "KS_Heizer" 13 "KS_Pumpe" 14 "frei" 15 "Diagnose_noch_nicht_beendet" ;
VAL_ 1508 SCR_Temp_Aktivtank_Status_02 0 "kein Fehler / Init / nicht verbaut" 1 "KS- (Kurzschluss nach minus)" 2 "KS+ (Kurzschluss nach plus)" 3 "OC (Leitungsunterbrechung)" 4 "OOR+ (Signal zu gross)" 5 "OOR- (Signal zu klein)" 6 "RC+ (Signal unplausibel zu gross)" 7 "RC- (Signal unplausibel zu klein)" 8 "KS-/OC (Kurzschluss nach Masse/ Leitungsunterbrechung)" 11 "KS_Heizkreis_1" 12 "KS_Heizkreis_2" 13 "KS_Heizkreis_3" 14 "KS_Dosierpumpe" 15 "Diagnose_noch_nicht_beendet" ;
VAL_ 1508 SCR_Temp_Passivtank_Status 0 "kein Fehler / Init / nicht verbaut" 1 "KS- (Kurzschluss nach minus)" 2 "KS+ (Kurzschluss nach plus)" 3 "OC (Leitungsunterbrechung)" 4 "OOR+ (Signal zu gross)" 5 "OOR- (Signal zu klein)" 6 "RC+ (Signal unplausibel zu gross)" 7 "RC- (Signal unplausibel zu klein)" 8 "KS+/OC (Kurzschluss nach plus/Unterbrechung)" 9 "KS-/OC  (Kurzschluss nach minus/Unterbrechung)" 10 "KS-/KS+  (Kurzschluss nach minus/plus)" 11 "KS-/KS+/OC (Kurzschluss nach minus/plus/Unterbrechung)" 12 "KS_Heizer" 13 "KS_Pumpe" 14 "frei" 15 "Diagnose_noch_nicht_beendet" ;
VAL_ 1509 SCR_Ansteuerung_Transferpumpe 0 "nicht_aktiv" 1 "aktiv" ;
VAL_ 1509 SCR_Ansteuerung_Dosierpumpe 0 "nicht_aktiv" 1 "aktiv" ;
VAL_ 1509 SCR_Ansteuerung_Heizkreis_3 0 "nicht_aktiv" 1 "aktiv" ;
VAL_ 1509 SCR_Ansteuerung_Leitungsheizung 0 "nicht_aktiv" 1 "aktiv" ;
VAL_ 1509 SCR_Ansteuerung_Tankheizung 0 "nicht_aktiv" 1 "aktiv" ;
VAL_ 1509 SCR_Steuergeraet_PMode 0 "PMode_nicht_aktiv" 1 "PMode_aktiv" ;
VAL_ 1526 SCR_Level_Aktivtank_OOR4Quality 0 "Füllstand i.O. für Qualitätsberechnung" 1 "Füllstand zu niedrig für Qualitätsberechnung" ;
VAL_ 1526 SCR_Level_Aktivtank_OOR_minus 0 "Level erfassbar" 1 "Level zu niedrig" ;
VAL_ 1526 SCR_Sent_1_Signalstatus 0 "kein Fehler" 1 "Sent Signal unplausibel" 2 "Sent Signal TimeOut" 3 "Diagnose noch nicht beendet" ;
VAL_ 1526 SCR_Sent_1_elektrischer_Status 0 "kein Fehler" 1 "KS- " 2 "KS+" 8 "KS_Versorgung_Sensoren" 11 "KS_Heizkreis_1" 12 "KS_Heizkreis_2" 13 "KS_Heizkreis_3" 14 "KS_Pumpe" 15 "Diagnose noch nicht beendet" ;
VAL_ 1526 SCR_Sent_Levelsensor 0 "kein Fehler" 1 "Levelsensor defekt" 2 "Sensortemperatur zu hoch" 3 "Sensorversorgung OOR" 5 "Levelsignal OOR+" 6 "Levelsignal OOR-" 7 "Diagnose noch nicht beendet" ;
VAL_ 1526 SCR_Sent_Qualitaetssensor 0 "kein Fehler" 1 "Qualitätssensor defekt" 2 "Fremdlicht" 3 "Sensorstoerung" 5 "OOR+" 6 "OOR-" 7 "Diagnose noch nicht beendet" ;
VAL_ 1526 SCR_Sent_Temperatursensor 0 "kein Fehler" 1 "Temperatursensor defekt" 5 "OOR+" 6 "OOR-" 7 "Diagnose noch nicht beendet" ;
VAL_ 1526 SCR_DEF_Qualitaet_Medium 0 "Mediumkonzentration ermittelbar" 1 "Mediumkonzentration nicht ermittelbar" ;
VAL_ 1526 SCR_QBit_Qualitaet 0 "gueltiger_Wert" 1 "Ersatz_Init_oder_Fehlerwert" ;
VAL_ 1526 SCR_Sent_2_Signalstatus 0 "kein_Fehler" 1 "Sent_Signal_unplausibel" 2 "Sent_Signal_TimeOut" 3 "Diagnose_noch_nicht_beendet" ;
VAL_ 1526 SCR_Temp_DEF2_Sensor_Status 0 "kein_Fehler" 1 "Temperatursensor_defekt" 5 "OOR+" 6 "OOR-" 7 "Diagnose_noch_nicht_beendet" ;
VAL_ 1526 SCR_Sent_2_elektrischer_Status 0 "kein_Fehler" 1 "KS- " 2 "KS+" 8 "KS_Versorgung_Sensoren" 11 "KS_Heizkreis_1" 12 "KS_Heizkreis_2" 13 "KS_Heizkreis_3" 14 "KS_Pumpe" 15 "Diagnose_noch_nicht_beendet" ;
VAL_ 1526 SCR_HAL_Sensorik_Status 0 "kein_Fehler" 1 "KS-" 2 "KS+" 3 "OC" 4 "OOR+" 5 "OOR-" 6 "RC+" 7 "RC-" 8 "KSplus_Unterbrechung" 9 "KSminus_Unterbrechung" 15 "Diagnose_noch_nicht_beendet" ;
VAL_ 1526 SCR_Steuergeraet_Heizung_Status 0 "kein_Fehler" 1 "Endstufe_Tankheizung_ueberhitzt" 2 "Endstufe_Leitungsheizung_ueberhitzt" 3 "Diagnose_noch_nicht_beendet" ;
VAL_ 1526 SCR_Steuergeraet_Pumpe_Status 0 "kein_Fehler" 1 "Endstufe_Pumpe_ueberhitzt" 2 "Pumpe_blockiert" 3 "Diagnose_noch_nicht_beendet" ;
VAL_ 1526 SCR_Steuergeraet_Relais_Status 0 "kein_Fehler" 1 "KS+ (Ausgang Leistungsrelais) " 2 "KS-/OC (Ausgang Leistungsrelais)" 3 "Diagnose_noch_nicht_beendet" ;
VAL_ 1526 SCR_Steuergeraet_Bus_Status 0 "kein_Fehler" 1 "Bus_Kommunikation_Fehler" 2 "Bus_Kommunikation_Stoerung_(temporaer)" 3 "Diagnose_noch_nicht_beendet" ;
VAL_ 1526 SCR_ECU_Datensatz_Status 0 "kein_Fehler" 1 "ungueltiger_Datensatz" 2 "unplausibeler_Datensatz" 3 "Diagnose_noch_nicht_beendet" ;
VAL_ 1526 SCR_Steuergeraet_Defekt_Status 0 "kein_Fehler" 1 "Steuergeraet_defekt" 2 "Steuergeraet_Stoerung_(temporaer)" 3 "Diagnose_noch_nicht_beendet" ;
VAL_ 2527679503 SCR_DEF_CAL_CVN_CRC_32 0 "Init" ;
VAL_ 2527679503 SCR_Temp_DEF_Hinweis 0 "kein Hinweis" 1 "SCR_DEF_Temp_high " 2 "SCR_DEF_Temp_low" 3 "Hinweis noch nicht verfügbar" ;
VAL_ 2527679503 SCR_Level_Aktivtank_saturated 0 "maximaler erfassbarer Füllstand nicht erreicht" 1 "maximalerer erfassbarer Füllstand erreicht" ;
VAL_ 2527679503 SCR_QBit_Qualitaet_Aktivtank 0 "gueltiger_Wert" 1 "Ersatz_Init_oder_Fehlerwert" ;
VAL_ 2527679503 SCR_QBit_Temp_DEF_Sensor_02 0 "gueltiger_Wert" 1 "Ersatz_Init_oder_Fehlerwert" ;
VAL_ 2527679503 SCR_Sent_Qualitaet_Aktivtank 253 "Sensor nicht verbaut" 254 "Init" ;
VAL_ 2527679503 SCR_Temperatur_DEF_Sensor 254 "Init" ;
VAL_ 2589283459 SCR_Tankheizung_P_effektiv 254 "Initwert" ;
VAL_ 2589283459 SCR_Tankheizkreis_P_Grenze 254 "Init" ;
VAL_ 2589283459 SCR_Heizkreis_3_P_effektiv 254 "Init" ;
VAL_ 2589283459 SCR_Heizkreis_3_P_Grenze 254 "Init" ;
VAL_ 2589283460 SCR_QBit_Temp_DEF2_Sensor 0 "gueltiger_Wert" 1 "Ersatz_Init_oder_Fehlerwert" ;
VAL_ 2589283460 SCR_Temp_DEF2_Sensor 254 "Init" ;
VAL_ 2589283460 SCR_DEF2_CAL_CVN_CRC_32 0 "Init" ;
VAL_ 2463978593 SCR_QBit_Level_kurz_Aktivtank 0 "gueltiger_Wert" 1 "Ersatz_Init_oder_Fehlerwert" ;
VAL_ 2463978593 SCR_Sent_Level_kurz_Aktivtank 1022 "Init" ;
VAL_ 2463978593 SCR_Dosierpumpe_Umdrehungen 254 "Init" 255 "Fehler" ;
VAL_ 2589283497 SCR_DEF2_CAL_ID_Index01 1145390640 "Init" ;
VAL_ 2589283497 SCR_DEF2_CAL_ID_Index02 808464432 "Init" ;
VAL_ 2589283498 SCR_DEF2_CAL_ID_Index03 808464432 "Init" ;
VAL_ 2589283498 SCR_DEF2_CAL_ID_Index04 808464432 "Init" ;
VAL_ 2589283413 SCR_DEF_CAL_ID_Index01 1145390640 "Init" ;
VAL_ 2589283413 SCR_DEF_CAL_ID_Index02 808464432 "Init" ;
VAL_ 2589283414 SCR_DEF_CAL_ID_Index03 808464432 "Init" ;
VAL_ 2589283414 SCR_DEF_CAL_ID_Index04 808464432 "Init" ;
VAL_ 980 BH_Blinker_li 0 "nicht_betaetigt" 1 "Blinkerhebel_Pos_li_betaetigt" ;
VAL_ 980 BH_Blinker_re 0 "nicht_betaetigt" 1 "Blinkerhebel_Pos_re_betaetigt" ;
VAL_ 980 BH_Lichthupe 0 "nicht_betaetigt" 1 "Blinkerhebel in Richtung Lichthupe betaetigt" ;
VAL_ 980 BH_Fernlicht 0 "nicht_betaetigt" 1 "Blinkerhebel_in_Richtung_Fernlicht_betaetigt" ;
VAL_ 980 WH_Tipwischen 0 "nicht_betaetigt" 1 "betaetigt" ;
VAL_ 980 WH_Intervall 0 "aus" 1 "Wischerhebel in Stellung Intervall" ;
VAL_ 980 WH_WischerStufe1 0 "aus" 1 "Wischerhebel in Stufe Wischen 1" ;
VAL_ 980 WH_WischerStufe2 0 "aus" 1 "Wischerhebel in Stufe Wischen 2" ;
VAL_ 980 WH_Frontwaschen 0 "aus" 1 "Wischerhebel in Stellung Wisch Wasch vorne" ;
VAL_ 980 WH_Heckintervall 0 "nicht_betaetigt" 1 "Wischerhebel in Stellung Heckintervall" ;
VAL_ 980 WH_Heckwaschen 0 "nicht_betaetigt" 1 "Wischerhebel in Stellung Wisch Wasch hinten" ;
VAL_ 980 WH_Intervallstufen 0 "Init / Default" 1 "Intervallstufe 1" 5 "Intervallstufe 2" 9 "Intervallstufe 3" 13 "Intervallstufe 4" 15 "Fehler" ;
VAL_ 980 FAS_Taster 0 "nicht_betaetigt" 1 "betaetigt" ;
VAL_ 980 FAS_Taster_Fehler 0 "kein_Fehler" 1 "Fehler" ;
VAL_ 980 SMLS_Hupe 0 "nicht_betaetigt" 1 "Hupe_gedrueckt" ;
VAL_ 980 LRH_On_Off 0 "LRH_aus__keine Anzeige" 1 "LRH_aus" 2 "LRH_ein" 3 "Fehler" ;
VAL_ 980 LRH_aktiv 0 "inaktiv" 1 "aktiv" ;
VAL_ 980 SMLS_P_verriegelt_plausibel 0 "unplausibel" 1 "plausibel" ;
VAL_ 980 WH_SRA 0 "SRA_Aus" 1 "SRA_Ein" ;
VAL_ 980 WH_Wischer_Fehler 0 "kein_Fehler" 1 "Fehler" ;
VAL_ 980 BH_Blinker_Fehler 0 "kein_Fehler" 1 "Fehler" ;
VAL_ 980 SMLS_PTT 0 "nicht_betaetigt" 1 "PTT_gedrueckt" ;
VAL_ 980 WH_Tipwischen_lang 0 "nicht_betaetigt" 1 "betaetigt" ;
VAL_ 1710 SP_FT_oben 0 "nicht_betaetigt" 1 "betaetigt" ;
VAL_ 1710 SP_FT_unten 0 "nicht_betaetigt" 1 "betaetigt" ;
VAL_ 1710 SP_FT_links 0 "nicht_betaetigt" 1 "betaetigt" ;
VAL_ 1710 SP_FT_rechts 0 "nicht_betaetigt" 1 "betaetigt" ;
VAL_ 1710 SP_BT_oben 0 "nicht_betaetigt" 1 "betaetigt" ;
VAL_ 1710 SP_BT_unten 0 "nicht_betaetigt" 1 "betaetigt" ;
VAL_ 1710 SP_BT_links 0 "nicht_betaetigt" 1 "betaetigt" ;
VAL_ 1710 SP_BT_rechts 0 "nicht_betaetigt" 1 "betaetigt" ;
VAL_ 1710 SP_abklappen 0 "Spiegel_abklappen_nicht_aktiv" 1 "Spiegel_abklappen_aktiv" ;
VAL_ 1710 SP_anklappen 0 "Spiegle_anklappen_nicht_aktiv" 1 "Spiegel_anklappen_aktiv" ;
VAL_ 1710 SP_normieren 0 "Spiegel_nicht_normiert" 1 "Spiegel_normiert" ;
VAL_ 1710 SP_Hzg_Taster 0 "nicht_betaetigt" 1 "betaetigt" ;
VAL_ 1710 SP_S_oben 1 "Spiegelschalter in Stellung oben" ;
VAL_ 1710 SP_S_unten 1 "Spiegelschalter in Stellung unten" ;
VAL_ 1710 SP_S_links 1 "Spiegelschalter in Stellung links" ;
VAL_ 1710 SP_S_rechts 1 "Spiegelschalter in Stellung rechts" ;
VAL_ 1710 SP_Auswahl_li 1 "Spiegelschalter in Stellung Auswahl links" ;
VAL_ 1710 SP_Auswahl_re 1 "Spiegelschalter in Stellung Auswahl rechts" ;
VAL_ 1710 SP_ARA_Status 0 "TSG nicht im ARA-Modus" 1 "TSG im ARA-Modus" ;
VAL_ 1710 SP_S_Klappen 1 "Spiegelschalter in Stellung Klappen" ;
VAL_ 1710 SP_Verstellschalter_Fehler 0 "kein_Fehler" 1 "Fehler" ;
VAL_ 1313 STH_Funk_ein 0 "kein Funkbefehl zum Einschalten" 1 "Funkbefehl zum Einschalten erhalten" ;
VAL_ 1313 STH_Funk_aus 0 "kein Funkbefehl" 1 "Funkbefehl zum Ausschalten erhalten" ;
VAL_ 1313 STH_Zusatzheizung 0 "Zuheizer aus" 1 "Zuheizer ein" ;
VAL_ 1313 STH_LED 0 "keine Rückmeldung" 1 "Rueckmeldung Standheizung in Betrieb" ;
VAL_ 1313 STH_Geblaese 0 "kein Einschaltbefehl an die Klimaanlage, Gebläse" 1 "Einschaltbefehl an die Klimaanlage, Gebläse" ;
VAL_ 1313 STH_EKP_Anst 0 "EKP nicht ansteuern" 1 "EKP ansteuern" ;
VAL_ 1313 STH_Start_folgt 0 "kein_Start_folgt" 1 "Start_folgt" ;
VAL_ 1313 STH_Ventil_Status 0 "Ventil_offen__grosser_Kreislauf" 1 "Ventil_geschlossen__kleiner_Kreislauf" ;
VAL_ 1313 STH_Fehler_ElWaPu 0 "kein_Fehler" 1 "Fehler" ;
VAL_ 1313 STH_Pumpen_Anf_extern 0 "nicht_angefordert" 1 "angefordert" ;
VAL_ 1313 STH_KL_HUP 0 "Aus" 1 "Ein" ;
VAL_ 1313 STH_Fehlerstatus 0 "kein_Fehler" 1 "Unterspannung" 2 "Tankfuellstand_zu_gering" 3 "Fehler_Betrieb_verhindert" 4 "Heizgeraet_verriegelt" 5 "Fehler_Betrieb_nicht_verhindert" 6 "Emissionsüberschreitung" ;
VAL_ 1313 STH_Wassertemp 254 "Init" 255 "Fehler" ;
VAL_ 1313 STH_Texte 0 "keine_Anzeige" 1 "Batteriemanagementeinschraenkung" 2 "Kraftstoffmangel" 3 "interner_Systemfehler" 4 "Heizzeitueberschreitung" ;
VAL_ 1313 STH_Motorvorwaermung 0 "keine Motorvorwärmung erfolgt" 1 "Aufheizung mit Motorvorwärmung erfolgt" ;
VAL_ 1313 STH_Servicemode 0 "Servicemode nicht aktiv" 1 "Servicemode aktiv" ;
VAL_ 1313 STH_war_aktiv 0 "war inaktiv" 1 "Standheizung war letzte halbe Stunde aktiv" ;
VAL_ 1313 STH_KVS_Ueberlauf 0 "kein Überlauf" 1 "Kraftstoffverbrauchssignal, mindestens ein Überlauf hat stattgefunden" ;
VAL_ 1313 STH_SH_ZH 0 "Heizgeraet_WZH" 1 "Heizgeraet_ZH" ;
VAL_ 1650 STH_ZZ_Monat 0 "Init" ;
VAL_ 1650 STH_ZZ_Tag 0 "Init" ;
VAL_ 1650 STH_ZZ_Betriebsmodus 0 "Don_t Care" 1 "ECO" 2 "Standard" 3 "Standard plus" 4 "Comfort" ;
VAL_ 1650 STH_ZZ_Status_Timer 0 "Don_t Care" 1 "Timer n.aktiv bzw loeschen" 2 "Timer aktiv/bzw aktivieren" ;
VAL_ 505 STP_Slave_Status 0 "STP_Slave_Init" 1 "STP_Slave_Deaktiviert" 2 "STP_Slave_Ready" 3 "Vorhalt" 4 "STP_Slave_Aktivierverhinderung" 5 "STP_Slave_Aktiv" 6 "STP_Slave_ESK_Uebernahme" 7 "STP_Slave_Uebergabe" 8 "STP_Slave_ESK0_Anf" 9 "STP_Slave_ESK1_Anf" 10 "STP_Slave_ESK2_Anf" 11 "STP_Slave_ESK3_Anf" 12 "STP_Slave_stabiler_Zustand" 13 "STP_Slave_Notlauf_Aktiv" 14 "STP_Slave_nicht_verfuegbar" 15 "STP_Slave_Error" ;
VAL_ 505 FZE_STP_Abschaltbedingung 0 "Vorhalt" 1 "STP_Abschaltbedingung_liegt_nicht_an" 2 "Vorhalt" 3 "STP_ESK0" 4 "STP_ESK1" 5 "STP_ESK2" 6 "STP_ESK3" 7 "STP_NL" ;
VAL_ 505 ACA_HF_Grund_AV_AB 0 "Liegt_nicht_an_oder_init" 1 "LRR_Kriterium" 2 "Fahrerbeobachtung" 3 "Fahrerlenkeingriff" 4 "Vorhalt" 5 "Vorhalt" 6 "Vorhalt" 7 "Vorhalt" ;
VAL_ 505 FZE_STP_Status 0 "Init" 1 "Ready" 2 "Fehler_reversible" 3 "Fehler_irreversible" ;
VAL_ 505 STP_Notlaufaktivierung 0 "Notlauf_nicht_angefordert" 1 "Notlauf_angefordert" ;
VAL_ 505 STP_Funktion_freigegeben 0 "nicht_freigegeben" 1 "freigegeben" ;
VAL_ 505 ACA_QF_Status_Anzeige 0 "ACA_QF_nicht_codiert" 1 "ACA_QF_INIT" 2 "ACA_QF_AUS" 3 "ACA_QF_PASSIV" 4 "ACA_QF_AKTIV" 5 "ACA_QF_UEBERLENKT" 6 "ACA_QF_Abschaltreaktion" 7 "ACA_QF_reversibler_Fehler" 8 "ACA_QF_irreversibler_Fehler" 9 "ACA_QF_Sensor_Blindheit" ;
VAL_ 505 ACF_SwuFahrerUnaufmerksam 0 "Swu_Fahrer_Nicht_unaufmerksam" 1 "Swu_Fahrer_unaufmerksam" ;
VAL_ 505 ACA_QF_Fahreruebernahme 0 "keine" 1 "Uebernahme_1" 2 "Uebernahme_2" 3 "Uebernahme_3" ;
VAL_ 505 ACA_HF_Status 0 "ACA_HF_nicht_codiert" 1 "ACA_HF_Init" 2 "ACA_HF_aus" 3 "ACA_HF_nicht_verfuegbar" 4 "ACA_HF_verfuegbar" 5 "ACA_HF_aktiv" 6 "Vorhalt" 7 "ACA_HF_reversibler_Fehler" 8 "ACA_HF_irreversibler_Fehler" 9 "ACA_HF_Uebernahme_1" 10 "ACA_HF_Uebernahme_2" 11 "Vorhalt" 12 "Vorhalt" 13 "Vorhalt" 14 "Vorhalt" 15 "Vorhalt" ;
VAL_ 505 FZE_Spurwechsel_erkannt_li 0 "kein_Spurwechsel_erkannt" 1 "Spurwechsel_erkannt_links" ;
VAL_ 505 FZE_Spurwechsel_erkannt_re 0 "kein_Spurwechsel_erkannt" 1 "Spurwechsel_erkannt_rechts" ;
VAL_ 505 ACF_Spurwechsel_moeglich 0 "keine_Spurwechselmoeglichkeit_vorhanden" 1 "Spurwechselmoeglichkeit_vorhanden" ;
VAL_ 505 ACF_Spurwechsel_wahrscheinlich 0 "kein_Spurwechsel" 1 "Spurwechsel_wahrscheinlich" ;
VAL_ 505 FZE_STP_Aktivierverhinderung 0 "liegt_nicht_an" 1 "Fahrer_nicht_erkannt" 2 "Vorhalt" 3 "Vorhalt" ;
VAL_ 783 SWA_Anzeigen 0 "keine_Anzeige" 1 "Text_1_SWA_zurzeit_nicht_verfuegbar" 2 "Text_2_SWA_Systemstoerung" 3 "Text_3_SWA_zurzeit_nicht_verfuegbar_Keine_Sensorsicht" 4 "Text_4_SWA_zurzeit_nicht_verfuegbar_Anhaengerbetrieb" 5 "Text_5_SWA_Eskalation" 6 "Text_6_SWA_eingeschränkt" ;
VAL_ 783 SWA_Blindheit_erkannt 0 "nicht erkannt" 1 "erkannt" ;
VAL_ 783 SWA_rel_Nichtverf 0 "verfuegbar" 1 "nicht verfuegbar" ;
VAL_ 783 SWA_rel_Fehler 0 "kein Fehler" 1 "Fehler" ;
VAL_ 783 SWA_Sta_aktiv 0 "Aus" 1 "Ein" ;
VAL_ 783 SWA_Sta_passiv 0 "Aus" 1 "Ein" ;
VAL_ 783 SWA_FT_RueckLED 0 "inaktiv" 1 "aktiv" ;
VAL_ 783 ASW_Status 0 "Passiv" 1 "Aktiv" 2 "Fehler" 3 "AUS" ;
VAL_ 783 SWA_Standziele_li 0 "Abstand i.O." 1 "Abstand zu gering" ;
VAL_ 783 SWA_Kolonne_li 0 "zwei_oder_weniger_Fahrzeuge_auf_der_Spur" 1 "mehr_als_zwei_Fahrzeuge_auf_der_Spur" ;
VAL_ 783 SWA_Infostufe_SWA_li 0 "keine_Aktion" 1 "Aktion" ;
VAL_ 783 SWA_Warnung_SWA_li 0 "keine Warnung" 1 "Warnung aktiv" ;
VAL_ 783 ASW_Warnung_FS 0 "inaktiv" 1 "aktiv" ;
VAL_ 783 ASW_Warnung_BFS 0 "inaktiv" 1 "aktiv" ;
VAL_ 783 ASW_Kombitexte 0 "keine Anzeige.    //    Prio 5" 1 "Text_1_ASW_zur_Zeit_nicht_verfuegbar_und_Akustik    //    Prio 2" 2 "Text_2_ASW_Systemfehler_und_Akustik    //    Prio 1" 3 "Text_3_ASW_Sensor_blockiert_und_Akustik    //    Prio 3" 4 "Text_4_ASW_im_Anhaengerbetrieb_nicht_verfuegbar_und_Akustik    //    Prio 4" 5 "Text_5_ASW_Warnung_FS_und_Akustik" 6 "Text_6_ASW_Warnung_BFS_und_Akustik" 7 "Text_7_ASW_aus" ;
VAL_ 783 SWA_Kolonne_mi 0 "zwei_oder_weniger_Fahrzeuge_auf_der_Spur" 1 "mehr_als_zwei_Fahrzeuge_auf_der_Spur" ;
VAL_ 783 ASW_Modus 0 "kein_Fehler_KL15" 1 "kein_Fehler_KL30" 2 "reserve" 3 "Anhaengerbetrieb" 4 "Init_nicht_codiert" 5 "keine_Sensorsicht_blindheit" 6 "Zur_zeit_nicht_verfuegbar_temp_Fehler" 7 "Systemstoerung_dauer_fehler" ;
VAL_ 783 SWA_Modus 0 "kein_Fehler_verfuegbar" 1 "kein_Fehler_eingeschr_Reichweite" 2 "reserve" 3 "Anhaengerbetrieb" 4 "Init_nicht_codiert" 5 "keine_Sensorsicht_blindheit" 6 "Zur_zeit_nicht_verfuegbar_temp_Fehler" 7 "Systemstoerung_dauer_fehler" ;
VAL_ 783 SWA_Standziele_re 0 "Abstand i.O." 1 "Abstand zu gering" ;
VAL_ 783 SWA_Kolonne_re 0 "zwei_oder_weniger_Fahrzeuge_auf_der_Spur" 1 "mehr_als_zwei_Fahrzeuge_auf_der_Spur" ;
VAL_ 783 SWA_Infostufe_SWA_re 0 "keine_Aktion" 1 "Aktion" ;
VAL_ 783 SWA_Warnung_SWA_re 0 "keine Warnung" 1 "Warnung aktiv" ;
VAL_ 783 HRE_Anzeigetexte 0 "keine_Anzeige" 1 "BSD_RTA_zZt_nicht_verfuegbar" 2 "BSD_RTA_Systemfehler" 3 "BSD_RTA_Sensor_blockiert" 4 "BSD_RTA_Anhaengerbetrieb" 5 "RTA_Warnung" 6 "BSD_Warnung" 7 "Fahreruebernahme_Notbremsung" 8 "RTA_nicht_verfuegbar" 9 "BSD_RTA_ASW_zZt_nicht_verfuegbar" 10 "BSD_RTA_ASW_Systemfehler" 11 "BSD_RTA_ASW_Sensor_blockiert" 12 "BSD_RTA_ASW_Anhaengerbetrieb" ;
VAL_ 783 SWA_Status_02 0 "aus" 1 "passiv" 2 "aktiv" 3 "Fehler" ;
VAL_ 783 Heckradar_Kombitexte 0 "keine Anzeige.    //    Prio 5" 1 "Text_1_SWA_und_ASW_zur_Zeit_nicht_verfuegbar_und_Akustik    //    Prio 2" 2 "Text_2_SWA_und_ASW_Systemfehler_und_Akustik    //    Prio 1" 3 "Text_3_SWA_und_ASW_Sensor_blockiert_und_Akustik    //    Prio 3" 4 "Text_4_SWA_und_ASW_im_Anhaengerbetrieb_nicht_verfuegbar_und_Akustik    //    Prio 4" 5 "Text_1_SWA_und_RCTA_zur_Zeit_nicht_verfuegbar_und_Akustik // Prio 2" 6 "Text_2_SWA_und_RCTA_Systemfehler_und_Akustik // Prio 1" 7 "		Text_3_SWA_und_RCTA_Sensor_blockiert_und_Akustik // Prio 3" 8 "Text_4_SWA_und_RCTA_im_Anhaengerbetrieb_nicht_verfuegbar_und_Akustik // Prio 4" 9 "Text_1_ASW_und_RCTA_zur_Zeit_nicht_verfuegbar_und_Akustik // Prio 2" 10 "Text_2_ASW_und_RCTA_Systemfehler_und_Akustik // Prio 1" 11 "Text_3_ASW_und_RCTA_Sensor_blockiert_und_Akustik // Prio 3" 12 "Text_4_ASW_und_RCTA_im_Anhaengerbetrieb_nicht_verfuegbar_und_Akustik // Prio 4" 13 "Text_1_SWA_und_ASW_und_RCTA_zur_Zeit_nicht_verfuegbar_und_Akustik // Prio 2" 14 "Text_2_SWA_und_ASW_und_RCTA_Systemfehler_und_Akustik // Prio 1" 15 "Text_3_SWA_und_ASW_und_RCTA_Sensor_blockiert_und_Akustik // Prio 3" 16 "Text_4_SWA_und_ASW_und_RCTA_im_Anhaengerbetrieb_nicht_verfuegbar_und_Akustik // Prio 4" 17 "reserviert" 18 "reserviert" 19 "reserviert" 20 "reserviert" 21 "reserviert" 22 "reserviert" 23 "reserviert" 24 "reserviert" 25 "reserviert" 26 "reserviert" 27 "reserviert" 28 "reserviert" 29 "reserviert" ;
VAL_ 783 RCTA_Kombitexte 0 "keine_Anzeige" 1 "RCTA_zur_Zeit_nicht_verfuegbar" 2 "RCTA_Systemfehler" 3 "RCTA_Sensor_blockiert" 4 "RCTA_im_Anhaengerbetrieb" 5 "RTA_Warnung" 6 "Fahreruebernahme_Notbremsung" 7 "Eingeschraenkt_verfuegbar_ESCaus" ;
VAL_ 673 SWA_LED_Hell_BFS 126 "Init" 127 "Fehler" ;
VAL_ 673 SWA_LED_Hell_FS 126 "Init" 127 "Fehler" ;
VAL_ 673 SWA_LED_Modus_BFS 0 "LED_aus" 1 "Infostufe" 2 "Warnstufe" 3 "Aufpruefen_Kl15" 4 "Aufpruefen_BAP" ;
VAL_ 673 SWA_LED_Modus_FS 0 "LED_aus" 1 "Infostufe" 2 "Warnstufe" 3 "Aufpruefen_Kl15" 4 "Aufpruefen_BAP" ;
VAL_ 1413 SI_Sammel_SG_Fehler 61 "Reserviert" 62 "Overflow" 63 "ungueltig" ;
VAL_ 1413 SI_Diagnose_Aktiv 0 "inaktiv" 1 "aktiv" ;
VAL_ 1413 SI_QRS_Mode 0 "QRS_Messmodus_nicht_aktiv" 1 "QRS_Messmodus_aktiv" ;
VAL_ 1413 SI_T_Mode 0 "Transportmodus_nicht_aktiv" 1 "Transportmodus_aktiv" ;
VAL_ 1413 SI_NWDF 0 "Ueberwachung_nicht_freigegeben" 1 "Ueberwachung_freigegeben" ;
VAL_ 1413 SI_NWDF_gueltig 0 "NWDF_wird_nicht_unterstuetzt" 1 "NWDF_wird_unterstuetzt" ;
VAL_ 1413 SI_Sammelfehler 0 "kein_Sammelfehler" 1 "Sammelfehler" ;
VAL_ 1413 GW_KD_Fehler 0 "kein_KD_Fehler" 1 "KD_Fehler" ;
VAL_ 1413 SI_T_Schutz 0 "Transportschutz_nicht_aktiv" 1 "Transportschutz_aktiv" ;
VAL_ 1413 SI_BUS_01 0 "keine_Busruhe" 1 "Busruhe" ;
VAL_ 1413 SI_BUS_02 0 "keine_Busruhe" 1 "Busruhe" ;
VAL_ 1413 SI_BUS_03 0 "keine_Busruhe" 1 "Busruhe" ;
VAL_ 1413 SI_BUS_04 0 "keine_Busruhe" 1 "Busruhe" ;
VAL_ 1413 SI_BUS_05 0 "keine_Busruhe" 1 "Busruhe" ;
VAL_ 1413 SI_BUS_06 0 "keine_Busruhe" 1 "Busruhe" ;
VAL_ 1413 SI_BUS_07 0 "keine_Busruhe" 1 "Busruhe" ;
VAL_ 1413 SI_BUS_08 0 "keine_Busruhe" 1 "Busruhe" ;
VAL_ 1413 SI_BUS_09 0 "keine_Busruhe" 1 "Busruhe" ;
VAL_ 1413 SI_BUS_10 0 "keine_Busruhe" 1 "Busruhe" ;
VAL_ 1413 SI_BUS_11 0 "keine_Busruhe" 1 "Busruhe" ;
VAL_ 1413 SI_BUS_12 0 "keine_Busruhe" 1 "Busruhe" ;
VAL_ 1413 SI_BUS_13 0 "keine_Busruhe" 1 "Busruhe" ;
VAL_ 1413 SI_BUS_14 0 "keine_Busruhe" 1 "Busruhe" ;
VAL_ 1413 SI_BUS_15 0 "keine_Busruhe" 1 "Busruhe" ;
VAL_ 1413 SI_Bus_Identifikation 16 "CAN_Diagnose" 17 "CAN_Antrieb" 18 "CAN_Komfort" 19 "CAN_Infotainment" 20 "CAN_Fahrwerk" 21 "CAN_Extended" 22 "CAN_Hybrid" 23 "CAN_Lade" 24 "CAN_Kombi" 25 "CAN_Komfort_2" 26 "CAN_AFS" 27 "CAN_MIB" 33 "CAN_FahrerAssistenzSysteme" 34 "CAN_Migration" 35 "CAN_Connect" 36 "CAN_AnzeigeBedienung" 37 "CAN_ElectricalVehicle" 40 "CAN_Telematik" 41 "CAN_MFL" 42 "CAN_FahrerAssistenzSysteme_2" 47 "CAN_Komfort_3" 48 "FlexRay_A" 49 "FlexRay_B" 97 "VLAN_FAS" 98 "VLAN_Infotainment" 99 "VLAN_Connect" 100 "VLAN_Komfort" 101 "VLAN_Antrieb" 102 "VLAN_Diagnose" 103 "VLAN_Internet" 104 "VLAN_Gateway" 105 "VLAN_Remote_FC" 106 "VLAN_Connect_2" 107 "VLAN_Licht" 108 "VLAN_Charge" 109 "VLAN_Cockpit" 176 "HCP1_CANFD01" 177 "HCP1_CANFD02" 178 "HCP1_CANFD03" 179 "HCP1_CANFD04" 180 "HCP1_CANFD05" 181 "HCP1_CANFD06" 182 "HCP1_CANFD07" 183 "HCP1_CANFD08" 186 "HCP4_CANFD03" 187 "HCP4_CANFD04" 188 "HCP1_CANFD09" 189 "HCP4_CANFD06" 190 "HCP4_CANFD07" 191 "HCP4_CANFD08" 192 "HCP4_CANFD09" 193 "HCP4_CANFD10" 194 "HCP1_CANFD10" 195 "ICAS1_CANFD2_HCP5_CANFD02" 196 "HCP1_CANFD11" 197 "WU_HCP1_CANFD" 199 "WU_HCP2_CANFD" 200 "WU_HCP3_CANFD" 201 "WU_HCP4_CANFD" 202 "HCP3_CANFD02" 204 "ESC_CANFD" 205 "HCP4_CANFD11" 206 "HCP4_CANFD12" 207 "HCP5_CANFD04" 208 "HCP5_CANFD05" 212 "WU_ConMod_CANFD" 213 "WU_PASD_CANFD" 215 "CAN_MobileDeviceKey" ;
VAL_ 1413 SI_CAB 0 "inaktiv" 1 "CAB_01__Tueren" 2 "CAB_02__Anhaenger" 4 "CAB_03__Nightvision" 8 "CAB_04__Sitzverstellung" 16 "CAB_05__Klappen" 32 "CAB_06__Infotainment" 64 "CAB_07__Sub_Infotainment" 128 "CAB_08__Anzeige" 256 "CAB_09__Laden" 512 "CAB_10__Klima" 1024 "CAB_11__FlexRay" 262144 "CAB_19_VLAN_Remote_FC" 524288 "CAB_20_VLAN_Komfort" 1048576 "CAB_21_VLAN_Internet" 2097152 "CAB_22_VLAN_Connect" 4194304 "CAB_23_VLAN_Infotainment" 8388608 "CAB_24_VLAN_FAS" ;
VAL_ 1375 TME_VoKo_Strategie_Anzeige 0 "Inaktiv" 1 "Standby" 2 "Lueften_elektrisch" 3 "Lueften_konventionell" 4 "Kuehlen_elektrisch" 5 "Reheat_elektrisch" 6 "Heizen_elektrisch" 7 "Heizen_verbrennungstechnisch" 8 "Reserve" 14 "Init" 15 "Fehler" ;
VAL_ 1375 TME_Zuheizer_Freigabe 0 "keine_Freigabe" 1 "Freigabe" ;
VAL_ 1375 TME_AC_LED 0 "LED_aus" 1 "LED_ein" ;
VAL_ 1375 TME_Heizstrategie 0 "Init" 1 "Aus" 2 "Spuelen" 3 "Kanalkuehlung" 4 "Kuehhlwasserzirkulation" 5 "aktive_Kuehlung" 6 "Heizen" 7 "Reheat" 8 "Heizen_elektrisch" 9 "Heizen_verbrennungstechnisch" 10 "Konditionierung_n_moeglich" 11 "Heizstrategie_11" 12 "Heizstrategie_12" 13 "Heizstrategie_13" 14 "Heizstrategie_14" 15 "Fehler" ;
VAL_ 1375 TME_Systemstatus 0 "System_IO" 1 "System_reduziert__Akkustik" 2 "System_reduziert__HV_Management" 3 "Fehler" ;
VAL_ 1375 TME_Kbr_Innenraum 0 "nicht_verfuegbar" 1 "verfuegbar" ;
VAL_ 1375 TME_Freigabe_Vorkond 0 "keine_Freigabe" 1 "Freigabe" ;
VAL_ 1375 TME_Verdampfer_Status 0 "inaktiv" 1 "aktiv" ;
VAL_ 1375 TME_Kuehlmittel_Sensor 0 "Kuehlkreis_OK" 1 "Kuehlmittelmangel_Pumpenfehler" ;
VAL_ 1375 TME_AC_Rueckmeldung 0 "EKK_laeuft_nicht" 1 "EKK_laeuft_reduziert" 2 "EKK_laeuft" 3 "Fehler" ;
VAL_ 1375 TME_Heizungspumpen_Anst 13 "Fehler" 14 "Init" 15 "nicht_verbaut" ;
VAL_ 1375 TME_Frischluftklappe_Soll 126 "Init" 127 "Fehler" ;
VAL_ 1375 TME_Freigabe_Luft_PTC 0 "keine_Freigabe" 1 "Freigabe" ;
VAL_ 1375 TME_Umluftklappe_Soll 126 "Init" 127 "Fehler" ;
VAL_ 1375 TME_Waermepumpe_aktiv 0 "inaktiv" 1 "aktiv" ;
VAL_ 1375 TME_Absperrventil1_oeffnen 0 "nicht_verfuegbar" 1 "Ansteuerung_Ventil_zulaessig" 2 "Ventil_oeffnen_oder_geoeffnet" 3 "Ventil_schliessen_oder_geschlossen" ;
VAL_ 1375 TME_Klima_Defizit 254 "Init" 255 "Fehler" ;
VAL_ 1375 TME_Temp_KM_vor_HWT 254 "Init" 255 "Fehler" ;
VAL_ 2527679762 TPUI_WarnLvlCmft 0 "160_kmh" 1 "170_kmh" 2 "180_kmh" 3 "190_kmh" 4 "200_kmh" 5 "210_kmh" 6 "240_kmh" 7 "250_kmh" 8 "270_kmh" 9 "290_kmh" 10 "300_kmh" 11 "310_kmh" 14 "Init" 15 "Fehler" ;
VAL_ 2527679762 TPUI_WarnLvlMaxV 0 "200_kmh" 1 "210_kmh" 2 "220_kmh" 3 "230_kmh" 4 "240_kmh" 5 "250_kmh" 6 "260_kmh" 7 "270_kmh" 8 "280_kmh" 9 "290_kmh" 10 "300_kmh" 11 "310_kmh" 14 "Init" 15 "Fehler" ;
